VERSION "HNNBNNNYNNNNNNNNNNNNNNNNNNNNNNNNNNNNNNNNNN/4/%%%/4/'%**4NNN///"

NS_ :

BS_:

BU_: New_Node_10 BAP_Tester Fahrerdisplay_Kombi HUD ICAS1_X_Gateway ICAS3_Gateway ICC_IO_Node Kombi SmartLight_01 ZR_MIB_TOP_ab_Gen3

BO_ 1153 MainUnit_01: 8 ICAS3_Gateway
 SG_ ZR_LoGeWa_Event_Kombiwarnung : 0|4@1+ (1,0) [0|15] ""  ICAS1_X_Gateway,Kombi
 SG_ Nav_FoD_Status : 4|3@1+ (1,0) [0|7] ""  ICAS1_X_Gateway,Kombi
 SG_ MIB_ASW_Diagnose : 7|1@1+ (1,0) [0|1] ""  ICAS1_X_Gateway
 SG_ ZR_Lichter_Tag : 8|1@1+ (1,0) [0|1] ""  ICAS1_X_Gateway
 SG_ MIB_Tongenerator_PH_verfuegbar : 9|3@1+ (1,0) [0|7] ""  ICAS1_X_Gateway
 SG_ MMI_Counter_Bedienevent : 12|4@1+ (1,0) [0|15] ""  ICAS1_X_Gateway
 SG_ DSSS_Warning : 16|5@1+ (1,0) [0|31] ""  ICAS1_X_Gateway
 SG_ ZR_Kindersicherung_RSE : 21|1@1+ (1,0) [0|1] ""  ICAS1_X_Gateway
 SG_ ZR_RSE_aktivieren : 22|1@1+ (1,0) [0|1] ""  ICAS1_X_Gateway
 SG_ MMI_SDS_aktiv : 23|1@1+ (1,0) [0|1] ""  ICAS1_X_Gateway
 SG_ MU_SecondDisplay : 24|3@1+ (1,0) [0|7] ""  ICAS1_X_Gateway
 SG_ MMI_Telefon_aktiv : 27|1@1+ (1,0) [0|1] ""  ICAS1_X_Gateway
 SG_ MMI_Gurt_Mic_ref : 28|1@1+ (1,0) [0|1] ""  ICAS1_X_Gateway
 SG_ ZR_AppConnect_Zustand : 31|1@1+ (1,0) [0|1] ""  ICAS1_X_Gateway
 SG_ MU_Update_Time : 32|8@1+ (0.1,0) [0|25.5] "Unit_Hours"  ICAS1_X_Gateway
 SG_ HMI_WLC1_Systemzustand_intern : 40|3@1+ (1,0) [0|7] ""  ICAS1_X_Gateway
 SG_ HMI_WLC2_Systemzustand_intern : 43|3@1+ (1,0) [0|7] ""  ICAS1_X_Gateway
 SG_ ZR_Parken_Sondermodus : 48|4@1+ (1,0) [0|15] ""  ICAS1_X_Gateway
 SG_ INF_Nachlaufzeit : 52|10@1+ (1,0) [0|509] "Unit_Minut"  ICAS1_X_Gateway

BO_ 1639 Mem_BFS_01: 8 ICAS1_X_Gateway
 SG_ BFS_Fond_Bed_Ack : 12|1@1+ (1,0) [0|1] "" Vector__XXX
 SG_ BFS_Lehne_nicht_verriegelt : 13|1@1+ (1,0) [0|1] "" Vector__XXX
 SG_ BFS_Klapptisch_offen : 14|1@1+ (1,0) [0|1] "" Vector__XXX
 SG_ BFS_Gurtbringer_Sperre : 15|1@1+ (1,0) [0|1] "" Vector__XXX
 SG_ BFS_Sitzsym_Fahrt_aktiv : 16|1@1+ (1,0) [0|1] "" Vector__XXX
 SG_ BFS_Sitzfahrt_aktiv : 17|1@1+ (1,0) [0|1] "" Vector__XXX
 SG_ BFS_SLV_aktiv : 18|1@1+ (1,0) [0|1] "" Vector__XXX
 SG_ BFS_SHV_aktiv : 19|1@1+ (1,0) [0|1] "" Vector__XXX
 SG_ BFS_LNV_aktiv : 20|1@1+ (1,0) [0|1] "" Vector__XXX
 SG_ BFS_SNV_aktiv : 21|1@1+ (1,0) [0|1] "" Vector__XXX
 SG_ BFS_KSV_aktiv : 22|1@1+ (1,0) [0|1] "" Vector__XXX
 SG_ BFS_LKV_aktiv : 23|1@1+ (1,0) [0|1] "" Vector__XXX
 SG_ BFS_STV_aktiv : 24|1@1+ (1,0) [0|1] "" Vector__XXX
 SG_ BFS_LHV_aktiv : 25|1@1+ (1,0) [0|1] "" Vector__XXX
 SG_ BFS_LWV_aktiv : 26|1@1+ (1,0) [0|1] "" Vector__XXX
 SG_ BFS_GHV_aktiv : 27|1@1+ (1,0) [0|1] "" Vector__XXX
 SG_ BFS_KSS_Fahrt_aktiv : 28|1@1+ (1,0) [0|1] "" Vector__XXX
 SG_ BFS_MMB_lokal_Stop : 29|1@1+ (1,0) [0|1] "" Vector__XXX
 SG_ BFS_Ruhestellung_Status : 30|1@1+ (1,0) [0|1] "" Vector__XXX
 SG_ BFS_Seat_Locked : 31|1@1+ (1,0) [0|1] "" Vector__XXX
 SG_ BFS_MMB_storage : 32|4@1+ (1,0) [0|15] "" Vector__XXX
 SG_ BFS_MMB_tipp : 36|1@1+ (1,0) [0|1] "" Vector__XXX
 SG_ BFS_MMB_tast : 37|1@1+ (1,0) [0|1] "" Vector__XXX
 SG_ BFS_MMB_store_LED_on : 38|1@1+ (1,0) [0|1] "" Vector__XXX
 SG_ BFS_MMB_storage_beep : 39|1@1+ (1,0) [0|1] ""  Kombi
 SG_ BFS_MMB_store : 40|1@1+ (1,0) [0|1] "" Vector__XXX
 SG_ BFS_MMB_glob_stop : 41|1@1+ (1,0) [0|1] "" Vector__XXX
 SG_ BFS_FSV_ausgeklappt : 42|1@1+ (1,0) [0|1] "" Vector__XXX

BO_ 1178 Mem_FS_01: 8 ICAS1_X_Gateway
 SG_ FS_Fond_Bed_enable : 12|1@1+ (1,0) [0|1] "" Vector__XXX
 SG_ FS_Lehne_nicht_verriegelt : 13|1@1+ (1,0) [0|1] "" Vector__XXX
 SG_ FS_Spezialposition_anfahren : 14|1@1+ (1,0) [0|1] "" Vector__XXX
 SG_ FS_Gurtbringer_Sperre : 15|1@1+ (1,0) [0|1] "" Vector__XXX
 SG_ FS_BFS_Sitzsym_Anfahrt : 16|1@1+ (1,0) [0|1] "" Vector__XXX
 SG_ FS_Sitzfahrt_aktiv : 17|1@1+ (1,0) [0|1] "" Vector__XXX
 SG_ FS_SLV_aktiv : 18|1@1+ (1,0) [0|1] "" Vector__XXX
 SG_ FS_SHV_aktiv : 19|1@1+ (1,0) [0|1] "" Vector__XXX
 SG_ FS_LNV_aktiv : 20|1@1+ (1,0) [0|1] "" Vector__XXX
 SG_ FS_SNV_aktiv : 21|1@1+ (1,0) [0|1] "" Vector__XXX
 SG_ FS_KSV_aktiv : 22|1@1+ (1,0) [0|1] "" Vector__XXX
 SG_ FS_LKV_aktiv : 23|1@1+ (1,0) [0|1] "" Vector__XXX
 SG_ FS_STV_aktiv : 24|1@1+ (1,0) [0|1] "" Vector__XXX
 SG_ FS_LHV_aktiv : 25|1@1+ (1,0) [0|1] "" Vector__XXX
 SG_ FS_LWV_aktiv : 26|1@1+ (1,0) [0|1] "" Vector__XXX
 SG_ FS_GHV_aktiv : 27|1@1+ (1,0) [0|1] "" Vector__XXX
 SG_ FS_BFS_KSS_Anfahrt : 28|1@1+ (1,0) [0|1] "" Vector__XXX
 SG_ FS_MMB_lokal_Stop : 29|1@1+ (1,0) [0|1] "" Vector__XXX
 SG_ FS_MMB_storage : 32|4@1+ (1,0) [0|15] "" Vector__XXX
 SG_ FS_MMB_tipp : 36|1@1+ (1,0) [0|1] "" Vector__XXX
 SG_ FS_MMB_tast : 37|1@1+ (1,0) [0|1] "" Vector__XXX
 SG_ FS_MMB_store_LED_on : 38|1@1+ (1,0) [0|1] "" Vector__XXX
 SG_ FS_MMB_storage_beep : 39|1@1+ (1,0) [0|1] ""  Kombi
 SG_ FS_MMB_store : 40|1@1+ (1,0) [0|1] "" Vector__XXX
 SG_ FS_MMB_glob_stop : 41|1@1+ (1,0) [0|1] "" Vector__XXX
 SG_ FS_EE_Fond_FS_enable : 42|1@1+ (1,0) [0|1] "" Vector__XXX
 SG_ FS_EE_Fond_BFS_enable : 43|1@1+ (1,0) [0|1] "" Vector__XXX
 SG_ FS_BFS_Fond_Verst_enable : 44|1@1+ (1,0) [0|1] "" Vector__XXX
 SG_ FS_EE_BFS_enable : 45|1@1+ (1,0) [0|1] "" Vector__XXX

BO_ 1171 MFG_01: 8 ICAS1_X_Gateway
 SG_ MFG_01_CRC : 0|8@1+ (1,0) [0|255] "" Vector__XXX
 SG_ MFG_01_BZ : 8|4@1+ (1,0) [0|15] "" Vector__XXX
 SG_ MF_ZV_Lock : 12|1@1+ (1,0) [0|1] "" Vector__XXX
 SG_ MF_Motorweiterlauf : 13|1@1+ (1,0) [0|1] "" Vector__XXX
 SG_ MF_Abzugssperre : 14|1@1+ (1,0) [0|1] "" Vector__XXX
 SG_ MF_Anlassersperre : 15|1@1+ (1,0) [0|1] "" Vector__XXX
 SG_ MF_Variante : 16|3@1+ (1,0) [0|7] "" Vector__XXX
 SG_ MF_Schluessel_scan : 19|1@1+ (1,0) [0|1] "" Vector__XXX
 SG_ MF_Laderelais : 20|1@1+ (1,0) [0|1] "" Vector__XXX
 SG_ MF_StartStopp_Info : 21|2@1+ (1,0) [0|3] "" Vector__XXX
 SG_ MF_Fernbed_ein : 23|1@1+ (1,0) [0|1] "" Vector__XXX
 SG_ MF_Standlicht : 24|1@1+ (1,0) [0|1] "" Vector__XXX
 SG_ MF_Fahrlicht : 25|1@1+ (1,0) [0|1] "" Vector__XXX
 SG_ MF_interm_Fernlicht : 26|1@1+ (1,0) [0|1] "" Vector__XXX
 SG_ MF_Warnblinker : 27|1@1+ (1,0) [0|1] "" Vector__XXX
 SG_ MF_Fussraumbel : 28|1@1+ (1,0) [0|1] "" Vector__XXX
 SG_ MF_Innenraumbel : 29|1@1+ (1,0) [0|1] "" Vector__XXX
 SG_ MF_Innenraumbel_Unterdrueck : 30|1@1+ (1,0) [0|1] ""  SmartLight_01
 SG_ MF_Notstart : 31|1@1+ (1,0) [0|1] "" Vector__XXX
 SG_ MF_Blk_li : 32|1@1+ (1,0) [0|1] "" Vector__XXX
 SG_ MF_Blk_re : 33|1@1+ (1,0) [0|1] "" Vector__XXX
 SG_ MF_Lichthupe : 34|1@1+ (1,0) [0|1] "" Vector__XXX
 SG_ MF_Fernlicht : 35|1@1+ (1,0) [0|1] "" Vector__XXX
 SG_ MF_HFS_verriegeln : 36|1@1+ (1,0) [0|1] "" Vector__XXX
 SG_ MF_HFS_entriegeln : 37|1@1+ (1,0) [0|1] "" Vector__XXX
 SG_ MF_HBFS_verriegeln : 38|1@1+ (1,0) [0|1] "" Vector__XXX
 SG_ MF_HBFS_entriegeln : 39|1@1+ (1,0) [0|1] "" Vector__XXX
 SG_ MF_Tippwischen : 40|1@1+ (1,0) [0|1] "" Vector__XXX
 SG_ MF_Frontintervall : 41|1@1+ (1,0) [0|1] "" Vector__XXX
 SG_ MF_Wischerstufe_1 : 42|1@1+ (1,0) [0|1] "" Vector__XXX
 SG_ MF_Wischerstufe_2 : 43|1@1+ (1,0) [0|1] "" Vector__XXX
 SG_ MF_Frontwaschen : 44|1@1+ (1,0) [0|1] "" Vector__XXX
 SG_ MF_nachtr_Stopp_Anf : 45|1@1+ (1,0) [0|1] "" Vector__XXX
 SG_ MF_Heckintervall : 46|1@1+ (1,0) [0|1] "" Vector__XXX
 SG_ MF_Heckwaschen : 47|1@1+ (1,0) [0|1] "" Vector__XXX
 SG_ MF_Summer : 48|1@1+ (1,0) [0|1] ""  Kombi
 SG_ MF_Alarm_Blinkertakt : 49|1@1+ (1,0) [0|1] "" Vector__XXX
 SG_ MF_Alarm_Blinker : 50|1@1+ (1,0) [0|1] "" Vector__XXX
 SG_ MF_TFL_Abschaltung : 51|1@1+ (1,0) [0|1] "" Vector__XXX
 SG_ MF_interm_Takt : 52|1@1+ (1,0) [0|1] "" Vector__XXX
 SG_ MF_Tuerentriegelung_hinten : 53|1@1+ (1,0) [0|1] "" Vector__XXX
 SG_ MF_interm_Fahrlicht : 54|1@1+ (1,0) [0|1] "" Vector__XXX
 SG_ MF_Signalhorn : 55|1@1+ (1,0) [0|1] "" Vector__XXX
 SG_ MF_FH_FT_hoch : 56|1@1+ (1,0) [0|1] "" Vector__XXX
 SG_ MF_FH_FT_tief : 57|1@1+ (1,0) [0|1] "" Vector__XXX
 SG_ MF_FH_BT_hoch : 58|1@1+ (1,0) [0|1] "" Vector__XXX
 SG_ MF_FH_BT_tief : 59|1@1+ (1,0) [0|1] "" Vector__XXX
 SG_ MF_FT_verriegeln : 60|1@1+ (1,0) [0|1] "" Vector__XXX
 SG_ MF_FT_entriegeln : 61|1@1+ (1,0) [0|1] "" Vector__XXX
 SG_ MF_BT_verriegeln : 62|1@1+ (1,0) [0|1] "" Vector__XXX
 SG_ MF_BT_entriegeln : 63|1@1+ (1,0) [0|1] "" Vector__XXX

BO_ 1164 MFG_03: 8 ICAS1_X_Gateway
 SG_ MFG_Klappe_Status : 13|3@1+ (1,0) [0|7] "" Vector__XXX
 SG_ MF_Radiomute : 27|1@1+ (1,0) [0|1] ""  ICAS3_Gateway
 SG_ MF_Relais_2_Batterie : 28|1@1+ (1,0) [0|1] "" Vector__XXX
 SG_ MF_Batteriediagnose : 29|3@1+ (1,0) [0|7] "" Vector__XXX
 SG_ MFG_AppConnect_Anf : 32|2@1+ (1,0) [0|3] "" Vector__XXX
 SG_ MF_Lampenausfall : 34|1@1+ (1,0) [0|1] "" Vector__XXX
 SG_ MF_Blinker_L_Sta : 35|1@1+ (1,0) [0|1] "" Vector__XXX
 SG_ MF_Blinker_R_Sta : 36|1@1+ (1,0) [0|1] "" Vector__XXX
 SG_ MF_interm_Nebelscheinwerfer : 37|1@1+ (1,0) [0|1] "" Vector__XXX
 SG_ MF_Generatordiagnose : 38|2@1+ (1,0) [0|3] "" Vector__XXX
 SG_ MF_Heck_entriegeln : 40|1@1+ (1,0) [0|1] "" Vector__XXX
 SG_ MF_Heck_verriegeln : 41|1@1+ (1,0) [0|1] "" Vector__XXX
 SG_ MF_2BatSOCzugering : 42|1@1+ (1,0) [0|1] "" Vector__XXX
 SG_ MF_Fahrerhinweis : 43|3@1+ (1,0) [0|7] "" Vector__XXX
 SG_ MF_ZV_Unlock : 46|1@1+ (1,0) [0|1] "" Vector__XXX
 SG_ MF_Tuerverriegelung_hinten : 47|1@1+ (1,0) [0|1] "" Vector__XXX
 SG_ MF_2BattAb : 48|1@1+ (1,0) [0|1] "" Vector__XXX
 SG_ MF_2BattHlkAnf : 49|1@1+ (1,0) [0|1] "" Vector__XXX
 SG_ MF_2BattLadWarn : 50|1@1+ (1,0) [0|1] "" Vector__XXX
 SG_ MF_2BattLlaAnf : 51|1@1+ (1,0) [0|1] "" Vector__XXX
 SG_ MF_2BattSpannungsAnf : 52|2@1+ (1,0) [0|3] "" Vector__XXX
 SG_ MF_NotStartAktiv : 54|1@1+ (1,0) [0|1] "" Vector__XXX
 SG_ MF_ExterneLadungWarn : 55|1@1+ (1,0) [0|1] "" Vector__XXX
 SG_ MF_LSH_Zielzeit : 56|4@1+ (10,0) [0|130] "Unit_Minut" Vector__XXX
 SG_ MF_LSH_Abschaltstufe : 60|3@1+ (1,0) [0|7] "" Vector__XXX
 SG_ MF_LSH_Einschaltverbot : 63|1@1+ (1,0) [0|1] "" Vector__XXX

BO_ 817 MFL_01: 8 ICAS1_X_Gateway
 SG_ MFL_Zaehler : 0|4@1+ (1,0) [0|15] "" Vector__XXX
 SG_ MFL_Toggle : 4|1@1+ (1,0) [0|1] "" Vector__XXX
 SG_ MFL_Lokalaktiv : 5|1@1+ (1,0) [0|1] "" Vector__XXX
 SG_ MFL_M_Taste : 6|1@1+ (1,0) [0|1] "" Vector__XXX
 SG_ MFL_Paddle_Verbau : 7|1@1+ (1,0) [0|1] ""  Kombi
 SG_ MFL_Tastencode_1 : 8|8@1+ (1,0) [0|255] "" Vector__XXX
 SG_ MFL_Tastencode_2 : 16|8@1+ (1,0) [0|255] "" Vector__XXX
 SG_ MFL_Eventcode_1 : 24|4@1+ (1,0) [0|15] "" Vector__XXX
 SG_ MFL_Eventcode_2 : 28|4@1+ (1,0) [0|15] "" Vector__XXX
 SG_ MFL_Marke : 32|4@1+ (1,0) [0|15] "" Vector__XXX
 SG_ MFL_Variante : 36|4@1+ (1,0) [0|15] "" Vector__XXX
 SG_ MFL_Dummy_0_Signal_1 : 40|8@1+ (1,0) [0|255] "" Vector__XXX
 SG_ MFL_Tip_Down : 48|1@1+ (1,0) [0|1] "" Vector__XXX
 SG_ MFL_Tip_Up : 49|1@1+ (1,0) [0|1] "" Vector__XXX
 SG_ MFL_SatModul_links_Err : 50|1@1+ (1,0) [0|1] "" Vector__XXX
 SG_ MFL_SatModul_rechts_Err : 51|1@1+ (1,0) [0|1] "" Vector__XXX
 SG_ MFL_Fehler_Codierung : 52|1@1+ (1,0) [0|1] "" Vector__XXX
 SG_ MFL_Dummy_0_Signal_3 : 53|1@1+ (1,0) [0|1] "" Vector__XXX
 SG_ MFL_LR_HZG_Status : 54|1@1+ (1,0) [0|1] "" Vector__XXX
 SG_ MFL_LR_HZG_Err : 55|1@1+ (1,0) [0|1] "" Vector__XXX
 SG_ MFL_Signalhorn : 56|1@1+ (1,0) [0|1] "" Vector__XXX
 SG_ MFL_Signalhorn_Err : 57|1@1+ (1,0) [0|1] "" Vector__XXX
 SG_ MFL_Tip_links_Err : 58|1@1+ (1,0) [0|1] "" Vector__XXX
 SG_ MFL_Tip_rechts_Err : 59|1@1+ (1,0) [0|1] "" Vector__XXX
 SG_ MFL_Taste_links_Err : 60|1@1+ (1,0) [0|1] "" Vector__XXX
 SG_ MFL_Taste_rechts_Err : 61|1@1+ (1,0) [0|1] "" Vector__XXX
 SG_ MFL_ECU_Err : 62|1@1+ (1,0) [0|1] "" Vector__XXX
 SG_ MFL_Response_Err : 63|1@1+ (1,0) [0|1] "" Vector__XXX

BO_ 560 MFL_02: 8 ICAS1_X_Gateway
 SG_ MFL_Beruehrungserkennung : 12|2@1+ (1,0) [0|3] ""  ICAS3_Gateway
 SG_ MFL_Touch_Event : 14|4@1+ (1,0) [0|15] ""  ICAS3_Gateway

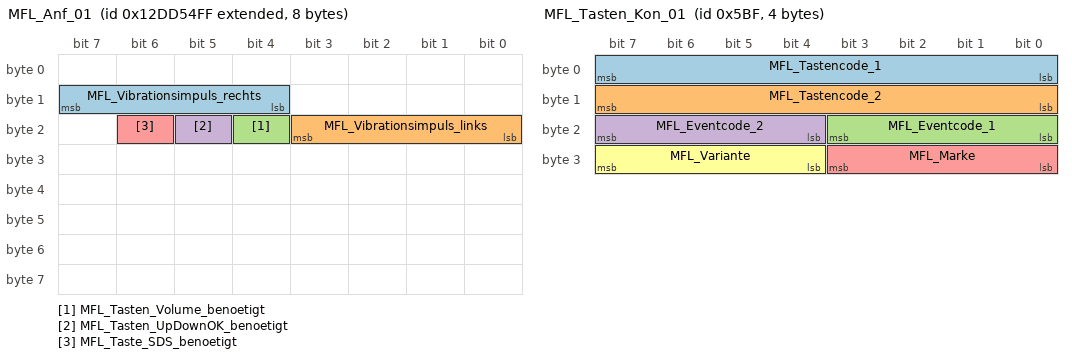
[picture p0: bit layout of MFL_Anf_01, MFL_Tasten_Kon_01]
BO_ 2463978751 MFL_Anf_01: 8 ICAS3_Gateway
 SG_ MFL_Vibrationsimpuls_rechts : 12|4@1+ (1,0) [0|15] ""  ICAS1_X_Gateway
 SG_ MFL_Vibrationsimpuls_links : 16|4@1+ (1,0) [0|15] ""  ICAS1_X_Gateway
 SG_ MFL_Tasten_Volume_benoetigt : 20|1@1+ (1,0) [0|1] ""  ICAS1_X_Gateway
 SG_ MFL_Tasten_UpDownOK_benoetigt : 21|1@1+ (1,0) [0|1] ""  ICAS1_X_Gateway
 SG_ MFL_Taste_SDS_benoetigt : 22|1@1+ (1,0) [0|1] ""  ICAS1_X_Gateway

BO_ 1471 MFL_Tasten_Kon_01: 4 ICAS1_X_Gateway
 SG_ MFL_Tastencode_1 : 0|8@1+ (1,0) [0|255] ""  ICAS3_Gateway,ICC_IO_Node,Kombi,ZR_MIB_TOP_ab_Gen3
 SG_ MFL_Tastencode_2 : 8|8@1+ (1,0) [0|255] ""  ICAS3_Gateway,ICC_IO_Node,Kombi,ZR_MIB_TOP_ab_Gen3
 SG_ MFL_Eventcode_1 : 16|4@1+ (1,0) [0|15] ""  ICAS3_Gateway,ICC_IO_Node,Kombi,ZR_MIB_TOP_ab_Gen3
 SG_ MFL_Eventcode_2 : 20|4@1+ (1,0) [0|15] ""  ICAS3_Gateway,ICC_IO_Node,Kombi,ZR_MIB_TOP_ab_Gen3
 SG_ MFL_Marke : 24|4@1+ (1,0) [0|15] ""  ICAS3_Gateway,ICC_IO_Node,Kombi,ZR_MIB_TOP_ab_Gen3
 SG_ MFL_Variante : 28|4@1+ (1,0) [0|15] ""  ICAS3_Gateway,ICC_IO_Node,Kombi,ZR_MIB_TOP_ab_Gen3

BO_ 958 Motor_14: 8 ICAS1_X_Gateway
 SG_ Motor_14_CRC : 0|8@1+ (1,0) [0|255] "" Vector__XXX
 SG_ Motor_14_BZ : 8|4@1+ (1,0) [0|15] "" Vector__XXX
 SG_ MO_StartStopp_Status : 12|2@1+ (1,0) [0|3] "" Vector__XXX
 SG_ MO_StartStopp_Wiederstart : 14|1@1+ (1,0) [0|1] ""  ZR_MIB_TOP_ab_Gen3
 SG_ MO_StartStopp_Motorstopp : 15|1@1+ (1,0) [0|1] "" Vector__XXX
 SG_ MO_Freig_Reku : 16|2@1+ (1,0) [0|3] "" Vector__XXX
 SG_ MO_Kl_75 : 18|1@1+ (1,0) [0|1] ""  ZR_MIB_TOP_ab_Gen3
 SG_ MO_Kl_50 : 19|1@1+ (1,0) [0|1] ""  ZR_MIB_TOP_ab_Gen3
 SG_ MO_Gangposition : 20|4@1+ (1,0) [0|15] "" Vector__XXX
 SG_ MO_StartStopp_Fahrerwunsch : 24|2@1+ (1,0) [0|3] "" Vector__XXX
 SG_ MO_HYB_Fahrbereitschaft : 26|1@1+ (1,0) [0|1] ""  ICAS3_Gateway,Kombi
 SG_ MO_Ext_E_Fahrt_aktiv : 27|1@1+ (1,0) [0|1] "" Vector__XXX
 SG_ MO_Fahrer_bremst : 28|1@1+ (1,0) [0|1] ""  ZR_MIB_TOP_ab_Gen3
 SG_ MO_QBit_Fahrer_bremst : 29|1@1+ (1,0) [0|1] ""  ZR_MIB_TOP_ab_Gen3
 SG_ MO_BLS : 30|1@1+ (1,0) [0|1] "" Vector__XXX
 SG_ MO_Konsistenz_Bremsped : 31|1@1+ (1,0) [0|1] "" Vector__XXX
 SG_ MO_Timeout_ESP : 32|1@1+ (1,0) [0|1] "" Vector__XXX
 SG_ MO_Klima_Eingr : 33|2@1+ (1,0) [0|3] "" Vector__XXX
 SG_ MO_Aussp_Anlass : 35|1@1+ (1,0) [0|1] "" Vector__XXX
 SG_ MO_Freig_Anlass : 36|1@1+ (1,0) [0|1] "" Vector__XXX
 SG_ MO_Kuppl_schalter : 37|1@1+ (1,0) [0|1] "" Vector__XXX
 SG_ MO_Interlock : 38|1@1+ (1,0) [0|1] "" Vector__XXX
 SG_ MO_Motor_laeuft : 39|1@1+ (1,0) [0|1] "" Vector__XXX
 SG_ MO_Kickdown : 40|1@1+ (1,0) [0|1] ""  ZR_MIB_TOP_ab_Gen3
 SG_ MO_QBit_KL_75 : 41|1@1+ (1,0) [0|1] "" Vector__XXX
 SG_ MO_EKlKomLeiRed : 42|2@1+ (1,0) [0|3] "" Vector__XXX
 SG_ MO_Handshake_STH : 44|1@1+ (1,0) [0|1] "" Vector__XXX
 SG_ MO_BKV_Unterdruckwarnung : 45|1@1+ (1,0) [0|1] "" Vector__XXX
 SG_ MO_Freigabe_Segeln : 46|1@1+ (1,0) [0|1] "" Vector__XXX
 SG_ MO_PTC_Status : 47|3@1+ (1,0) [0|7] "" Vector__XXX
 SG_ MO_QBit_Gangposition : 50|1@1+ (1,0) [0|1] "" Vector__XXX
 SG_ MO_Signalquelle_Gangposition : 51|1@1+ (1,0) [0|1] "" Vector__XXX
 SG_ MO_Remotestart_Betrieb : 52|1@1+ (1,0) [0|1] "" Vector__XXX
 SG_ MO_Remotestart_moeglich : 53|1@1+ (1,0) [0|1] "" Vector__XXX
 SG_ MO_FMAus_aktiv : 55|1@1+ (1,0) [0|1] "" Vector__XXX
 SG_ MO_FMAus_Startvariante : 56|2@1+ (1,0) [0|3] "" Vector__XXX
 SG_ MO_BMS_NV_Anf_stuetzen : 58|1@1+ (1,0) [0|1] "" Vector__XXX
 SG_ MO_Zylinderabschaltung : 59|2@1+ (1,0) [0|3] "" Vector__XXX
 SG_ MO_HYB_VM_aktiv : 61|1@1+ (1,0) [0|1] "" Vector__XXX
 SG_ MO_StartVorauss_erfuellt : 62|2@1+ (1,0) [0|3] "" Vector__XXX

BO_ 1648 Motor_18: 8 ICAS1_X_Gateway
 SG_ MO_max_Ladedruck : 0|6@1+ (0.1,0) [0|6.3] "Unit_Bar" Vector__XXX
 SG_ MO_ANC_Kennfeld_Anf : 6|2@1+ (1,0) [0|3] "" Vector__XXX
 SG_ MO_Bremslicht_Reku : 8|1@1+ (1,0) [0|1] "" Vector__XXX
 SG_ MO_StartStopp_PopUp : 9|2@1+ (1,0) [0|3] "" Vector__XXX
 SG_ MO1_Sperr_Info_WFS : 11|1@1+ (1,0) [0|1] "" Vector__XXX
 SG_ MO1_Freigabe_Info_WFS : 12|1@1+ (1,0) [0|1] "" Vector__XXX
 SG_ MO_EPCL : 13|3@1+ (1,0) [0|7] ""  Fahrerdisplay_Kombi,Kombi
 SG_ MO_Zylabsch_Texte_02 : 16|4@1+ (1,0) [0|15] "" Vector__XXX
 SG_ MO_Fahrzeugtyp : 20|3@1+ (1,0) [0|7] ""  Fahrerdisplay_Kombi,Kombi
 SG_ MO_NMAX_Schaltanzeige : 23|9@1+ (25,0) [0|12775] "Unit_MinutInver" Vector__XXX
 SG_ MO_Abstellzeit : 32|8@1+ (8,0) [0|2024] "Unit_Minut" Vector__XXX
 SG_ MO_Abstellzeit_Status : 40|2@1+ (1,0) [0|3] "" Vector__XXX
 SG_ MO1_Freigabe_Verfallsinfo_WFS : 42|1@1+ (1,0) [0|1] "" Vector__XXX
 SG_ MO_Hybrid_StartStopp_LED : 43|2@1+ (1,0) [0|3] "" Vector__XXX
 SG_ MO_Fehler_Zylabsch : 45|2@1+ (1,0) [0|3] "" Vector__XXX
 SG_ MO_Anzahl_Abgesch_Zyl : 47|3@1+ (1,0) [0|7] "" Vector__XXX
 SG_ MO_Zylabsch_Texte : 50|2@1+ (1,0) [0|3] "" Vector__XXX
 SG_ MO_Ethanol_BS_Texte : 52|3@1+ (1,0) [0|7] "" Vector__XXX
 SG_ MO_Drehzahl_Warnung : 55|1@1+ (1,0) [0|1] "" Vector__XXX
 SG_ MO_obere_Drehzahlgrenze : 56|8@1+ (50,0) [50|12750] "Unit_MinutInver" Vector__XXX

BO_ 967 Motor_26: 8 ICAS1_X_Gateway
 SG_ MO_Kuehlerluefter_MUX M : 0|1@1+ (1,0) [0|1] "" Vector__XXX
 SG_ MO_Kuehlerluefter_1 m0 : 1|7@1+ (1,0) [0|100] "Unit_PerCent" Vector__XXX
 SG_ MO_Kuehlerluefter_2 m1 : 1|7@1+ (1,0) [0|100] "Unit_PerCent" Vector__XXX
 SG_ MO_EFLEX_Lampe : 8|2@1+ (1,0) [0|3] "" Vector__XXX
 SG_ MO_KJS_nicht_bereit : 10|1@1+ (1,0) [0|1] "" Vector__XXX
 SG_ MO_ITM_Warnung_Pumpe : 11|1@1+ (1,0) [0|1] "" Vector__XXX
 SG_ WIV_Anzeige_aktiv : 12|1@1+ (1,0) [0|1] "" Vector__XXX
 SG_ WIV_Oelmin_Warn : 13|1@1+ (1,0) [0|1] "" Vector__XXX
 SG_ WIV_Sensorfehler : 14|1@1+ (1,0) [0|1] "" Vector__XXX
 SG_ WIV_Schieflage : 15|1@1+ (1,0) [0|1] "" Vector__XXX
 SG_ WIV_Oelstand : 16|4@1+ (12.5,0) [0|100] "Unit_PerCent" Vector__XXX
 SG_ MO_Zustand_HWP : 20|2@1+ (1,0) [0|3] "" Vector__XXX
 SG_ OLEV_Systemstoerung : 22|1@1+ (1,0) [0|1] "" Vector__XXX
 SG_ MO_Oelwarnung_max : 23|1@1+ (1,0) [0|1] "" Vector__XXX
 SG_ WIV_Oelsystem_aktiv : 24|1@1+ (1,0) [0|1] "" Vector__XXX
 SG_ WIV_nicht_betriebswarm : 25|1@1+ (1,0) [0|1] "" Vector__XXX
 SG_ WIV_Ueberfuell_Warn : 26|1@1+ (1,0) [0|1] "" Vector__XXX
 SG_ WIV_laufender_Motor : 27|1@1+ (1,0) [0|1] "" Vector__XXX
 SG_ MO_E_Warnungen : 28|4@1+ (1,0) [0|15] "" Vector__XXX
 SG_ MO_Text_Motorstart : 32|4@1+ (1,0) [0|15] "" Vector__XXX
 SG_ MO_E_Texte : 36|4@1+ (1,0) [0|15] "" Vector__XXX
 SG_ WIV_Oeldyn_avl : 40|1@1+ (1,0) [0|1] "" Vector__XXX
 SG_ MO_Text_Partikelfil_Reg : 41|1@1+ (1,0) [0|1] "" Vector__XXX
 SG_ OLEV_Oelstand_nicht_vorhanden : 42|1@1+ (1,0) [0|1] "" Vector__XXX
 SG_ WIV_Oelmenge : 43|5@1+ (125,0) [0|3875] "Unit_MilliLiter" Vector__XXX
 SG_ MO_Systemlampe : 48|1@1+ (1,0) [0|1] "" Vector__XXX
 SG_ MO_OBD2_Lampe : 49|1@1+ (1,0) [0|1] ""  Fahrerdisplay_Kombi,Kombi
 SG_ MO_Heissleuchte : 50|1@1+ (1,0) [0|1] "" Vector__XXX
 SG_ MO_Partikel_Lampe : 51|1@1+ (1,0) [0|1] "" Vector__XXX
 SG_ MO_RedFahrleistung_Lampe : 52|1@1+ (1,0) [0|1] ""  Kombi
 SG_ WIV_Oelstand_nicht_vorhanden : 53|1@1+ (1,0) [0|1] "" Vector__XXX
 SG_ WIV_nachfuellanzeige_ein : 54|1@1+ (1,0) [0|1] "" Vector__XXX
 SG_ WIV_Ueberfuell_deaktiv : 55|1@1+ (1,0) [0|1] "" Vector__XXX
 SG_ WIV_Unterfuell_Warn : 56|1@1+ (1,0) [0|1] "" Vector__XXX
 SG_ MO_Tankdeckel_Lampe : 57|1@1+ (1,0) [0|1] "" Vector__XXX
 SG_ MO_Text_Tankdeckelwarn : 58|1@1+ (1,0) [0|1] "" Vector__XXX
 SG_ MO_Vorglueh_Lampe : 59|1@1+ (1,0) [0|1] "" Vector__XXX
 SG_ WIV_Oeldr_Warn_Motor : 60|1@1+ (1,0) [0|1] "" Vector__XXX
 SG_ MO_E_Mode : 61|3@1+ (1,0) [0|7] "" Vector__XXX

BO_ 966 Motor_26_SOK_Signatur: 8 ICAS1_X_Gateway
 SG_ SOK_Motor_26_Signatur : 0|64@1+ (1,0) [0|1.84467440737096E+19] "" Vector__XXX

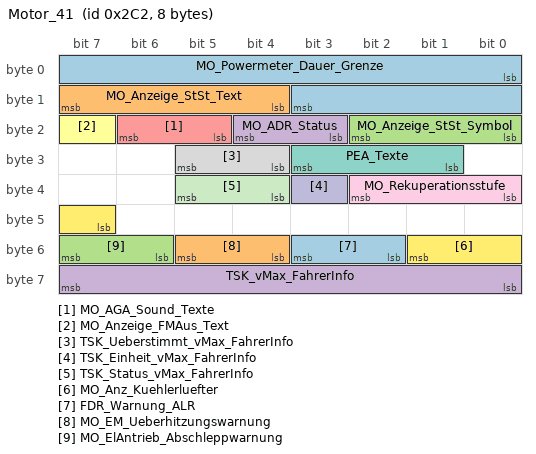
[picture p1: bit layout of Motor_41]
BO_ 706 Motor_41: 8 ICAS1_X_Gateway
 SG_ MO_Powermeter_Dauer_Grenze : 0|12@1+ (1,0) [0|4093] "Unit_None" Vector__XXX
 SG_ MO_Anzeige_StSt_Text : 12|4@1+ (1,0) [0|15] "" Vector__XXX
 SG_ MO_Anzeige_StSt_Symbol : 16|3@1+ (1,0) [0|7] "" Vector__XXX
 SG_ MO_ADR_Status : 19|2@1+ (1,0) [0|3] "" Vector__XXX
 SG_ MO_AGA_Sound_Texte : 21|2@1+ (1,0) [0|3] "" Vector__XXX
 SG_ MO_Anzeige_FMAus_Text : 23|1@1+ (1,0) [0|1] "" Vector__XXX
 SG_ PEA_Texte : 25|3@1+ (1,0) [0|7] "" Vector__XXX
 SG_ TSK_Ueberstimmt_vMax_FahrerInfo : 28|2@1+ (1,0) [0|3] "" Vector__XXX
 SG_ MO_Rekuperationsstufe : 32|3@1+ (1,0) [0|7] ""  Kombi
 SG_ TSK_Einheit_vMax_FahrerInfo : 35|1@1+ (1,0) [0|1] "" Vector__XXX
 SG_ TSK_Status_vMax_FahrerInfo : 36|2@1+ (1,0) [0|3] "" Vector__XXX
 SG_ MO_Anz_Kuehlerluefter : 47|3@1+ (1,0) [0|7] "" Vector__XXX
 SG_ FDR_Warnung_ALR : 50|2@1+ (1,0) [0|3] ""  Kombi
 SG_ MO_EM_Ueberhitzungswarnung : 52|2@1+ (1,0) [0|3] ""  Kombi
 SG_ MO_ElAntrieb_Abschleppwarnung : 54|2@1+ (1,0) [0|3] ""  Kombi
 SG_ TSK_vMax_FahrerInfo : 56|8@1+ (1,15) [16|270] "" Vector__XXX

BO_ 267 Motor_51_Auth: 48 ICAS1_X_Gateway
 SG_ Motor_51_CRC : 0|8@1+ (1,0) [0|255] "" Vector__XXX
 SG_ Motor_51_BZ : 8|4@1+ (1,0) [0|15] "" Vector__XXX
 SG_ MO_Fahrpedalrohwert_01 : 12|8@1+ (0.4,0) [0|101.6] "Unit_PerCent"  ZR_MIB_TOP_ab_Gen3
 SG_ MO_QBit_Fahrpedalwerte_01 : 20|1@1+ (1,0) [0|1] "" Vector__XXX
 SG_ MO_Fahrpedalgradient : 21|8@1+ (25,0) [0|6350] "Unit_PerCentPerSecon" Vector__XXX
 SG_ MO_Sig_Fahrpedalgradient : 29|1@1+ (1,0) [0|1] "" Vector__XXX
 SG_ MO_rel_Saugrohrdruck : 30|6@1+ (18,0) [0|1116] "Unit_MilliBar" Vector__XXX
 SG_ MO_rel_Saugrohrdruck_gem_err : 36|1@1+ (1,0) [0|1] "" Vector__XXX
 SG_ MO_Moment_im_Leerlauf : 37|1@1+ (1,0) [0|1] "" Vector__XXX
 SG_ MO_Schubabschaltung : 38|1@1+ (1,0) [0|1] "" Vector__XXX
 SG_ MO_StartStopp_StoppVorbereitung : 39|1@1+ (1,0) [0|1] "" Vector__XXX
 SG_ MO_Solldrehz_Leerlauf : 40|8@1+ (10,0) [0|2540] "Unit_MinutInver" Vector__XXX
 SG_ MO_Entkopplung_Sollschlupf : 48|7@1+ (20,0) [0|2480] "Unit_MinutInver" Vector__XXX
 SG_ MO_temporaere_Fahrerabwesenheit : 55|1@1+ (1,0) [0|1] "" Vector__XXX
 SG_ TSK_a_Soll_gradientenbegrenzt : 57|7@1+ (0.1,-7.2) [-7.2|5.4] "Unit_MeterPerSeconSquar" Vector__XXX
 SG_ TSK_Radbremsmom : 76|12@1+ (8,0) [0|32760] "Unit_NewtoMeter" Vector__XXX
 SG_ TSK_Status : 88|3@1+ (1,0) [0|7] "" Vector__XXX
 SG_ TSK_v_Begrenzung_aktiv : 91|1@1+ (1,0) [0|1] "" Vector__XXX
 SG_ TSK_Standby_Anf_ESP : 92|1@1+ (1,0) [0|1] "" Vector__XXX
 SG_ TSK_Freig_Verzoeg_Anf : 94|1@1+ (1,0) [0|1] "" Vector__XXX
 SG_ TSK_Limiter_ausgewaehlt : 95|1@1+ (1,0) [0|1] "" Vector__XXX
 SG_ TSK_Hauptschalter_GRA_ACC : 106|2@1+ (1,0) [0|3] ""  Kombi
 SG_ TSK_SRBM_Anf_ASIL : 108|3@1+ (1,0) [0|7] "" Vector__XXX
 SG_ TSK_ax_Getriebe_02 : 112|9@1+ (0.024,-2.016) [-2.016|10.224] "Unit_MeterPerSeconSquar" Vector__XXX
 SG_ TSK_Zwangszusch_ESP : 121|1@1+ (1,0) [0|1] "" Vector__XXX
 SG_ TSK_zul_Regelabw : 122|6@1+ (0.024,0) [0|1.512] "Unit_MeterPerSeconSquar" Vector__XXX
 SG_ TSK_Radsollmoment : 128|16@1+ (0.5,-16383) [-16383|16383.5] "Unit_NewtoMeter" Vector__XXX
 SG_ TSK_Kategorie_Verzoegerungsfkt : 144|2@1+ (1,0) [0|3] "" Vector__XXX
 SG_ TSK_Notstopp_Anf : 233|2@1+ (1,0) [0|3] "" Vector__XXX
 SG_ MO_Status_MinDrzEingriff : 235|3@1+ (1,0) [0|7] "" Vector__XXX
 SG_ MO_Status_MaxDrzEingriff : 238|3@1+ (1,0) [0|7] "" Vector__XXX
 SG_ MO_Status_MinDrzEingriff_sek : 241|3@1+ (1,0) [0|7] "" Vector__XXX
 SG_ MO_Status_MaxDrzEingriff_sek : 244|3@1+ (1,0) [0|7] "" Vector__XXX
 SG_ TSK_SRBM_max_Gradient : 248|7@1+ (50,0) [0|6250] "Unit_NewtoMeterPerSecon" Vector__XXX
 SG_ SOK_Motor_51_Signatur : 352|32@1+ (1,0) [0|4294967295] "" Vector__XXX

BO_ 330 Motor_52: 32 ICAS1_X_Gateway
 SG_ Motor_52_CRC : 0|8@1+ (1,0) [0|255] ""  Kombi
 SG_ Motor_52_BZ : 8|4@1+ (1,0) [0|15] ""  Kombi
 SG_ MO_Hochschaltdrehz : 21|12@1+ (3,0) [3|12282] "Unit_MinutInver" Vector__XXX
 SG_ MO_Anzeige_Verbr_Einheit : 33|2@1+ (1,0) [0|3] "" Vector__XXX
 SG_ MO_Schaltblitz_Anz : 35|7@1+ (1,0) [0|100] "Unit_PerCent" Vector__XXX
 SG_ MO_Anzeige_Drehmoment : 42|11@1+ (1,0) [0|2045] "Unit_NewtoMeter" Vector__XXX
 SG_ MO_Anzeige_Leistung : 53|11@1+ (0.6,0) [0|1227] "Unit_KiloWatt" Vector__XXX
 SG_ MO_rel_Ladedruck : 64|8@1+ (0.4,0) [0|100] "Unit_PerCent" Vector__XXX
 SG_ MO_Istgang : 72|4@1+ (1,0) [0|15] "" Vector__XXX
 SG_ MO_Sollgang : 76|4@1+ (1,0) [0|15] "" Vector__XXX
 SG_ MO_Oeldruck : 80|8@1+ (0.04,0) [0|10] "Unit_Bar" Vector__XXX
 SG_ MO_Anzeigedrehz : 88|12@1+ (3,0) [0|12282] "Unit_MinutInver" Vector__XXX
 SG_ MO_Effizienzmodus : 100|1@1+ (1,0) [0|1] "" Vector__XXX
 SG_ MO_Fehler_Oeldrucksensor : 101|1@1+ (1,0) [0|1] "" Vector__XXX
 SG_ MO_Schaltempf_verfbar : 102|1@1+ (1,0) [0|1] "" Vector__XXX
 SG_ MO_Ladedruck : 103|9@1+ (0.01,0) [0|5.1] "Unit_Bar" Vector__XXX
 SG_ MO_KVS : 112|15@1+ (1,0) [0|32767] "Unit_MicroLiter" Vector__XXX
 SG_ MO_KVS_Ueberlauf : 127|1@1+ (1,0) [0|1] "" Vector__XXX
 SG_ MO_ePowermeter : 128|8@1+ (0.4,-0.4) [0|100.8] "Unit_PerCent" Vector__XXX
 SG_ MO_ePerformance : 136|8@1+ (0.4,-0.4) [0|100.8] "Unit_PerCent"  Kombi
 SG_ MO_Zust_Antrieb : 144|4@1+ (1,0) [0|15] "" Vector__XXX
 SG_ MO_Zust_Betriebsstrategie : 148|3@1+ (1,0) [0|7] "" Vector__XXX
 SG_ Ladezustand_02 : 152|8@1+ (0.5,0) [0|100] "Unit_PerCent"  Kombi,ZR_MIB_TOP_ab_Gen3
 SG_ Ladezustand_gering : 160|2@1+ (1,0) [0|3] ""  Kombi
 SG_ MO_Powermeter_Elm_02 : 168|12@1+ (0.05,-102.4) [-100|100] "Unit_PerCent" Vector__XXX
 SG_ MO_Powermeter : 180|12@1+ (1,0) [0|4092] ""  Kombi
 SG_ MO_OnePedalDriving_Warnung : 192|2@1+ (1,0) [0|3] ""  Fahrerdisplay_Kombi,Kombi

BO_TX_BU_ 1153 : ICAS3_Gateway,ZR_MIB_TOP_ab_Gen3;
CM_ SG_ 1153 ZR_LoGeWa_Event_Kombiwarnung "Event für Kombiwarnung";
CM_ SG_ 1153 Nav_FoD_Status "FoD Status der Navigation";
CM_ SG_ 1153 MIB_ASW_Diagnose "Diagnose Rückmeldung vom MIB zu Heckradar Entry. ASW Warnton Verfügbarkeit.";
CM_ SG_ 1153 ZR_Lichter_Tag "Berechnete Kennzeichnung des Sonnenstandes über bzw. oder unter Horizont.";
CM_ SG_ 1153 MIB_Tongenerator_PH_verfuegbar "Verfügbarkeit des Tongenerators im MIB für die Nutzung durch die Parkhilfe";
CM_ SG_ 1153 MMI_Counter_Bedienevent "Signal wird inkrementiert, wenn Bedienevent stattgefunden hat.";
CM_ SG_ 1153 DSSS_Warning "DSSS - Driving Safety Support System Meldungen";
CM_ SG_ 1153 ZR_Kindersicherung_RSE "Sperren der Rearseat Unit (Komplette Weckfähigkeit)";
CM_ SG_ 1153 ZR_RSE_aktivieren "Weckfähigkeit der RSE";
CM_ SG_ 1153 MMI_SDS_aktiv "Signal wird gesetzt, solange die Sprachbedienung aktiv ist.";
CM_ SG_ 1153 MU_SecondDisplay "Dient zur Überwachung der zweiten LVDS Leitung.";
CM_ SG_ 1153 MMI_Gurt_Mic_ref "Referenzsignal für das Gurtmikrofon Steuergerät zur Signalisierung ob der Downlink aktiv oder inaktiv ist";
CM_ SG_ 1153 ZR_AppConnect_Zustand "Ist Zustand des AppConnect Kontextes im MIB";
CM_ SG_ 1153 MU_Update_Time "Ermöglicht auslesen der Historiendaten, wann ein Update lief";
CM_ SG_ 1153 HMI_WLC1_Systemzustand_intern "Übertragung der HMI Einstellung für den WLC1 Systemzustand";
CM_ SG_ 1153 HMI_WLC2_Systemzustand_intern "Übertragung der HMI Einstellung für den WLC2 Systemzustand";
CM_ SG_ 1153 ZR_Parken_Sondermodus "Rückkanal zum pilotierten Parken zur Signalisierung Status Sondermodus";
CM_ SG_ 1153 INF_Nachlaufzeit "signal from ICAS3 to ICAS1 to request a prolonged shutdown of HV";
CM_ BO_ 1639 "MLBevo";
CM_ SG_ 1639 BFS_Fond_Bed_Ack "Bestätigung Beifahrersitzverstellung vom Fond";
CM_ SG_ 1639 BFS_Lehne_nicht_verriegelt "Fahrer Sitz Lehne Verstellung Verriegelt Status

Verwendung nur im  Bentley";
CM_ SG_ 1639 BFS_Klapptisch_offen "Signalisiert eine Verstelleinschränkung des Beifahrersitz  (für BAP Visualisierung)";
CM_ SG_ 1639 BFS_Gurtbringer_Sperre "Freigabesignal für den Gurtzubringer";
CM_ SG_ 1639 BFS_Sitzsym_Fahrt_aktiv "Sitzsymetriefahrt
";
CM_ SG_ 1639 BFS_Sitzfahrt_aktiv "Aktive Sitzfahrt";
CM_ SG_ 1639 BFS_SLV_aktiv "Sitzlängsverstellung
";
CM_ SG_ 1639 BFS_SHV_aktiv "Sitzhöhenverstellung
";
CM_ SG_ 1639 BFS_LNV_aktiv "Verstellung Lehnenneigung
";
CM_ SG_ 1639 BFS_SNV_aktiv "Verstellung Sitzneigung
";
CM_ SG_ 1639 BFS_KSV_aktiv "Kopfstuetzenverstellung BFS
";
CM_ SG_ 1639 BFS_LKV_aktiv "Verstellung Lehnenkopf
";
CM_ SG_ 1639 BFS_STV_aktiv "Sitztiefeverstellung
";
CM_ SG_ 1639 BFS_LHV_aktiv "Verstellung Lordose Höhe
";
CM_ SG_ 1639 BFS_LWV_aktiv "Lordose W Verstellung
";
CM_ SG_ 1639 BFS_GHV_aktiv "Verstellung Gurthoehe
";
CM_ SG_ 1639 BFS_KSS_Fahrt_aktiv "Komfortseitensichtfahrt (BFS)";
CM_ SG_ 1639 BFS_MMB_lokal_Stop "mit dem lokal Stop moechte man, dass ein Sitz mit Pneumatik - Lordose sich im Memoryfall wie ein Sitz mit elektromechanischer Lordose verhaelt. Nur lokler Abbruch im TIP-Betrieb.";
CM_ SG_ 1639 BFS_Ruhestellung_Status "dient der Signalisierung für eine Verstelleinschränkung, da der Sitz sich in Ruhestellung befindet.";
CM_ SG_ 1639 BFS_Seat_Locked "Anzeige des gesperrten Beifahrersitzes aufgrund ungültiger Sitzposition.";
CM_ SG_ 1639 BFS_MMB_storage "Speichern auf Memoryposition";
CM_ SG_ 1639 BFS_MMB_tipp "Memoryverstellung im Tippbetrieb";
CM_ SG_ 1639 BFS_MMB_tast "Memoryverstellung im Tastbetrieb";
CM_ SG_ 1639 BFS_MMB_store_LED_on "LED für Speichern
";
CM_ SG_ 1639 BFS_MMB_storage_beep "Quittierungston Sitzmemory BFS (Anforderung Kombi)

";
CM_ SG_ 1639 BFS_MMB_store "Speichern der Sitzposition
";
CM_ SG_ 1639 BFS_MMB_glob_stop "Abbruch Memoryverstellung";
CM_ SG_ 1639 BFS_FSV_ausgeklappt "Zustandssignalisierung der el. mech. Fußstütze (eingeklappt oder ausgeklappt)";
CM_ BO_ 1178 "ab MQB 7.2";
CM_ SG_ 1178 FS_Fond_Bed_enable "Freigabe für Fondsitzverstellungen";
CM_ SG_ 1178 FS_Lehne_nicht_verriegelt "Fahrer Sitz Lehne Verstellung Verriegelt Status

Verwendung nur im Bentley";
CM_ SG_ 1178 FS_Spezialposition_anfahren "paralell zu diesem Signal wird eine Botschaft auf den KCAN gesendet in der spezielle Anforderungen für den Empfänger stehen. 
Dieses Signal dient zusätzlich der Checksummenabsicherung bei einer Remotverstellung ";
CM_ SG_ 1178 FS_Gurtbringer_Sperre "Freigabesignal für den Gurtzubringer";
CM_ SG_ 1178 FS_BFS_Sitzsym_Anfahrt "Sitzsymetrie Anfahrt BFS";
CM_ SG_ 1178 FS_Sitzfahrt_aktiv "Aktive Sitzfahrt Fahrersitz
";
CM_ SG_ 1178 FS_SLV_aktiv "Sitzlängsverstellung
";
CM_ SG_ 1178 FS_SHV_aktiv "Verstellung Sitzhöhe

";
CM_ SG_ 1178 FS_LNV_aktiv "Verstellung Lehnenneigung
";
CM_ SG_ 1178 FS_SNV_aktiv "Verstellung Sitzneigung
";
CM_ SG_ 1178 FS_KSV_aktiv "Verstellung Kopfstütze
";
CM_ SG_ 1178 FS_LKV_aktiv "Verstellung Lehnenkopf
";
CM_ SG_ 1178 FS_STV_aktiv "Verstellung Sitztiefe
";
CM_ SG_ 1178 FS_LHV_aktiv "Verstellung Lordose Höhe
";
CM_ SG_ 1178 FS_LWV_aktiv "Verstellung Lordose W
";
CM_ SG_ 1178 FS_GHV_aktiv "Verstellung Gurthöhe
";
CM_ SG_ 1178 FS_BFS_KSS_Anfahrt "Komfortseitensicht Anfahrt BFS";
CM_ SG_ 1178 FS_MMB_lokal_Stop "mit dem lokal Stop moechte man, dass ein Sitz mit Pneumatik - Lordose sich im Memoryfall wie ein Sitz mit elektromechanischer Lordose verhaelt. Nur lokler Abbruch im TIP-Betrieb.";
CM_ SG_ 1178 FS_MMB_storage "Memory-Positionstaste, Funkschlüssel-Memory-ID, Benutzerkonto-Nummer";
CM_ SG_ 1178 FS_MMB_tipp "Memoryverstellung im Tippbetrieb";
CM_ SG_ 1178 FS_MMB_tast "Memoryverstellung im Tastbetrieb";
CM_ SG_ 1178 FS_MMB_store_LED_on "LED für Speichern
";
CM_ SG_ 1178 FS_MMB_storage_beep "Quittierungston Sitzmemory FS (Anforderung Kombi)";
CM_ SG_ 1178 FS_MMB_store "Memoryposition Speichern";
CM_ SG_ 1178 FS_MMB_glob_stop "Abbruch Memoryverstellung";
CM_ SG_ 1178 FS_EE_Fond_FS_enable "EE Fond links
";
CM_ SG_ 1178 FS_EE_Fond_BFS_enable "EE Fond rechts

";
CM_ SG_ 1178 FS_BFS_Fond_Verst_enable "Verstellung Fond (vom MMI)
";
CM_ SG_ 1178 FS_EE_BFS_enable "EasyEntry Freigabe für Befahrersitz.";
CM_ BO_ 1171 "ab MQB 7.2 gültig";
CM_ SG_ 1171 MFG_01_CRC "Für MLB:
'Berechnung siehe Lastenheft 'Kommunikationsabsicherung für FlexRay und CAN''

Ab MQB und MLBevo:
'Berechnung siehe Lastenheft 'End-to-End Kommunikationsabsicherung''

Endwerte siehe Begleitdokument 'S-PDU Kennungsfolgen'";
CM_ SG_ 1171 MFG_01_BZ "4bit Botschaftszähler, wird in jeder Sendebotschaft inkrementiert
";
CM_ SG_ 1171 MF_ZV_Lock "Verriegelungsanforderung durch MFG analog Meldung einer Locktasterbetätigung durch TSG.";
CM_ SG_ 1171 MF_Motorweiterlauf "Motorstop Behoerdenfahrzeug";
CM_ SG_ 1171 MF_Abzugssperre "Schlüsselabzugssperre";
CM_ SG_ 1171 MF_Anlassersperre "Notarzt 230V-Steckdose";
CM_ SG_ 1171 MF_Variante "Sonderfahrzeugvariante
0 = keine Sonderfunktion 
1 = Sondersignalfahrzeug
2 = Taxi 
3 = Fahrhilfe 
4 = Fahrschule+Extra 
5 = SSF
6 =  DBMC
7 = Arbeitsmaschine";
CM_ SG_ 1171 MF_Schluessel_scan "Anforderung eines Innenraumscans - Schlüsselsuche";
CM_ SG_ 1171 MF_Laderelais "Signal für die Auswertung zur Anzeige der Batterie-Schwach-Anzeige im Kombi";
CM_ SG_ 1171 MF_StartStopp_Info "Stopp-Freigabe und Start-Anforderung an den Start-Stopp-Koordinator";
CM_ SG_ 1171 MF_Fernbed_ein "Fernbedienung für Petri+Lehr; Versehrte und Fahrschule";
CM_ SG_ 1171 MF_Standlicht "statisch oder auch mit Blink_modi für Taxialarm";
CM_ SG_ 1171 MF_Fahrlicht "statisch oder auch mit Blink_modi für interm.  Fahrlicht";
CM_ SG_ 1171 MF_interm_Fernlicht "mit Blink_modi für SoSi oder Taxialarm";
CM_ SG_ 1171 MF_Warnblinker "Versehrte";
CM_ SG_ 1171 MF_Fussraumbel "Fussraumbeleuchtung, Fahrschule";
CM_ SG_ 1171 MF_Innenraumbel "sämtliche Beleuchtungen akitivieren (Fussraum, Tür u.a.)";
CM_ SG_ 1171 MF_Innenraumbel_Unterdrueck "Unterdrückung des Innenlichts/Fussraumbeleuchtung, sowie Schließblinken";
CM_ SG_ 1171 MF_Notstart "Signal zeigt an, dass ein Notstart über DBMC erfolgte.

Verwendung in Verbindung mit Signal MF_Variante = DBMC.";
CM_ SG_ 1171 MF_Blk_li "Versehrte oder Fahrschule; Prio über Fernbedienung ein";
CM_ SG_ 1171 MF_Blk_re "Versehrte oder Fahrschule; Prio über Fernbedienung ein";
CM_ SG_ 1171 MF_Lichthupe "Versehrte oder Fahrschule; Oder-Verknuepfung
";
CM_ SG_ 1171 MF_Fernlicht "Versehrte oder Fahrschule; Oder-Verknüpfung";
CM_ SG_ 1171 MF_HFS_verriegeln "Hinten Fahrertür verriegeln";
CM_ SG_ 1171 MF_HFS_entriegeln "Hinten Fahrertür entriegeln";
CM_ SG_ 1171 MF_HBFS_verriegeln "Hinten Beifahrertür verriegeln";
CM_ SG_ 1171 MF_HBFS_entriegeln "Hinten Beifahrertür entriegeln";
CM_ SG_ 1171 MF_Tippwischen "Versehrte oder Fahrschule; Oder-Verknüpfung";
CM_ SG_ 1171 MF_Frontintervall "Versehrte oder Fahrschule; Oder-Verknüpfung";
CM_ SG_ 1171 MF_Wischerstufe_1 "Versehrte oder Fahrschule; Oder-Verknüpfung";
CM_ SG_ 1171 MF_Wischerstufe_2 "Versehrte oder Fahrschule; Oder-Verknüpfung";
CM_ SG_ 1171 MF_Frontwaschen "Versehrte oder Fahrschule; Oder-Verknüpfung";
CM_ SG_ 1171 MF_nachtr_Stopp_Anf "Dieses Signal dient dem Motor als Trigger, dass ein nachträglicher Motorstopp eingeleitet werden kann, wenn es die Bedingungen des StSt Koordinators dies zulassen.";
CM_ SG_ 1171 MF_Heckintervall "Versehrte oder Fahrschule; Oder-Verknüpfung";
CM_ SG_ 1171 MF_Heckwaschen "Versehrte oder Fahrschule; Oder-Verknüpfung";
CM_ SG_ 1171 MF_Summer "Warnsummer für Funkhauptschalter und Fahrschulpedal";
CM_ SG_ 1171 MF_Alarm_Blinkertakt "Ansteuerung Blinker bei Alarm. Signal wird getaktet.
0 = Blinker für Alarm aus
1 = Blinker für Alarm ein";
CM_ SG_ 1171 MF_Alarm_Blinker "Taxialarmblinken, wie DWA ohne Fanfare";
CM_ SG_ 1171 MF_TFL_Abschaltung "Abschaltung des Tagfahrlicht
0 = keine Auswirkung
1 = Tagfahrlicht deaktiviert";
CM_ SG_ 1171 MF_interm_Takt "Taktung von intermittierenden Fernlicht/Fahrlicht bei einer Einsatzfahrt
0 = Licht aus
1 = Licht ein";
CM_ SG_ 1171 MF_Tuerentriegelung_hinten "Bei von innen verriegelten Fahrzeug Türen hinten entriegeln
0 = keine Auswirkung
1 = Türen hinten entriegeln
";
CM_ SG_ 1171 MF_interm_Fahrlicht "Ansteuerung intermittierendes Abblendlicht";
CM_ SG_ 1171 MF_Signalhorn "Versehrte, Fahrschule oder Taxi (bei Alarm)";
CM_ SG_ 1171 MF_FH_FT_hoch "Versehrte";
CM_ SG_ 1171 MF_FH_FT_tief "Versehrte";
CM_ SG_ 1171 MF_FH_BT_hoch "Versehrte";
CM_ SG_ 1171 MF_FH_BT_tief "Versehrte";
CM_ SG_ 1171 MF_FT_verriegeln "Fahrertür verriegeln";
CM_ SG_ 1171 MF_FT_entriegeln "Fahrertür entriegeln";
CM_ SG_ 1171 MF_BT_verriegeln "Beifahrertür verriegeln";
CM_ SG_ 1171 MF_BT_entriegeln "Beifahrertür entriegeln";
CM_ SG_ 1164 MFG_Klappe_Status "Einstellung der Luftklappenposition an der Luftstandheizung";
CM_ SG_ 1164 MF_Radiomute "Wird bei Sonderfahrzeugen wie Polizei dafür verwendet, um das Radio bei einem eingehenden Funkspruch zu muten.";
CM_ SG_ 1164 MF_Relais_2_Batterie "Zeigt den Zustand des vom KFG angesteuerten Laderelais einer verbauten 2. Batterie an";
CM_ SG_ 1164 MF_Batteriediagnose "Erstellt für Zusatzbatterie Crafter";
CM_ SG_ 1164 MFG_AppConnect_Anf "AppConnect Anforderung durch das KFG";
CM_ SG_ 1164 MF_Lampenausfall "Meldung Lampenausfall Aufbauhersteller";
CM_ SG_ 1164 MF_Blinker_L_Sta "Status Blinker links Sonderaufbauten";
CM_ SG_ 1164 MF_Blinker_R_Sta "Status Blinker rechts Sonderaufbauten";
CM_ SG_ 1164 MF_interm_Nebelscheinwerfer "Intermittierender Nebelscheinwerfer bei einer Einsatzfahrt";
CM_ SG_ 1164 MF_Generatordiagnose "Neu erstellt für Crafter";
CM_ SG_ 1164 MF_Heck_entriegeln "Entriegelung Heck über KFG";
CM_ SG_ 1164 MF_Heck_verriegeln "Verriegelung Heck über KFG";
CM_ SG_ 1164 MF_2BatSOCzugering "Anzeige bei geringer Ladung der Zweitbatterie";
CM_ SG_ 1164 MF_Fahrerhinweis "Fahrerhinweis Kombiinstrument";
CM_ SG_ 1164 MF_ZV_Unlock "Globales entriegeln über KFG";
CM_ SG_ 1164 MF_Tuerverriegelung_hinten "Internes Verriegeln der hinteren Türen";
CM_ SG_ 1164 MF_2BattAb "Batterie Ab Warnung der Zweitbatterie";
CM_ SG_ 1164 MF_2BattHlkAnf "Anforderung einer HLK - Stufe an das BEM";
CM_ SG_ 1164 MF_2BattLadWarn "Anzeige das bei Motorlauf die Zweitbatterie entladen wird im KI";
CM_ SG_ 1164 MF_2BattLlaAnf "Anforderung einer Drehzahlanhebung an das BEM";
CM_ SG_ 1164 MF_2BattSpannungsAnf "Mindestspannugnsanforderung der Zusatbatterie an den BEM";
CM_ SG_ 1164 MF_NotStartAktiv "Anzeige Notstart Aktiv für den Zeitraum der Schließung des Notstartrelais";
CM_ SG_ 1164 MF_ExterneLadungWarn "Warnung bei Motorlauf das externer Ladestecker gesteckt ist im KI";
CM_ SG_ 1164 MF_LSH_Zielzeit "Definition der Zielzeit für die Luftstandheizung an der zweiten Batterie, Steuerung durch das Zweitbatterie EM im KFG.";
CM_ SG_ 1164 MF_LSH_Abschaltstufe "Abschaltstufen der Luftstandheizung an der Zweitbatterie. Das Signal dient der Steuerung des Klima SG an der ersten Batterie und der LSH an der zweiten Batterie durch das Zweitbatterie Em im KFG";
CM_ SG_ 1164 MF_LSH_Einschaltverbot "Statussignal für das Einschaltverbot der Luftstandheizung an der Zweitbatterie, Steuerung durch das Zweitbatterie EM im KFG.
0 volle Verfuegbarkeit Standheizung/-lueftung
1 Standheizung/-lueftung nicht aktivierbar";
CM_ SG_ 817 MFL_Toggle "Watchdog Toggle-Bit";
CM_ SG_ 817 MFL_Lokalaktiv "Zeigt an ob das SG nach Klemme15 AUS und nach entsprechender MAX Aktivzeit noch aktiv war";
CM_ SG_ 817 MFL_M_Taste "Taster für Umschaltung Automatik/manuelles Schalten (Tiptronic)";
CM_ SG_ 817 MFL_Paddle_Verbau "Signalisiert den Zustand des Tipp-Paddle-Verbaus";
CM_ SG_ 817 MFL_Tastencode_1 "Beschreibt die Funktion einer fest zugeordneten Taste/Walze auf dem MFL. Bei Betätigung ändert sich der Wert von 0x0 auf den jeweiligen Tastencode.";
CM_ SG_ 817 MFL_Tastencode_2 "Beschreibt die Funktion einer fest zugeordneten Taste/Walze auf dem MFL. Ist MFL_Tastencode_1 wegen Betätigung einer Taste/Walze bereits mit einem Wert ungleich 0x0 belegt, so ändert sich bei Betätigung einer weiteren Taste/Walze der Wert dieses Signals v";
CM_ SG_ 817 MFL_Eventcode_1 "Siehe Q-LAH MFL-Protokoll";
CM_ SG_ 817 MFL_Eventcode_2 "Siehe Q-LAH MFL-Protokoll";
CM_ SG_ 817 MFL_Marke "Marke für markenspezifische Variantennummer des MFL";
CM_ SG_ 817 MFL_Variante "Markenspezifische Variantennummer des MFL";
CM_ SG_ 817 MFL_Tip_Down "MFL-Tiptronic Tasten vom MFL für Getriebe
    0x0 = kein Tip_Down
    0x1 = Tip_Down";
CM_ SG_ 817 MFL_Tip_Up "MFL-Tiptronic Tasten vom MFL für Getriebe
    0x0 = kein Tip_Up
    0x1 = Tip_Up";
CM_ SG_ 817 MFL_SatModul_links_Err "Schalter Tastermodul links Fehler";
CM_ SG_ 817 MFL_SatModul_rechts_Err "Schalter Tastermodul rechts Fehler";
CM_ SG_ 817 MFL_Fehler_Codierung "Erkennung dass MFL nicht codiert ist.";
CM_ SG_ 817 MFL_LR_HZG_Status "Status Lenkradheizung";
CM_ SG_ 817 MFL_LR_HZG_Err "Lenkradheizung Fehler";
CM_ SG_ 817 MFL_Signalhorn "Signalhorn nicht betaetigt/betaetigt";
CM_ SG_ 817 MFL_Signalhorn_Err "Signalhorn Fehler";
CM_ SG_ 817 MFL_Tip_links_Err "Tiptronic links Fehler";
CM_ SG_ 817 MFL_Tip_rechts_Err "Tiptronic rechts Fehler";
CM_ SG_ 817 MFL_Taste_links_Err "MFL_Tastenblock links Fehler";
CM_ SG_ 817 MFL_Taste_rechts_Err "MFL_Tastenblock rechts Fehler";
CM_ SG_ 817 MFL_ECU_Err "MFL-µC Fehler";
CM_ SG_ 817 MFL_Response_Err "siehe LIN2.0-Specification
(Darf nicht über ein Fehlergueltigkeitsbit abgesichtert werden!)";
CM_ SG_ 560 MFL_Beruehrungserkennung "Das Signal beschreibt die Berührung der Bedieninseln des Touch-MFL (nicht berührt = Init, links, rechts oder beidseitig).";
CM_ SG_ 560 MFL_Touch_Event "Touch_Events für Informationen einer Funktionsauslösung auf dem MFL, welches dann für bspw. ein akustisches Signal zentral umgesetzt werden können.";
CM_ SG_ 2463978751 MFL_Vibrationsimpuls_rechts "Als haptisches Feedback zur Bedienung der MFL-Tasteninsel.
Wird zyklisch abgespielt, solange Signal anliegt. Die Zeit bis zu den nächsten vollen 100ms ist im MFL mit Pause gespeichert. Ist die Impulsanforderung kürzer als die Länge des Impulses, wird der";
CM_ SG_ 2463978751 MFL_Vibrationsimpuls_links "Für haptisches Feedback zur Bedienung der MFL-Tasteninsel.
Wird zyklisch abgespielt, solange Signal anliegt. Die Zeit bis zu den nächsten vollen 100ms ist im MFL mit Pause gespeichert. Ist die Impulsanforderung kürzer als die Länge des Impulses, wird der";
CM_ SG_ 2463978751 MFL_Tasten_Volume_benoetigt "Taste beleuchtet, Tastencodes werden gesendet";
CM_ SG_ 2463978751 MFL_Tasten_UpDownOK_benoetigt "Taste beleuchtet, Tastencodes werden gesendet";
CM_ SG_ 2463978751 MFL_Taste_SDS_benoetigt "Taste beleuchtet, Tastencode wird gesendet";
CM_ SG_ 1471 MFL_Tastencode_1 "Beschreibt die Funktion einer fest zugeordneten Taste/Walze auf dem MFL. Bei Betätigung ändert sich der Wert von 0x0 auf den jeweiligen Tastencode.";
CM_ SG_ 1471 MFL_Tastencode_2 "Beschreibt die Funktion einer fest zugeordneten Taste/Walze auf dem MFL. Ist MFL_Tastencode_1 wegen Betätigung einer Taste/Walze bereits mit einem Wert ungleich 0x0 belegt, so ändert sich bei Betätigung einer weiteren Taste/Walze der Wert dieses Signals v";
CM_ SG_ 1471 MFL_Eventcode_1 "Siehe Q-LAH MFL-Protokoll";
CM_ SG_ 1471 MFL_Eventcode_2 "Siehe Q-LAH MFL-Protokoll";
CM_ SG_ 1471 MFL_Marke "Marke für markenspezifische Variantennummer des MFL";
CM_ SG_ 1471 MFL_Variante "Markenspezifische Variantennummer des MFL";
CM_ SG_ 958 Motor_14_CRC "Ab MQB und MLBevo:
'Berechnung siehe Lastenheft 'End-to-End Kommunikationsabsicherung'

Endwerte siehe Begleitdokument 'S-PDU Kennungsfolgen'";
CM_ SG_ 958 MO_StartStopp_Status "Aktivitätsstatus Start/Stopp-Koordinator
HYBRID:
Wenn MO_Hybridfahrzeug = 1 gilt:
Signal bezieht sich nur auf den Verbrennungsmotor, nicht auf den Hybridantrieb
";
CM_ SG_ 958 MO_StartStopp_Wiederstart "Motorwiederstart durch Start/Stopp-Koordinator
HYBRID:
Wenn MO_Hybridfahrzeug =1 gilt:
Warnung vor Spannungseinbruch beim Zustart des Verbrennungsmotors. 
-nicht relevant, da derzeit kein Start über 12V-Starter geplant-
Dieses Signal wird nur vom Hyb";
CM_ SG_ 958 MO_StartStopp_Motorstopp "Motor-Stopp durch Start/Stopp-Koordinator
HYBRID:
Wenn MO_Hybridfahrzeug = 1 gilt:
Verbrennungsmotor durch Hybrid-Koordinator im MSG ausgeschaltet. 
Die definierten Start/Stopp-Signale beziehen sich nur auf den Verbrennungsmotor!";
CM_ SG_ 958 MO_Freig_Reku "Empfehlung des Motor-SG's zur Spannungsabsenkung/-anhebung für den Rekuperationsbetrieb";
CM_ SG_ 958 MO_Kl_75 "Klemme X
";
CM_ SG_ 958 MO_Kl_50 "Klemme 50: Startausführung durch Ritzelstarter

MLB: nicht von allen Motoren gesendet
MQB/MLBevo: gesendet von allen Motoren";
CM_ SG_ 958 MO_Gangposition "MLB:
Stellung des Wählhebels in der Schaltgasse des Handschaltgetriebes.
MLBevo: 
Ausweitung der Bedienung auch auf Automatikgetriebe;
Routing des Signals GE_Fahrstufe: 
1. Position_R (dez. 6) auf MO_Gangposition: Gang_R (dez. 13) wegen Entfall Signa";
CM_ SG_ 958 MO_StartStopp_Fahrerwunsch "Fahreraktivität Start/Stop";
CM_ SG_ 958 MO_HYB_Fahrbereitschaft "Signal steuert u.a. in der Lenkhilfe zusammen mit weiteren Informationen den Modewechsel in den 'Drivemode'
Grüne Anzeige im Kombiinstrument zur Signalisierung der Bereitschaft des Hybridsystems.";
CM_ SG_ 958 MO_Ext_E_Fahrt_aktiv "Funktionsrückmeldung zum erw. E-Fahr-Betrieb über Lampe/LED im E-Mode-Taster";
CM_ SG_ 958 MO_Fahrer_bremst "Redundante Bremsinformation vom Motor.

MLB:
AUDI D4: Zykluszeit: 10ms (siehe Zykluszeit schnell/Cycletime Fast)
Im AUDI B8 wird in diesem Bit der Wert der ESP-CAN-Information 'ESP_Fahrer_bremst' ausgegeben.

Achtung:
Reduktion der Zykluszeit Motor";
CM_ SG_ 958 MO_QBit_Fahrer_bremst "MLB:
AUDI D4: Zykluszeit: 10ms (siehe Zykluszeit schnell/Cycletime Fast)

Achtung:
Reduktion der Zykluszeit Motor_03 auf 10ms geplant.
Projektabhängig soll künftig mit 10ms gesendet werden.
Empfänger die in weiteren Konzern-Projekten eingesetzt werd";
CM_ SG_ 958 MO_BLS "Ungefiltertes Rohsignal des Bremslichtschalters, nur wenn HW-Eingang bestückt und ausgewertet wird. Bei Motoren ohne genutzten HW-Eingang wird kein Ersatzwert (bspw. SW-Signal über CAN) ausgegeben!
Bei AUDI muss das Signal wg. Bremslichtfunktion immer be";
CM_ SG_ 958 MO_Konsistenz_Bremsped "MLB:

AUDI D4: Zykluszeit: 10ms (siehe Zykluszeit schnell/Cycletime Fast)
Siehe 'Funktionsspezifikation Bremslichtinfo B8'

Achtung:
Reduktion der Zykluszeit Motor_03 auf 10ms geplant.
Projektabhängig soll künftig mit 10ms gesendet werden.
Empfäng";
CM_ SG_ 958 MO_Timeout_ESP "500 ms Timeout auf Bremsen-Botschaft ist >= 1 mal aufgelaufen, Löschen des Bits nach Neustart (KL15).

MLB:
AUDI D4: Zykluszeit: 10ms (siehe Zykluszeit schnell/Cycletime Fast)

Achtung:
Reduktion der Zykluszeit Motor_03 auf 10ms geplant.
Projektabh";
CM_ SG_ 958 MO_Klima_Eingr "Eingriffe des Motor bei der Klima";
CM_ SG_ 958 MO_Aussp_Anlass "Das Signal zeigt an, ob die Wiederholstartsperre aktiv ist. D. h. eine Ansteuerung des Anlassers wird auch bei erfüllten Startvoraussetzungen (HS: Interlock betätigt bzw. AT: P/N eingelegt und Bremse betätigt) nicht erfolgen.";
CM_ SG_ 958 MO_Freig_Anlass "Bit wird gesetzt, wenn der Motor beim Automatikstart gestartet werden darf (Motorstillstand, Emissionsmaßnahmen sind erfüllt).";
CM_ SG_ 958 MO_Kuppl_schalter "MLB:
Das Motorsteuergerät gibt die Information aus, ab wann der Kupplungsschalter durch das Motorsteuergerät als getreten gesehen wird
0x0: Schalter sagt betätigt (Ausgekuppelt)
0x1: Schalter sagt nicht betätigt (Eingekuppelt)

MQB:
Nur Handschalter";
CM_ SG_ 958 MO_Interlock "Das Motorsteuergerät gibt die Information aus, ab wann der Kupplungsschalter durch das Motorsteuergerät als getreten gesehen wird.
Bei Systemen für Start Stopp muss das Interlocksignal für einen Start durch das MSG generiert werden, sobald der Schalthebe";
CM_ SG_ 958 MO_Motor_laeuft "Das Motorsteuergerät gibt die Information aus, ab wann der Motor verbrennungsbedingt autark läuft und durch zuschaltbare Nebenaggregate mechanisch belastbar ist (z.B. durch Generator, Klimakompressor, etc.).

Die 'Motor läuft' Information wird ausgegebe";
CM_ SG_ 958 MO_Kickdown "Es gilt: Signalspec MO_Kickdown v1.0";
CM_ SG_ 958 MO_QBit_KL_75 "Q - Bit für das KL 75 Signal zur Vermeidung der fehlerhaften Erkennung von Motorstarts. 
Wird auf 1 gesetzt, solange das Motorsteuergerät KL15 = AUS erkannt hat.";
CM_ SG_ 958 MO_EKlKomLeiRed "Anforderung an die Klimasteuerung, die Leistungsaufnahme des E-Kompressors bei schlechtem SOC und in bestimmten Fahrsituationen zu begrenzen. (Das bereits bestehende Signal 'Klimakompressor aus' als stets umzusetzende Anforderung bleibt unverändert besteh";
CM_ SG_ 958 MO_Handshake_STH "Es gilt: Signalspec MO_Handshake v1.0

Handshake zwischen MSG und STH. Wenn das MSG die EKP aufgrund einer STH-Anforderung ansteuert und kein Fehlereintrag bzgl. EKP/KPE/NDR vorliegt, wird das Bit gesetzt.";
CM_ SG_ 958 MO_BKV_Unterdruckwarnung "Über die Unterdruckwarnung signalisiert das MSG dem ESP, dass kein ausreichender Unterdruck für den BKV zur Verfügung gestellt werden kann.";
CM_ SG_ 958 MO_Freigabe_Segeln "Freigabebit des Segelbetriebs im Getriebe. Bedingt durch bestimmte Diagnosen und Adaptionen des MSGs, die nur im Schub möglich sind, darf nicht jede Schubphase für einen Segelbetrieb genutzt werden. Eine Freigabe bleibt auch außerhalb einer Schubphase bes";
CM_ SG_ 958 MO_PTC_Status "Status-Rückmeldung vom MSG zum aktuellen PTC-Status (stufiges PTC, Relais am MSG). Bei Ansteuerung eines stufigen PTC durch ein anderes SG beschreibt das Signal die vom MSG freigegebene PTC-Stufe.";
CM_ SG_ 958 MO_QBit_Gangposition "Qualitätsbit zum Signal MO_Gangposition";
CM_ SG_ 958 MO_Signalquelle_Gangposition "Signalquelle des Signals MO_Gangposition
0: Signalquelle Gangpositionssensor
1: Signalquelle Modellwert (v/n)";
CM_ SG_ 958 MO_Remotestart_Betrieb "Das MSG ist für den Remotestart-Betrieb bereit. Nach Empfang der Motorstartanforderung für RSt-Betrieb durch BCM wird der Fahrzeugmotor gestartet und solange der Motor läuft, bleibt dieses Bit aktiv. Dieses Signal ist nur zur Verwendung durch das BCM zur ";
CM_ SG_ 958 MO_Remotestart_moeglich "Wenn Bit gesetzt, würde das MSG bei entsprechender Anforderung durch das BCM den Remotestartbetrieb einleiten, d.h. das MSG ist remotestartfähig und es liegen aktuell keine relevanten Fehler oder andere Abbruchgründe vor.";
CM_ SG_ 958 MO_FMAus_aktiv "Das Signal gibt Rückmeldung ob Freilauf Motor aus aktiv ist. Beleibt auch 0km/h (unterhalb der StartStopp Schwelle) weiterhin aktiv.";
CM_ SG_ 958 MO_FMAus_Startvariante "Startvariante beim Motorstart aus der Freilauf-Motor-AUS Phase";
CM_ SG_ 958 MO_BMS_NV_Anf_stuetzen "Garantierte Unterstützung des Zusatzspeichers ist erforderlich. Zusatzspeicher muss an das Versorgungsnezt angebunden werden. ";
CM_ SG_ 958 MO_Zylinderabschaltung "Status Zylinderabschaltung Motor";
CM_ SG_ 958 MO_HYB_VM_aktiv "0 = VMotor wird nicht aktiv gehalten (nVM < n_min und keine LL-Regelung aktiv)
1 = VMotor aktiv (ab der ersten Einspritzung; gilt auch für Schubbetrieb, wenn VMotor spätestens durch LLRegelung befeuert würde)
Verwendet zur Bestimmung des Ist-Zustandes";
CM_ SG_ 958 MO_StartVorauss_erfuellt "Dient der Fallunterscheidung bei ZAT-Betätigung im Zustand 'KL15 ein' (bei nicht gesetztem Signal folgt KL15 aus, bei gesetztem Signal folgt setzen KL50-Anf.)

0: Signal nicht bedient 
1: Voraussetzungen zur Antriebsstrangaktivierung / Startvoraussetzu";
CM_ BO_ 1648 "Kombischnittstelle";
CM_ SG_ 1648 MO_max_Ladedruck "maximal möglicher Ladedruck (zur Anpassung des Anzeigebereichs bei absoluter Ladedruckanzeige)";
CM_ SG_ 1648 MO_ANC_Kennfeld_Anf "Anforderung ANC Kennfeldumschaltung";
CM_ SG_ 1648 MO_Bremslicht_Reku "Bremslicht (ggf. bei Rekuperation durch E-Motor) wird angesteuert";
CM_ SG_ 1648 MO_StartStopp_PopUp "Das Signal zeigt an, ob der StSt-Status mittels Deaktivierungstaster geändert wurde. Ein Wechsel auf die Werte 01 oder 10 löst im Kombi ein entsprechendes PopUp aus. Bei einem Statuswechsel durch andere Signalquellen (z.B. Charisma, fehlerbedingte Abschal";
CM_ SG_ 1648 MO1_Sperr_Info_WFS "WFS-Sperrinformation";
CM_ SG_ 1648 MO1_Freigabe_Info_WFS "WFS-Freigabeinformation";
CM_ SG_ 1648 MO_EPCL "Die Anforderung der EPC-Lampe vom MSG ans Kombi soll durch das Bus-Signal MO_EPCL gemäß folgender Logik erfolgen:
MO_EPCL = 0 dez -> EPC Lampe aus, kein Text
MO_EPCL = 1 dez -> gelbe EPC-Symbolik, Text „Antrieb: Störung! Bitte Service aufsuchen“
MO_EPC";
CM_ SG_ 1648 MO_Zylabsch_Texte_02 "ZAS-Anzeige für den Fahrer im Kombi
0: kein ZAS (generell keinerlei ZAS-Anzeigen)  (Init für nicht ZAS-Motor)
1: ZAS im Vollmotorbetrieb  (Init für ZAS-Motor)
2: ZAS im Abschaltbetrieb: 1 Zyl aktiv
3: ZAS im Abschaltbetrieb: 2 Zyl aktiv
4: ZAS im Abs";
CM_ SG_ 1648 MO_Fahrzeugtyp "Unterscheidet die Fahrzeugtypen bzgl. der Antriebsart";
CM_ SG_ 1648 MO_NMAX_Schaltanzeige "Maximaldrehzahl für Schaltanzeige";
CM_ SG_ 1648 MO_Abstellzeit "Abstelldauer nach letztem KL15 aus

Hinweis: 
Ehemaliger Fehlerwert 0xFF wird senderseitig nicht unterstützt. 
Diesen Wert aus Kompatibilitätsgründen nicht neu belegen!";
CM_ SG_ 1648 MO_Abstellzeit_Status "Statusinformation zur Abstellzeit
0: Die dem Status zugeordnete Variable konnte noch nicht berechnet werden. 
1: Die dem Status zugehörige Variable wurde korrekt berechnet. 
2: Der Wert der zugehörigen Variablen ist nur ein Minimalwert. 
3: Der Wert d";
CM_ SG_ 1648 MO1_Freigabe_Verfallsinfo_WFS "WFS-Freigabeverfallsinformation";
CM_ SG_ 1648 MO_Hybrid_StartStopp_LED "Ansteuerung der Funktions-LED der Hybrid Taste bzw. Start/Stop Deaktivierungstaste.
Der Start/Stopp-Master (derzeit im MSG) (oder ein künftiger Hybrid-Master) soll die Ansteuerung senden.";
CM_ SG_ 1648 MO_Fehler_Zylabsch "Fehlerstatus der Funktion Zylinderabschaltung ";
CM_ SG_ 1648 MO_Anzahl_Abgesch_Zyl "Gibt die Anzahl der abgeschalteten Zylinder an. In Übergangszuständen wird der Zielbetriebszustand angezeigt.";
CM_ SG_ 1648 MO_Zylabsch_Texte "Zylinderabschaltung mode in Kombi, fuer Zylinderabschaltung";
CM_ SG_ 1648 MO_Ethanol_BS_Texte "Ethanol Brennstoff-Texte im Kombi

0 = kein Text
1 = E85 Warm_Up
2 = FlexFuel Warnung 3.Stufe (Too cold for ethanol)
3 = Warmfahrempfehlung MQB / FlexFuel Warnung 1.Stufe (Refuel with gasoline)
4 = FlexFuel Warnung 2. Stufe (Refuel with gasoline)
5";
CM_ SG_ 1648 MO_Drehzahl_Warnung "Warnhinweis zum Kombi im Fall einer fehlerbehafteten Drehzahlbegrenzung";
CM_ SG_ 1648 MO_obere_Drehzahlgrenze "obere Drehzahlgrenze des Motors";
CM_ BO_ 967 "MQB - vorher Motor_06 / Umbenennung wg. ID-Wechsel";
CM_ SG_ 967 MO_Kuehlerluefter_MUX "Multiplexer für das Signal 'MO_Kuehlerlüfter'";
CM_ SG_ 967 MO_Kuehlerluefter_1 "Ansteuertastverhaeltnis (PWM) der Kuehlerluefterendstufe 1";
CM_ SG_ 967 MO_Kuehlerluefter_2 "Ansteuertastverhaeltnis (PWM) der Kuehlerluefterendstufe 2";
CM_ SG_ 967 MO_EFLEX_Lampe "Um ein Starten mit E100 zu ermöglichen, wird Kraftstoff ggf. vorgeheizt. Das Signal dient der Anzeige des Heizungsstatus.

Heizung aus -> Lampe aus
Heizung ein -> Lampe ein
Heizung ein und Startversuch -> Lampe blinkend
Heizung nicht möglich -> Lampe";
CM_ SG_ 967 MO_KJS_nicht_bereit "Dieses Signal zeigen einen Fehler der Kühlerjalousie mit unbekannter Stellung der Lamellen. ";
CM_ SG_ 967 MO_ITM_Warnung_Pumpe "Textanzeige: 'Motor sofort abstellen, geschaltete Wasserpumpe defekt / klemmt'";
CM_ SG_ 967 WIV_Anzeige_aktiv "Peilstabsanzeigefunktion aktiv";
CM_ SG_ 967 WIV_Oelmin_Warn "Signal gibt an wenn der Ölstand die Min-Schwelle unterschritten hat";
CM_ SG_ 967 WIV_Sensorfehler "Ölstand/Öltemperatursensor (TOG) defekt";
CM_ SG_ 967 WIV_Schieflage "Fahrzeug steht nicht waagerecht, Messung ungenau";
CM_ SG_ 967 WIV_Oelstand "8 Segmente zur Balkenanzeige des Ölstands";
CM_ SG_ 967 MO_Zustand_HWP "Rückmeldung des  Ansteuerzustand der Hauptwasserpumpe an das Klima-SG .
Der Zustand 'HWP fördert' wird übermittelt, wenn die Schaufeln der Hauptwasserpumpe frei drehen können und die Motordrehzahl und damit die Wasserpumpendrehzahl größer als Null ist. B";
CM_ SG_ 967 OLEV_Systemstoerung "Systemstörung im Ölsystem";
CM_ SG_ 967 MO_Oelwarnung_max "Ölstandswarnung mit der Aufforderung zum Ölwechsel.
Hintergrund: Bei Kraftstoffeintrag (B20) ins Öl verbleibt der RME-Anteil irreversibel im Öl.";
CM_ SG_ 967 WIV_Oelsystem_aktiv "Gesamtölsystem aktiv (entspricht Ölsensor verbaut) und das Ölstand-Untermenu im MMI aktiv";
CM_ SG_ 967 WIV_nicht_betriebswarm "Motor nicht betriebswarm, Messung ungenau";
CM_ SG_ 967 WIV_Ueberfuell_Warn "Ölstand hat die Überfüllschwelle überschritten";
CM_ SG_ 967 WIV_laufender_Motor "Messung bei laufendem Motor nicht möglich";
CM_ SG_ 967 MO_E_Warnungen "Anforderung von Warnanzeigen des E-Systems separat für HEV/BEV bzw. erweiterbar für PHEV";
CM_ SG_ 967 MO_Text_Motorstart "Anzeigetexte für Start/Stopp und Motor-Start
0xB Fehler_Kupplungsschalter nur für PAG-MLB";
CM_ SG_ 967 MO_E_Texte "Anforderung von Hinweistexten des E-Systems separat für HEV/BEV bzw. erweiterbar für PHEV";
CM_ SG_ 967 WIV_Oeldyn_avl "Ölstand aus dynamischer Messung vorhanden";
CM_ SG_ 967 MO_Text_Partikelfil_Reg "Über dieses Bit im Kombi wird ein Klartextanzeige erzeugt werden: 'Partikelfilter benötigt Regeneration'.
";
CM_ SG_ 967 OLEV_Oelstand_nicht_vorhanden "Kein aktueller Ölstand vorhanden";
CM_ SG_ 967 WIV_Oelmenge "Ölmenge zwischen Min und Max";
CM_ SG_ 967 MO_Systemlampe "EGas Systemlampe (EPC) oder Vorglühlampe im Kombi, Kombi steuert immer gleiche
LED an, nur über Ziffernblatt wird die EPC von der Vorglühlampe differenziert";
CM_ SG_ 967 MO_OBD2_Lampe "OBD bzw. MIL-Lampe wird vom Motorsteuergerät angesteuert, die Information im Signal GE_OBD_Status wird vom Motorsteuergerät an das Kombi weitergereicht";
CM_ SG_ 967 MO_Heissleuchte "Ansteuerung der Kühlwassertemperatur-Heißleuchte (Sensor nur noch am Motorsteuergerät): Temperaturschaltschwellen mit Hysterese (bei VW D1/Colorado Kombi derzeit noch nicht genutzt).";
CM_ SG_ 967 MO_Partikel_Lampe "Partikelfilter-Lampe wird eingeschaltet";
CM_ SG_ 967 MO_RedFahrleistung_Lampe "Ansteuerung der Turtle-Mode Lampe für E-Traktion Fahrzeuge";
CM_ SG_ 967 WIV_Oelstand_nicht_vorhanden "Kein aktueller Ölstand vorhanden";
CM_ SG_ 967 WIV_nachfuellanzeige_ein "Steuert das Aufblenden der Nachfüllanzeige im Kombi, nach Klemme 15 ein und geöffneter Motorhaube";
CM_ SG_ 967 WIV_Ueberfuell_deaktiv "Unterdrückung der Warnung im Kombi die durch Signal WIV_Ueberfuel_Warn ausgelöst wird";
CM_ SG_ 967 WIV_Unterfuell_Warn "Ölstand hat die Unterfüllschwelle unterschritten";
CM_ SG_ 967 MO_Tankdeckel_Lampe "Ansteuerung Tankdeckel-Warnlampe Kombiinstrument (nur Ottomotoren) z.Zt. Vorhalt VW";
CM_ SG_ 967 MO_Text_Tankdeckelwarn "Textbit der Tankdeckelwarnung, z.Zt. Vorhalt VW";
CM_ SG_ 967 MO_Vorglueh_Lampe "Vorglühlampe im Kombi, Kombi steuert immer gleiche LED an. 
Mit Einführung des Einheits-Kombis sind getrennte Signalwege für Vorglühlampe und EPCL notwendig.";
CM_ SG_ 967 WIV_Oeldr_Warn_Motor "Löst im Kombiinstrument die rote Prio1-Öldruckwarnung (inkl. 3xBeep) aus.
nur MLB: die Warnauslösung erfolgt nur bei gleichzeitig gesetztem 'WIV_Enable_Oeldr_Motor'";
CM_ SG_ 967 MO_E_Mode "Anforderung der E-Mode Statusanzeige";
CM_ SG_ 966 SOK_Motor_26_Signatur "Signatur im Rahmen der durch SOK geschützten Broadcast-Kommunikation

Geschützte Funktion: ORU
Geschützte Botschaft: Motor_26";
CM_ SG_ 706 MO_Powermeter_Dauer_Grenze "Vortrieb Dauer?Leistung
? dauerhaft verfügbare Vortriebsleistung
? abhängig von SOC und Temperatur";
CM_ SG_ 706 MO_Anzeige_StSt_Text "Steuert die Anzeige der StSt-Texte im Kombi";
CM_ SG_ 706 MO_Anzeige_StSt_Symbol "Steuert die Anzeige der StSt-Symbolik im Kombi";
CM_ SG_ 706 MO_ADR_Status "Status der Arbeitsdrehzahlregelung";
CM_ SG_ 706 MO_AGA_Sound_Texte "Textausgabe des aktuellen Sound-Zustandes der Abgasklappensteuerung";
CM_ SG_ 706 MO_Anzeige_FMAus_Text "Fehlerstatus des FMAus-Systems (z.B. Fehler im Zusatzspeicher)";
CM_ SG_ 706 PEA_Texte "Status der Funktion PEA";
CM_ SG_ 706 TSK_Ueberstimmt_vMax_FahrerInfo "Information ueber den Zustand wann die vMax-Limitierung vom Fahrer ueberstimmt wird.";
CM_ SG_ 706 MO_Rekuperationsstufe "In Projekten mit variablen oder anwählbaren Rekuperationsstufen soll dem Fahrer die aktuell ausgewählte Stufe über ein Icon in den Anzeigeinstrumenten visualisiert werden können. Dies dient der Nachvollziehbarkeit für den Kunden in Bezug auf eine zukünfti";
CM_ SG_ 706 TSK_Einheit_vMax_FahrerInfo "Einheit zu TSK_vMax_FahrerInfo. Das MSG spiegelt hier KBI_MFA_v_Einheit und stellt den Anzeigewert in dieser Einheit zur Verfügung (kein zyklisches Mux)";
CM_ SG_ 706 TSK_Status_vMax_FahrerInfo "Status der TSK_vMax_FahrerInfo zur Steuerung von PopUps, Fahrzeugstatus und ggf. einer LED. Bei Wert 0 in TSK_vMax_Fahrerinfo soll auf eine unspezifische Begrenzung hingewiesen werden (z.B. wegen Momentenbegrenzung), bei allen anderen Werten soll dieser a";
CM_ SG_ 706 MO_Anz_Kuehlerluefter "Signal bei aktivem Kühlerlüfternachlauf (Motor aus) im Allgemeinen für die Anzeige im Kombi-Instument zur Information des Kunden über diesen Lüfterlauf";
CM_ SG_ 706 FDR_Warnung_ALR "Warnmeldungen der Allradverteilung";
CM_ SG_ 706 MO_EM_Ueberhitzungswarnung "Der elektrische Antrieb ist aufgrund eines Fehlers oder dauerhaft sehr hoher Drehzahl überhitzt.";
CM_ SG_ 706 MO_ElAntrieb_Abschleppwarnung "Warnung, wenn ein Mitschleppen der jeweils bezeichneten Achse zu einer Beschädigung des elektrischen Antriebs führen kann.";
CM_ SG_ 706 TSK_vMax_FahrerInfo "anzuzeigende Begrenzungsgeschwindigkeit bei aktiver HGB";
CM_ SG_ 267 Motor_51_CRC "Für MLB:
Berechnung siehe Lastenheft 'Kommunikationsabsicherung für FlexRay und CAN'
Ab MQB und MLBevo:
Berechnung siehe Lastenheft 'End-to-End Kommunikationsabsicherung'

Endwerte siehe Begleitdokument 'S-PDU Kennungsfolgen'";
CM_ SG_ 267 Motor_51_BZ "4bit Botschaftszähler, wird mit jeder Sendebotschaft inkrementiert";
CM_ SG_ 267 MO_Fahrpedalrohwert_01 "AUDI D4: Zykluszeit: 10ms (siehe Zykluszeit schnell/Cycletime Fast)

Stellung des Fahrpedales (Rohwert, ohne Überlagerung durch GRA-Eingriffe etc.)

Die Funktionen zur Berechung des Fahrpedalrohwerts laufen im 10ms Raster. Der Fahrpedalwert berechnet ";
CM_ SG_ 267 MO_QBit_Fahrpedalwerte_01 "AUDI D4: Zykluszeit: 10ms (siehe Zykluszeit schnell/Cycletime Fast)

QBit für beide Fahrpedalwerte des Motors (Fahrpedalrohsignal für ESP, EPB, ACC; Fahrpedalwert für Getriebe)

Achtung:
Reduktion der Zykluszeit Motor_03 auf 10ms geplant.
Projektabh";
CM_ SG_ 267 MO_Fahrpedalgradient "Das Motorsteuergerät besitzt 2 analoge Fahrpedalsignale. Das Signal des ersten Kanals wird alle 4ms abgetastet. Um Bitschwankungen des A/D-Wandler herauszufiltern wird das Signal entjittert. Anschließend wird der Gradient berechnet. Entsprechend der Zyklu";
CM_ SG_ 267 MO_Sig_Fahrpedalgradient "Kennzeichnet das Vorzeichen des Signal 'Fahrpedalgradient'. Die Ausgabe erfolgt nur parallel statisch mit gesendetem Signal: 'Steuerungsbit Fahrpedalgradient' ";
CM_ SG_ 267 MO_rel_Saugrohrdruck "Der Wert gibt an, um wieviel mbar der Saugrohrdruck unterhalb des Umgebungsdrucks liegt. Überdruck im Saugrohr wird nicht ausgegeben.
0: Saugrohrdruck=Umgebungsdruck";
CM_ SG_ 267 MO_rel_Saugrohrdruck_gem_err "0: mind. eine Modellrechnung wird zur Berechnung des relativen Saugdrucks herangezogen
1: Relativer Saugrohrdruck wird ausschließlich über Messgrößen bestimmt";
CM_ SG_ 267 MO_Moment_im_Leerlauf "Fahrerwunschmoment ist minimal: keine Momentenanforderung durch Fahrpedal, ACC oder GRA+; (Das Signal ist unabhängig von Momentenerhöhungen durch Leerlaufregler oder MSR).

AUDI D4: Zykluszeit: 10ms (siehe Zykluszeit schnell/Cycletime Fast)

Achtung:";
CM_ SG_ 267 MO_Schubabschaltung "ESP plausibilisiert Unterdrucksensor nur bei aktiver Schubabschaltung

MLBevo:
Signal wird nur in MLBevo Projekten mit PDKII Getriebe bedient. In allen anderen MLBevo Projekten wird das Signal mit '0' bedient
PDKII berücksichtigt Verzugszeiten, die in";
CM_ SG_ 267 MO_StartStopp_StoppVorbereitung "Zeigt allen aktiven Start-/Stoppteilnehmern einen möglichen Motorstopp im Anhaltevorgang an (Empfänger notwendige Vorbereitungen treffen)
Es liegen keine Vetos vor.";
CM_ SG_ 267 MO_Solldrehz_Leerlauf "Leerlaufsolldrehzahl, die im Motor eingestellt ist (Bei Parallelhybrid im E-Fahr-Betrieb Leerlaufsolldrehzahl der E-Maschine). Der Motor paßt aufgrund der Anforderung von anderen Steuergeräten seine Leerlaufsolldrehzahl an, bspw. Kat-Heizen, Anforderung v";
CM_ SG_ 267 MO_Entkopplung_Sollschlupf "MSG fordert von GSG an, das Anfahrelement (Fahr-/Wandlerkupplung) zu entkoppeln; das GSG soll die gesendete Drehzahl als Schlupf einstellen und ggf. die Regler-Parameter umschalten, damit Rucke aus dem Antrieb nicht im Fahrzeug spürbar werden; nutzbar z.B";
CM_ SG_ 267 MO_temporaere_Fahrerabwesenheit "Das Signal dient zur Signalisierung einer temporären Abwesenheit des Fahrers. In dieser Zeit ist es ihm möglich, sich durch gewisse ¿ im Verlassenskonzept definierte ¿ Fahreraktionen im aktuellen Fahrzyklus zurückzumelden.
Das Signal wird gesetzt, sobald";
CM_ SG_ 267 TSK_a_Soll_gradientenbegrenzt "TSK Sollbeschleunigung für Fahrerassistenzsysteme mit aktiver Längsführung (GRA, ACC, IPA...). Der Wert stellt den ruckbegrenzten Sollwert der TSK-Regelung dar und ist Basis der TSK-Antriebs- und Bremsmomentenvorsteuerung.";
CM_ SG_ 267 TSK_Radbremsmom "Bei der Schnittstelle vom TSK zum ESP soll in Folgeprojekten des B8 und insbesondere bei VW-Projekten die Ansteuerung der Bremse nicht über Sollbeschleunigung sondern Bremsmoment erfolgen.  Es handelt sich genauer um das Summenradbremsmoment, welches die ";
CM_ SG_ 267 TSK_Status "Betriebszustand des TSK-Reglers";
CM_ SG_ 267 TSK_v_Begrenzung_aktiv "Limiter oder HGB begrenzen die Beschleunigung/das Moment";
CM_ SG_ 267 TSK_Standby_Anf_ESP "Mit diesem Bit wird das aktive Bremssystem auf eine anstehende TSK-Verzögerungsanforderung vorbereitet (Überfahren Leerweg, Anlegen Bremsbeläge)";
CM_ SG_ 267 TSK_Freig_Verzoeg_Anf "Freigabe der Verzögerungsanforderung der ACC oder ggf. GRA+ Funktion für ECD Regelung im ESP";
CM_ SG_ 267 TSK_Limiter_ausgewaehlt "ACC/GRA-Betrieb nur bei nicht ausgewähltem Limiter möglich";
CM_ SG_ 267 TSK_Hauptschalter_GRA_ACC "Stellung des GRA/ACC Hauptschalters. Das Signal wird auch bei Fehlerabschaltungen von GRA/ACC weiterhin bedient und ermöglicht für ACC die Steuerung der ACC-Anzeige auch in Fehlerfällen.";
CM_ SG_ 267 TSK_SRBM_Anf_ASIL "ASIL-Level des TSK-Anforderers, der aktuell eine Bremsmomentenanforderung auslöst";
CM_ SG_ 267 TSK_ax_Getriebe_02 "Beschleunigungsanforderung des Beschleunigungsreglers (u. a. für ACC, GRA, Speed Limiter). Das Signal wird vom Getriebe benutzt, um die von GRA/ACC geforderte Sollbeschleunigung in dem verbrauchsgünstigsten Gang einzustellen.
MQB: Im MQB wird die Sollbes";
CM_ SG_ 267 TSK_Zwangszusch_ESP "Mit diesem Bit wird das ESP/ASR zwangsweise aktiviert. Bei gesetztem Bit ist ein ausgetastetes ESP (oder ASR) wieder aktiviert bzw. wird die Austastung verhindert.";
CM_ SG_ 267 TSK_zul_Regelabw "Anforderung der zulässigen Regelabweichung vom Triebstrangkoordinator. Zulässiger Betrag der Abweichung zwischen angeforderter 'TSK_Sollbeschleunigung_Getriebe' und umzusetzender Sollbeschleunigung  im Getriebe. Im TSK wird, abhängig vom Arbeitspunkt die ";
CM_ SG_ 267 TSK_Radsollmoment "Sollradmoment vom TSK";
CM_ SG_ 267 TSK_Kategorie_Verzoegerungsfkt "Zeigt der Bremslichtfunktion an, ob die aktuell verzögerungswirksame Teilnehmerfunktion am TSK als Fahrerassistenzsystem oder als Schubrekuperation zu interpretieren ist.";
CM_ SG_ 267 TSK_Notstopp_Anf "Anforderung Notstopp des TSK";
CM_ SG_ 267 MO_Status_MinDrzEingriff "Aktuell drehzahlführender Anforderer der Minimaldrehzahl (Begrenzungsregelung) des Pulswechselrichters der Primärachse.";
CM_ SG_ 267 MO_Status_MaxDrzEingriff "Aktuell drehzahlführender Anforderer der Maximaldrehzahl (Begrenzungsregelung) des Pulswechselrichters der Primärachse.";
CM_ SG_ 267 MO_Status_MinDrzEingriff_sek "Aktuell drehzahlführender Anforderer der Minimaldrehzahl (Begrenzungsregelung) des Pulswechselrichters der Sekundärachse.";
CM_ SG_ 267 MO_Status_MaxDrzEingriff_sek "Aktuell drehzahlführender Anforderer der Maximaldrehzahl (Begrenzungsregelung) des Pulswechselrichters der Sekundärachse.";
CM_ SG_ 267 TSK_SRBM_max_Gradient "In diesem Signal wird der vom TSK maximal geforderte SummenRadBremsMomentengradient gesendet, der von der Bremse bei der Umsetzung der TSK-Verzögerung nicht überschritten werden darf.";
CM_ SG_ 267 SOK_Motor_51_Signatur "Signatur im Rahmen der durch SOK geschützten Broadcast-Kommunikation

Geschützte Funktion: Bremsfunktion HDC und Airbag-Funktionen 
Geschützte Botschaft: Motor_51";
CM_ SG_ 330 Motor_52_CRC "Für MLB:
Berechnung siehe Lastenheft 'Kommunikationsabsicherung für FlexRay und CAN'
Ab MQB und MLBevo:
Berechnung siehe Lastenheft 'End-to-End Kommunikationsabsicherung'

Endwerte siehe Begleitdokument 'S-PDU Kennungsfolgen'";
CM_ SG_ 330 Motor_52_BZ "4bit Botschaftszähler, wird mit jeder Sendebotschaft inkrementiert";
CM_ SG_ 330 MO_Hochschaltdrehz "Hochschaltdrehzahl bei manuellem Gangwechsel über Lenkrad Tip-Up oder Gangwahlhebel falls dieser in Tippgasse.
Nur AUDI RS-Modelle!";
CM_ SG_ 330 MO_Anzeige_Verbr_Einheit "Signal steht im Kontext MO_Anzeige_Verbrauch und überträgt die Verbrauchseinheit der aktuellen Antriebsart. Signal muss in der gleichen Botschaft wie MO_Anzeige_Verbrauch übertragen werden";
CM_ SG_ 330 MO_Schaltblitz_Anz "Signalisierung der drehzahlabhängigen Schaltblitzanzeige im Kombiinstrument (0-100%)";
CM_ SG_ 330 MO_Anzeige_Drehmoment "Drehmomentssignal für Sport-HMI im Kombi.";
CM_ SG_ 330 MO_Anzeige_Leistung "Leistungssignal für Sport-HMI im Kombi.";
CM_ SG_ 330 MO_rel_Ladedruck "relativer Ladedruck (für Boostanzeige)";
CM_ SG_ 330 MO_Istgang "Aktueller Gang für Anzeige Hochschaltempfehlung (gültig, wenn MO_Schaltempf_verfbar = 1).

Anzeige im Kombi:
Sollgang == Istgang         ==> Anzeige Istgang
Sollgang !=   Istgang         ==> Schaltempfehlung
Sollgang == Istgang == 0 ==> keine Anzeige";
CM_ SG_ 330 MO_Sollgang "Motor sendet den Sollgang in den der Fahrer schalten soll. Wird im Kombi als Hochschaltempfehlung hervorgehoben (gültig, wenn MO_Schaltempf_verfbar = 1).

Anzeige im Kombi:
Sollgang == Istgang          ==> Anzeige Istgang
Sollgang !=  Istgang         ";
CM_ SG_ 330 MO_Oeldruck "Öldruck analog zur Anzeige";
CM_ SG_ 330 MO_Anzeigedrehz "Optimierte Anzeigedrehzahl wegen sportlicherem Drehzahlmesser im Kombi. 
Bei Parallelhybrid: Anzeige VKM- Drehzahl nach Anzeigekonzept

Hinweis: Ehemaliger Fehlerwert 0xFFF wird senderseitig nicht unterstützt. Diesen Wert aus Kompatibilitätsgründen nic";
CM_ SG_ 330 MO_Effizienzmodus "Bei Handschaltern wird  das Fahrprogramm Effizienz signalisiert. 
Bei Automatikgetrieben wird das Fahrprogramm 'D' durch 'E' ersetzt.";
CM_ SG_ 330 MO_Fehler_Oeldrucksensor "Steuert  im Kombiinstrument die gelbe zentrale Warnlampe und das Symbol 'gelbe Ölkanne'  mit der Textmeldung 'Sensorfehler: Werkstatt aufsuchen' an
";
CM_ SG_ 330 MO_Schaltempf_verfbar "Info, ob Schaltempfehlung im Fzg. verfügbar. Statischer Wert, ändert sich für ein Fzg. nicht!";
CM_ SG_ 330 MO_Ladedruck "absoluter Ladedruck";
CM_ SG_ 330 MO_KVS "Motorsteuergerätinterner Verbrauchszähler, der vom Kombi zyklisch ausgelesen wird, um die Einspritzmenge zur Verbrauchsmessung aufzusummieren; aus diesem Zählerstand werden Momentan- und Durchschnittsverbrauch berechnet; das Überlauf-Bit ist zu berücksich";
CM_ SG_ 330 MO_KVS_Ueberlauf "Der motorsteuergeräteinterne Verbrauchszähler ist mindestens einmal übergelaufen. Dieses Bit wird genutzt, um erkennen zu können, daß das Motorsteuergerät aus dem Reset-Zustand hochläuft.";
CM_ SG_ 330 MO_ePowermeter "Anzeige ePowermeter (Fahrreserve elektrisch bis Start Verbrennungsmotor (Verbrenner startet bei 100%))";
CM_ SG_ 330 MO_ePerformance "Zeigt die elektrische Leistungreserve bei BEV und PHEV Projekten an.
Bei Init und Fehler soll keine Anzeige erfolgen. ";
CM_ SG_ 330 MO_Zust_Antrieb "Signalisiert die Zuordnung der Antriebsverbräuche zu den Antriebsmaschinen für die Restreichweitenberechnung, nicht gleichbedeutend mit Motorlauf EM oder VM bzw. Brennstoffzelle";
CM_ SG_ 330 MO_Zust_Betriebsstrategie "Signalisiert den aktuellen Zustand der Betriebsstrategie";
CM_ SG_ 330 Ladezustand_02 "Aktueller relativer Ladezustand der HV-Batterie
";
CM_ SG_ 330 Ladezustand_gering "Fahrerwarnung bezüglich geringem Ladezustand der HV-Batterie";
CM_ SG_ 330 MO_Powermeter_Elm_02 "relatives Moment / relative Leistung der elektrischen Maschine";
CM_ SG_ 330 MO_Powermeter "Anzeigewerte im Kombi
0       = Unteres Ende Bremsen/grau;
340   = Unteres Ende CHARGE;
1020 = READY;
1870 = Oberes Ende EFFICIENCY;
3400 = 100%;
4080 = MAX;";
BA_DEF_ BO_  "DiagRequest" ENUM  "No","Yes";
BA_DEF_ BO_  "DiagResponse" ENUM  "No","Yes";
BA_DEF_ BO_  "DiagState" ENUM  "No","Yes";
BA_DEF_ BO_  "GenMsgChkConstant" HEX 0 4095;
BA_DEF_ BO_  "GenMsgCycleTime" INT 0 65535;
BA_DEF_ BO_  "GenMsgCycleTimeFast" INT 0 65535;
BA_DEF_ BO_  "GenMsgDelayTime" INT 0 100000;
BA_DEF_ BO_  "GenMsgILSupport" ENUM  "No","Yes";
BA_DEF_ BO_  "GenMsgNrOfRepetition" INT 0 100;
BA_DEF_ BO_  "GenMsgPDUConstants" STRING ;
BA_DEF_ BO_  "GenMsgSendType" ENUM  "Cyclic","not_used","not_used","not_used","not_used","not_used","not_used","IfActive","NoMsgSendType";
BA_DEF_ BO_  "GenMsgStartDelayTime" INT 0 100000;
BA_DEF_ BO_  "NmMessage" ENUM  "No","Yes";
BA_DEF_ BO_  "NmhMessage" ENUM  "No","Yes";
BA_DEF_ BO_  "MsgType" ENUM  "Application","NM ","NMH","TP2.0","ISO-TP ","BAP","EID","KS","XCP_PRE_CONFIGURED","XCP_RUNTIME_CONFIGURED";
BA_DEF_ BO_  "VAGTP20_API" HEX 0 255;
BA_DEF_ BO_  "VAGTP20_DynConnection" ENUM  "No","Yes";
BA_DEF_ BO_  "VAGTP20_DynSetup" ENUM  "No","Yes";
BA_DEF_ BO_  "VAGTP20_StatConnection" ENUM  "No","Yes";
BA_DEF_ BO_  "CANFD_BRS" ENUM  "0","1";
BA_DEF_ BO_  "VFrameFormat" ENUM  "StandardCAN","ExtendedCAN","reserved","reserved","reserved","reserved","reserved","reserved","reserved","reserved","reserved","reserved","reserved","reserved","StandardCAN_FD","ExtendedCAN_FD";
BA_DEF_ SG_  "GenSigActiveRepetitions" INT -2147483648 2147483647;
BA_DEF_ SG_  "GenSigInactiveValue" INT -2147483648 2147483647;
BA_DEF_ SG_  "GenSigSendType" ENUM  "Cyclic","OnWrite","OnWriteWithRepetition","OnChange","OnChangeWithRepetition","IfActive","IfActiveWithRepetition","NoSigSendType","OnChangeAndIfActive","OnChangeAndIfActiveWithRepetition";
BA_DEF_ SG_  "GenSigStartValue" INT -2147483648 2147483647;
BA_DEF_ SG_  "NWM-WakeupAllowed" ENUM  "No","Yes";
BA_DEF_ SG_  "GenSigFuncType" ENUM  "NoFunction","MsgCounter","CRC-8","XOR","XOR-2","DatedBit","SW-Kl15","CHK","Constant","Protocol","CRC-8-SAE_J1850","CRC-32","DataLength","DataID","MsgCounter16","SOK-Signatur","Cluster";
BA_DEF_ SG_  "GenSigSwitchedByIgnition" ENUM  "No","Yes";
BA_DEF_ SG_  "Fehlerwert" HEX 0 2147483647;
BA_DEF_ SG_  "GenSigMissingSourceValue" HEX 0 2147483647;
BA_DEF_REL_ BU_SG_REL_  "GenSigTimeoutTime" INT 0 65535;
BA_DEF_DEF_  "DiagRequest" "No";
BA_DEF_DEF_  "DiagResponse" "No";
BA_DEF_DEF_  "DiagState" "No";
BA_DEF_DEF_  "GenMsgChkConstant" 0;
BA_DEF_DEF_  "GenMsgCycleTime" 0;
BA_DEF_DEF_  "GenMsgCycleTimeFast" 0;
BA_DEF_DEF_  "GenMsgDelayTime" 0;
BA_DEF_DEF_  "GenMsgILSupport" "No";
BA_DEF_DEF_  "GenMsgNrOfRepetition" 0;
BA_DEF_DEF_  "GenMsgPDUConstants" "";
BA_DEF_DEF_  "GenMsgSendType" "NoMsgSendType";
BA_DEF_DEF_  "GenMsgStartDelayTime" 0;
BA_DEF_DEF_  "NmMessage" "No";
BA_DEF_DEF_  "NmhMessage" "No";
BA_DEF_DEF_  "MsgType" "Application";
BA_DEF_DEF_  "VAGTP20_API" 0;
BA_DEF_DEF_  "VAGTP20_DynConnection" "No";
BA_DEF_DEF_  "VAGTP20_DynSetup" "No";
BA_DEF_DEF_  "VAGTP20_StatConnection" "No";
BA_DEF_DEF_  "CANFD_BRS" "1";
BA_DEF_DEF_  "VFrameFormat" "StandardCAN";
BA_DEF_DEF_  "GenSigActiveRepetitions" 0;
BA_DEF_DEF_  "GenSigInactiveValue" 0;
BA_DEF_DEF_  "GenSigSendType" "NoSigSendType";
BA_DEF_DEF_  "GenSigStartValue" 0;
BA_DEF_DEF_  "NWM-WakeupAllowed" "No";
BA_DEF_DEF_  "GenSigFuncType" "NoFunction";
BA_DEF_DEF_  "GenSigSwitchedByIgnition" "Yes";
BA_DEF_DEF_  "Fehlerwert" 0;
BA_DEF_DEF_  "GenSigMissingSourceValue" 0;
BA_DEF_DEF_REL_ "GenSigTimeoutTime" 0;
BA_ "GenMsgSendType" BO_ 1153 0;
BA_ "GenMsgNrOfRepetition" BO_ 1153 5;
BA_ "GenMsgILSupport" BO_ 1153 1;
BA_ "GenMsgDelayTime" BO_ 1153 50;
BA_ "GenMsgCycleTimeFast" BO_ 1153 50;
BA_ "GenMsgCycleTime" BO_ 1153 500;
BA_ "VFrameFormat" BO_ 1153 14;
BA_ "GenMsgSendType" BO_ 1639 0;
BA_ "GenMsgILSupport" BO_ 1639 1;
BA_ "GenMsgDelayTime" BO_ 1639 50;
BA_ "GenMsgCycleTime" BO_ 1639 100;
BA_ "VFrameFormat" BO_ 1639 14;
BA_ "GenMsgSendType" BO_ 1178 0;
BA_ "GenMsgILSupport" BO_ 1178 1;
BA_ "GenMsgDelayTime" BO_ 1178 50;
BA_ "GenMsgCycleTime" BO_ 1178 100;
BA_ "VFrameFormat" BO_ 1178 14;
BA_ "GenMsgSendType" BO_ 1171 0;
BA_ "GenMsgPDUConstants" BO_ 1171 "0x97,0x97,0x97,0x97,0x97,0x97,0x97,0x97,0x97,0x97,0x97,0x97,0x97,0x97,0x97,0x97";
BA_ "GenMsgILSupport" BO_ 1171 1;
BA_ "GenMsgDelayTime" BO_ 1171 20;
BA_ "GenMsgCycleTime" BO_ 1171 200;
BA_ "GenMsgChkConstant" BO_ 1171 151;
BA_ "VFrameFormat" BO_ 1171 14;
BA_ "GenMsgSendType" BO_ 1164 0;
BA_ "GenMsgNrOfRepetition" BO_ 1164 5;
BA_ "GenMsgILSupport" BO_ 1164 1;
BA_ "GenMsgDelayTime" BO_ 1164 20;
BA_ "GenMsgCycleTimeFast" BO_ 1164 50;
BA_ "GenMsgCycleTime" BO_ 1164 200;
BA_ "VFrameFormat" BO_ 1164 14;
BA_ "GenMsgSendType" BO_ 817 0;
BA_ "GenMsgILSupport" BO_ 817 1;
BA_ "GenMsgCycleTimeFast" BO_ 817 30;
BA_ "GenMsgCycleTime" BO_ 817 500;
BA_ "VFrameFormat" BO_ 817 14;
BA_ "GenMsgSendType" BO_ 560 0;
BA_ "GenMsgILSupport" BO_ 560 1;
BA_ "GenMsgDelayTime" BO_ 560 10;
BA_ "GenMsgCycleTime" BO_ 560 100;
BA_ "VFrameFormat" BO_ 560 14;
BA_ "GenMsgSendType" BO_ 2463978751 0;
BA_ "GenMsgNrOfRepetition" BO_ 2463978751 5;
BA_ "GenMsgILSupport" BO_ 2463978751 1;
BA_ "GenMsgDelayTime" BO_ 2463978751 50;
BA_ "GenMsgCycleTimeFast" BO_ 2463978751 100;
BA_ "GenMsgCycleTime" BO_ 2463978751 1000;
BA_ "VFrameFormat" BO_ 2463978751 15;
BA_ "GenMsgILSupport" BO_ 1471 1;
BA_ "GenMsgDelayTime" BO_ 1471 10;
BA_ "VFrameFormat" BO_ 1471 14;
BA_ "GenMsgSendType" BO_ 958 0;
BA_ "GenMsgPDUConstants" BO_ 958 "0x1f,0x28,0xc6,0x85,0xe6,0xf8,0xb0,0x19,0x5b,0x64,0x35,0x21,0xe4,0xf7,0x9c,0x24";
BA_ "GenMsgILSupport" BO_ 958 1;
BA_ "GenMsgDelayTime" BO_ 958 10;
BA_ "GenMsgCycleTime" BO_ 958 100;
BA_ "VFrameFormat" BO_ 958 14;
BA_ "GenMsgSendType" BO_ 1648 0;
BA_ "GenMsgILSupport" BO_ 1648 1;
BA_ "GenMsgDelayTime" BO_ 1648 20;
BA_ "GenMsgCycleTime" BO_ 1648 500;
BA_ "VFrameFormat" BO_ 1648 14;
BA_ "GenMsgSendType" BO_ 967 0;
BA_ "GenMsgILSupport" BO_ 967 1;
BA_ "GenMsgCycleTime" BO_ 967 100;
BA_ "VFrameFormat" BO_ 967 14;
BA_ "GenMsgSendType" BO_ 966 0;
BA_ "GenMsgILSupport" BO_ 966 1;
BA_ "GenMsgCycleTime" BO_ 966 100;
BA_ "VFrameFormat" BO_ 966 14;
BA_ "GenMsgSendType" BO_ 706 0;
BA_ "GenMsgILSupport" BO_ 706 1;
BA_ "GenMsgDelayTime" BO_ 706 100;
BA_ "GenMsgCycleTime" BO_ 706 500;
BA_ "VFrameFormat" BO_ 706 14;
BA_ "GenMsgSendType" BO_ 267 0;
BA_ "GenMsgPDUConstants" BO_ 267 "0x2c,0xb1,0x1a,0x75,0xbb,0x65,0x79,0x47,0x81,0x2b,0xcc,0x96,0x17,0xdb,0xc0,0x94";
BA_ "GenMsgILSupport" BO_ 267 1;
BA_ "GenMsgCycleTime" BO_ 267 20;
BA_ "VFrameFormat" BO_ 267 14;
BA_ "GenMsgSendType" BO_ 330 0;
BA_ "GenMsgILSupport" BO_ 330 1;
BA_ "GenMsgCycleTime" BO_ 330 20;
BA_ "VFrameFormat" BO_ 330 14;
BA_ "GenSigSwitchedByIgnition" SG_ 1153 ZR_LoGeWa_Event_Kombiwarnung 0;
BA_ "GenSigSendType" SG_ 1153 ZR_LoGeWa_Event_Kombiwarnung 3;
BA_ "GenSigSwitchedByIgnition" SG_ 1153 Nav_FoD_Status 0;
BA_ "GenSigSendType" SG_ 1153 Nav_FoD_Status 0;
BA_ "GenSigSwitchedByIgnition" SG_ 1153 MIB_ASW_Diagnose 0;
BA_ "GenSigStartValue" SG_ 1153 MIB_ASW_Diagnose 1;
BA_ "GenSigSendType" SG_ 1153 MIB_ASW_Diagnose 0;
BA_ "GenSigSwitchedByIgnition" SG_ 1153 ZR_Lichter_Tag 0;
BA_ "GenSigStartValue" SG_ 1153 ZR_Lichter_Tag 1;
BA_ "GenSigSendType" SG_ 1153 ZR_Lichter_Tag 3;
BA_ "GenSigSwitchedByIgnition" SG_ 1153 MIB_Tongenerator_PH_verfuegbar 0;
BA_ "GenSigSendType" SG_ 1153 MIB_Tongenerator_PH_verfuegbar 3;
BA_ "GenSigSwitchedByIgnition" SG_ 1153 MMI_Counter_Bedienevent 0;
BA_ "GenSigSendType" SG_ 1153 MMI_Counter_Bedienevent 0;
BA_ "GenSigSwitchedByIgnition" SG_ 1153 DSSS_Warning 0;
BA_ "GenSigSendType" SG_ 1153 DSSS_Warning 3;
BA_ "GenSigSwitchedByIgnition" SG_ 1153 ZR_Kindersicherung_RSE 0;
BA_ "GenSigSendType" SG_ 1153 ZR_Kindersicherung_RSE 3;
BA_ "GenSigSwitchedByIgnition" SG_ 1153 ZR_RSE_aktivieren 0;
BA_ "GenSigSendType" SG_ 1153 ZR_RSE_aktivieren 3;
BA_ "GenSigSwitchedByIgnition" SG_ 1153 MMI_SDS_aktiv 0;
BA_ "GenSigSendType" SG_ 1153 MMI_SDS_aktiv 3;
BA_ "GenSigSwitchedByIgnition" SG_ 1153 MU_SecondDisplay 0;
BA_ "GenSigSendType" SG_ 1153 MU_SecondDisplay 3;
BA_ "GenSigSwitchedByIgnition" SG_ 1153 MMI_Telefon_aktiv 0;
BA_ "GenSigSendType" SG_ 1153 MMI_Telefon_aktiv 3;
BA_ "GenSigSwitchedByIgnition" SG_ 1153 MMI_Gurt_Mic_ref 0;
BA_ "GenSigSendType" SG_ 1153 MMI_Gurt_Mic_ref 3;
BA_ "GenSigSwitchedByIgnition" SG_ 1153 ZR_AppConnect_Zustand 0;
BA_ "GenSigSendType" SG_ 1153 ZR_AppConnect_Zustand 4;
BA_ "GenSigSwitchedByIgnition" SG_ 1153 MU_Update_Time 0;
BA_ "GenSigSendType" SG_ 1153 MU_Update_Time 0;
BA_ "GenSigSwitchedByIgnition" SG_ 1153 HMI_WLC1_Systemzustand_intern 0;
BA_ "GenSigStartValue" SG_ 1153 HMI_WLC1_Systemzustand_intern 2;
BA_ "GenSigSendType" SG_ 1153 HMI_WLC1_Systemzustand_intern 3;
BA_ "GenSigSwitchedByIgnition" SG_ 1153 HMI_WLC2_Systemzustand_intern 0;
BA_ "GenSigStartValue" SG_ 1153 HMI_WLC2_Systemzustand_intern 2;
BA_ "GenSigSendType" SG_ 1153 HMI_WLC2_Systemzustand_intern 3;
BA_ "GenSigSwitchedByIgnition" SG_ 1153 ZR_Parken_Sondermodus 0;
BA_ "GenSigSendType" SG_ 1153 ZR_Parken_Sondermodus 3;
BA_ "Fehlerwert" SG_ 1153 INF_Nachlaufzeit 511;
BA_ "GenSigSwitchedByIgnition" SG_ 1153 INF_Nachlaufzeit 0;
BA_ "GenSigStartValue" SG_ 1153 INF_Nachlaufzeit 510;
BA_ "GenSigSendType" SG_ 1153 INF_Nachlaufzeit 0;
BA_ "GenSigSwitchedByIgnition" SG_ 1639 BFS_Fond_Bed_Ack 0;
BA_ "GenSigSendType" SG_ 1639 BFS_Fond_Bed_Ack 3;
BA_ "GenSigSwitchedByIgnition" SG_ 1639 BFS_Lehne_nicht_verriegelt 0;
BA_ "GenSigSendType" SG_ 1639 BFS_Lehne_nicht_verriegelt 3;
BA_ "GenSigSwitchedByIgnition" SG_ 1639 BFS_Klapptisch_offen 0;
BA_ "GenSigSendType" SG_ 1639 BFS_Klapptisch_offen 3;
BA_ "GenSigSwitchedByIgnition" SG_ 1639 BFS_Gurtbringer_Sperre 0;
BA_ "GenSigSendType" SG_ 1639 BFS_Gurtbringer_Sperre 0;
BA_ "GenSigSwitchedByIgnition" SG_ 1639 BFS_Sitzsym_Fahrt_aktiv 0;
BA_ "GenSigSendType" SG_ 1639 BFS_Sitzsym_Fahrt_aktiv 3;
BA_ "GenSigSwitchedByIgnition" SG_ 1639 BFS_Sitzfahrt_aktiv 0;
BA_ "GenSigSendType" SG_ 1639 BFS_Sitzfahrt_aktiv 3;
BA_ "GenSigSwitchedByIgnition" SG_ 1639 BFS_SLV_aktiv 0;
BA_ "GenSigSendType" SG_ 1639 BFS_SLV_aktiv 3;
BA_ "GenSigSwitchedByIgnition" SG_ 1639 BFS_SHV_aktiv 0;
BA_ "GenSigSendType" SG_ 1639 BFS_SHV_aktiv 3;
BA_ "GenSigSwitchedByIgnition" SG_ 1639 BFS_LNV_aktiv 0;
BA_ "GenSigSendType" SG_ 1639 BFS_LNV_aktiv 3;
BA_ "GenSigSwitchedByIgnition" SG_ 1639 BFS_SNV_aktiv 0;
BA_ "GenSigSendType" SG_ 1639 BFS_SNV_aktiv 3;
BA_ "GenSigSwitchedByIgnition" SG_ 1639 BFS_KSV_aktiv 0;
BA_ "GenSigSendType" SG_ 1639 BFS_KSV_aktiv 3;
BA_ "GenSigSwitchedByIgnition" SG_ 1639 BFS_LKV_aktiv 0;
BA_ "GenSigSendType" SG_ 1639 BFS_LKV_aktiv 3;
BA_ "GenSigSwitchedByIgnition" SG_ 1639 BFS_STV_aktiv 0;
BA_ "GenSigSendType" SG_ 1639 BFS_STV_aktiv 3;
BA_ "GenSigSwitchedByIgnition" SG_ 1639 BFS_LHV_aktiv 0;
BA_ "GenSigSendType" SG_ 1639 BFS_LHV_aktiv 3;
BA_ "GenSigSwitchedByIgnition" SG_ 1639 BFS_LWV_aktiv 0;
BA_ "GenSigSendType" SG_ 1639 BFS_LWV_aktiv 3;
BA_ "GenSigSwitchedByIgnition" SG_ 1639 BFS_GHV_aktiv 0;
BA_ "GenSigSendType" SG_ 1639 BFS_GHV_aktiv 3;
BA_ "GenSigSwitchedByIgnition" SG_ 1639 BFS_KSS_Fahrt_aktiv 0;
BA_ "GenSigSendType" SG_ 1639 BFS_KSS_Fahrt_aktiv 3;
BA_ "GenSigSwitchedByIgnition" SG_ 1639 BFS_MMB_lokal_Stop 0;
BA_ "GenSigSendType" SG_ 1639 BFS_MMB_lokal_Stop 3;
BA_ "GenSigSwitchedByIgnition" SG_ 1639 BFS_Ruhestellung_Status 0;
BA_ "GenSigSendType" SG_ 1639 BFS_Ruhestellung_Status 3;
BA_ "GenSigSwitchedByIgnition" SG_ 1639 BFS_Seat_Locked 0;
BA_ "GenSigSendType" SG_ 1639 BFS_Seat_Locked 0;
BA_ "GenSigSwitchedByIgnition" SG_ 1639 BFS_MMB_storage 0;
BA_ "GenSigSendType" SG_ 1639 BFS_MMB_storage 3;
BA_ "GenSigSwitchedByIgnition" SG_ 1639 BFS_MMB_tipp 0;
BA_ "GenSigSendType" SG_ 1639 BFS_MMB_tipp 3;
BA_ "GenSigSwitchedByIgnition" SG_ 1639 BFS_MMB_tast 0;
BA_ "GenSigSendType" SG_ 1639 BFS_MMB_tast 3;
BA_ "GenSigSwitchedByIgnition" SG_ 1639 BFS_MMB_store_LED_on 0;
BA_ "GenSigSendType" SG_ 1639 BFS_MMB_store_LED_on 3;
BA_ "GenSigSwitchedByIgnition" SG_ 1639 BFS_MMB_storage_beep 0;
BA_ "GenSigSendType" SG_ 1639 BFS_MMB_storage_beep 3;
BA_ "GenSigSwitchedByIgnition" SG_ 1639 BFS_MMB_store 0;
BA_ "GenSigSendType" SG_ 1639 BFS_MMB_store 3;
BA_ "GenSigSwitchedByIgnition" SG_ 1639 BFS_MMB_glob_stop 0;
BA_ "GenSigSendType" SG_ 1639 BFS_MMB_glob_stop 3;
BA_ "GenSigSwitchedByIgnition" SG_ 1639 BFS_FSV_ausgeklappt 0;
BA_ "GenSigSendType" SG_ 1639 BFS_FSV_ausgeklappt 0;
BA_ "GenSigSwitchedByIgnition" SG_ 1178 FS_Fond_Bed_enable 0;
BA_ "GenSigSendType" SG_ 1178 FS_Fond_Bed_enable 3;
BA_ "GenSigSwitchedByIgnition" SG_ 1178 FS_Lehne_nicht_verriegelt 0;
BA_ "GenSigSendType" SG_ 1178 FS_Lehne_nicht_verriegelt 3;
BA_ "GenSigSwitchedByIgnition" SG_ 1178 FS_Spezialposition_anfahren 0;
BA_ "GenSigSendType" SG_ 1178 FS_Spezialposition_anfahren 3;
BA_ "GenSigSwitchedByIgnition" SG_ 1178 FS_Gurtbringer_Sperre 0;
BA_ "GenSigSendType" SG_ 1178 FS_Gurtbringer_Sperre 0;
BA_ "GenSigSwitchedByIgnition" SG_ 1178 FS_BFS_Sitzsym_Anfahrt 0;
BA_ "GenSigSendType" SG_ 1178 FS_BFS_Sitzsym_Anfahrt 3;
BA_ "GenSigSwitchedByIgnition" SG_ 1178 FS_Sitzfahrt_aktiv 0;
BA_ "GenSigSendType" SG_ 1178 FS_Sitzfahrt_aktiv 3;
BA_ "GenSigSwitchedByIgnition" SG_ 1178 FS_SLV_aktiv 0;
BA_ "GenSigSendType" SG_ 1178 FS_SLV_aktiv 3;
BA_ "GenSigSwitchedByIgnition" SG_ 1178 FS_SHV_aktiv 0;
BA_ "GenSigSendType" SG_ 1178 FS_SHV_aktiv 3;
BA_ "GenSigSwitchedByIgnition" SG_ 1178 FS_LNV_aktiv 0;
BA_ "GenSigSendType" SG_ 1178 FS_LNV_aktiv 3;
BA_ "GenSigSwitchedByIgnition" SG_ 1178 FS_SNV_aktiv 0;
BA_ "GenSigSendType" SG_ 1178 FS_SNV_aktiv 3;
BA_ "GenSigSwitchedByIgnition" SG_ 1178 FS_KSV_aktiv 0;
BA_ "GenSigSendType" SG_ 1178 FS_KSV_aktiv 3;
BA_ "GenSigSwitchedByIgnition" SG_ 1178 FS_LKV_aktiv 0;
BA_ "GenSigSendType" SG_ 1178 FS_LKV_aktiv 3;
BA_ "GenSigSwitchedByIgnition" SG_ 1178 FS_STV_aktiv 0;
BA_ "GenSigSendType" SG_ 1178 FS_STV_aktiv 3;
BA_ "GenSigSwitchedByIgnition" SG_ 1178 FS_LHV_aktiv 0;
BA_ "GenSigSendType" SG_ 1178 FS_LHV_aktiv 3;
BA_ "GenSigSwitchedByIgnition" SG_ 1178 FS_LWV_aktiv 0;
BA_ "GenSigSendType" SG_ 1178 FS_LWV_aktiv 3;
BA_ "GenSigSwitchedByIgnition" SG_ 1178 FS_GHV_aktiv 0;
BA_ "GenSigSendType" SG_ 1178 FS_GHV_aktiv 3;
BA_ "GenSigSwitchedByIgnition" SG_ 1178 FS_BFS_KSS_Anfahrt 0;
BA_ "GenSigSendType" SG_ 1178 FS_BFS_KSS_Anfahrt 3;
BA_ "GenSigSwitchedByIgnition" SG_ 1178 FS_MMB_lokal_Stop 0;
BA_ "GenSigSendType" SG_ 1178 FS_MMB_lokal_Stop 3;
BA_ "GenSigSwitchedByIgnition" SG_ 1178 FS_MMB_storage 0;
BA_ "GenSigSendType" SG_ 1178 FS_MMB_storage 3;
BA_ "GenSigSwitchedByIgnition" SG_ 1178 FS_MMB_tipp 0;
BA_ "GenSigSendType" SG_ 1178 FS_MMB_tipp 3;
BA_ "GenSigSwitchedByIgnition" SG_ 1178 FS_MMB_tast 0;
BA_ "GenSigSendType" SG_ 1178 FS_MMB_tast 3;
BA_ "GenSigSwitchedByIgnition" SG_ 1178 FS_MMB_store_LED_on 0;
BA_ "GenSigSendType" SG_ 1178 FS_MMB_store_LED_on 3;
BA_ "GenSigSwitchedByIgnition" SG_ 1178 FS_MMB_storage_beep 0;
BA_ "GenSigSendType" SG_ 1178 FS_MMB_storage_beep 3;
BA_ "GenSigSwitchedByIgnition" SG_ 1178 FS_MMB_store 0;
BA_ "GenSigSendType" SG_ 1178 FS_MMB_store 3;
BA_ "GenSigSwitchedByIgnition" SG_ 1178 FS_MMB_glob_stop 0;
BA_ "GenSigSendType" SG_ 1178 FS_MMB_glob_stop 3;
BA_ "GenSigSwitchedByIgnition" SG_ 1178 FS_EE_Fond_FS_enable 0;
BA_ "GenSigSendType" SG_ 1178 FS_EE_Fond_FS_enable 3;
BA_ "GenSigSwitchedByIgnition" SG_ 1178 FS_EE_Fond_BFS_enable 0;
BA_ "GenSigSendType" SG_ 1178 FS_EE_Fond_BFS_enable 3;
BA_ "GenSigSwitchedByIgnition" SG_ 1178 FS_BFS_Fond_Verst_enable 0;
BA_ "GenSigSendType" SG_ 1178 FS_BFS_Fond_Verst_enable 3;
BA_ "GenSigSwitchedByIgnition" SG_ 1178 FS_EE_BFS_enable 0;
BA_ "GenSigSendType" SG_ 1178 FS_EE_BFS_enable 3;
BA_ "GenSigSwitchedByIgnition" SG_ 1171 MFG_01_CRC 0;
BA_ "GenSigFuncType" SG_ 1171 MFG_01_CRC 2;
BA_ "GenSigSendType" SG_ 1171 MFG_01_CRC 0;
BA_ "GenSigSwitchedByIgnition" SG_ 1171 MFG_01_BZ 0;
BA_ "GenSigFuncType" SG_ 1171 MFG_01_BZ 1;
BA_ "GenSigSendType" SG_ 1171 MFG_01_BZ 0;
BA_ "GenSigSwitchedByIgnition" SG_ 1171 MF_ZV_Lock 0;
BA_ "GenSigSendType" SG_ 1171 MF_ZV_Lock 3;
BA_ "GenSigSwitchedByIgnition" SG_ 1171 MF_Motorweiterlauf 0;
BA_ "GenSigSendType" SG_ 1171 MF_Motorweiterlauf 3;
BA_ "GenSigSwitchedByIgnition" SG_ 1171 MF_Abzugssperre 0;
BA_ "GenSigSendType" SG_ 1171 MF_Abzugssperre 3;
BA_ "GenSigSwitchedByIgnition" SG_ 1171 MF_Anlassersperre 0;
BA_ "GenSigSendType" SG_ 1171 MF_Anlassersperre 3;
BA_ "GenSigSwitchedByIgnition" SG_ 1171 MF_Variante 0;
BA_ "GenSigSendType" SG_ 1171 MF_Variante 3;
BA_ "GenSigSwitchedByIgnition" SG_ 1171 MF_Schluessel_scan 0;
BA_ "GenSigSendType" SG_ 1171 MF_Schluessel_scan 3;
BA_ "GenSigSwitchedByIgnition" SG_ 1171 MF_Laderelais 0;
BA_ "GenSigSendType" SG_ 1171 MF_Laderelais 3;
BA_ "GenSigSwitchedByIgnition" SG_ 1171 MF_StartStopp_Info 0;
BA_ "GenSigSendType" SG_ 1171 MF_StartStopp_Info 0;
BA_ "GenSigSwitchedByIgnition" SG_ 1171 MF_Fernbed_ein 0;
BA_ "GenSigSendType" SG_ 1171 MF_Fernbed_ein 3;
BA_ "GenSigSwitchedByIgnition" SG_ 1171 MF_Standlicht 0;
BA_ "GenSigSendType" SG_ 1171 MF_Standlicht 3;
BA_ "GenSigSwitchedByIgnition" SG_ 1171 MF_Fahrlicht 0;
BA_ "GenSigSendType" SG_ 1171 MF_Fahrlicht 3;
BA_ "GenSigSwitchedByIgnition" SG_ 1171 MF_interm_Fernlicht 0;
BA_ "GenSigSendType" SG_ 1171 MF_interm_Fernlicht 3;
BA_ "GenSigSwitchedByIgnition" SG_ 1171 MF_Warnblinker 0;
BA_ "GenSigSendType" SG_ 1171 MF_Warnblinker 3;
BA_ "GenSigSwitchedByIgnition" SG_ 1171 MF_Fussraumbel 0;
BA_ "GenSigSendType" SG_ 1171 MF_Fussraumbel 3;
BA_ "GenSigSwitchedByIgnition" SG_ 1171 MF_Innenraumbel 0;
BA_ "GenSigSendType" SG_ 1171 MF_Innenraumbel 3;
BA_ "GenSigSwitchedByIgnition" SG_ 1171 MF_Innenraumbel_Unterdrueck 0;
BA_ "GenSigSendType" SG_ 1171 MF_Innenraumbel_Unterdrueck 3;
BA_ "GenSigSwitchedByIgnition" SG_ 1171 MF_Notstart 0;
BA_ "GenSigSendType" SG_ 1171 MF_Notstart 3;
BA_ "GenSigSwitchedByIgnition" SG_ 1171 MF_Blk_li 0;
BA_ "GenSigSendType" SG_ 1171 MF_Blk_li 3;
BA_ "GenSigSwitchedByIgnition" SG_ 1171 MF_Blk_re 0;
BA_ "GenSigSendType" SG_ 1171 MF_Blk_re 3;
BA_ "GenSigSwitchedByIgnition" SG_ 1171 MF_Lichthupe 0;
BA_ "GenSigSendType" SG_ 1171 MF_Lichthupe 3;
BA_ "GenSigSwitchedByIgnition" SG_ 1171 MF_Fernlicht 0;
BA_ "GenSigSendType" SG_ 1171 MF_Fernlicht 3;
BA_ "GenSigSwitchedByIgnition" SG_ 1171 MF_HFS_verriegeln 0;
BA_ "GenSigSendType" SG_ 1171 MF_HFS_verriegeln 3;
BA_ "GenSigSwitchedByIgnition" SG_ 1171 MF_HFS_entriegeln 0;
BA_ "GenSigSendType" SG_ 1171 MF_HFS_entriegeln 3;
BA_ "GenSigSwitchedByIgnition" SG_ 1171 MF_HBFS_verriegeln 0;
BA_ "GenSigSendType" SG_ 1171 MF_HBFS_verriegeln 3;
BA_ "GenSigSwitchedByIgnition" SG_ 1171 MF_HBFS_entriegeln 0;
BA_ "GenSigSendType" SG_ 1171 MF_HBFS_entriegeln 3;
BA_ "GenSigSwitchedByIgnition" SG_ 1171 MF_Tippwischen 0;
BA_ "GenSigSendType" SG_ 1171 MF_Tippwischen 3;
BA_ "GenSigSwitchedByIgnition" SG_ 1171 MF_Frontintervall 0;
BA_ "GenSigSendType" SG_ 1171 MF_Frontintervall 3;
BA_ "GenSigSwitchedByIgnition" SG_ 1171 MF_Wischerstufe_1 0;
BA_ "GenSigSendType" SG_ 1171 MF_Wischerstufe_1 3;
BA_ "GenSigSwitchedByIgnition" SG_ 1171 MF_Wischerstufe_2 0;
BA_ "GenSigSendType" SG_ 1171 MF_Wischerstufe_2 3;
BA_ "GenSigSwitchedByIgnition" SG_ 1171 MF_Frontwaschen 0;
BA_ "GenSigSendType" SG_ 1171 MF_Frontwaschen 3;
BA_ "GenSigSwitchedByIgnition" SG_ 1171 MF_nachtr_Stopp_Anf 0;
BA_ "GenSigSendType" SG_ 1171 MF_nachtr_Stopp_Anf 0;
BA_ "GenSigSwitchedByIgnition" SG_ 1171 MF_Heckintervall 0;
BA_ "GenSigSendType" SG_ 1171 MF_Heckintervall 3;
BA_ "GenSigSwitchedByIgnition" SG_ 1171 MF_Heckwaschen 0;
BA_ "GenSigSendType" SG_ 1171 MF_Heckwaschen 3;
BA_ "GenSigSwitchedByIgnition" SG_ 1171 MF_Summer 0;
BA_ "GenSigSendType" SG_ 1171 MF_Summer 3;
BA_ "GenSigSwitchedByIgnition" SG_ 1171 MF_Alarm_Blinkertakt 0;
BA_ "GenSigSendType" SG_ 1171 MF_Alarm_Blinkertakt 3;
BA_ "GenSigSwitchedByIgnition" SG_ 1171 MF_Alarm_Blinker 0;
BA_ "GenSigSendType" SG_ 1171 MF_Alarm_Blinker 3;
BA_ "GenSigSwitchedByIgnition" SG_ 1171 MF_TFL_Abschaltung 0;
BA_ "GenSigSendType" SG_ 1171 MF_TFL_Abschaltung 3;
BA_ "GenSigSwitchedByIgnition" SG_ 1171 MF_interm_Takt 0;
BA_ "GenSigSendType" SG_ 1171 MF_interm_Takt 3;
BA_ "GenSigSwitchedByIgnition" SG_ 1171 MF_Tuerentriegelung_hinten 0;
BA_ "GenSigSendType" SG_ 1171 MF_Tuerentriegelung_hinten 3;
BA_ "GenSigSwitchedByIgnition" SG_ 1171 MF_interm_Fahrlicht 0;
BA_ "GenSigSendType" SG_ 1171 MF_interm_Fahrlicht 3;
BA_ "GenSigSwitchedByIgnition" SG_ 1171 MF_Signalhorn 0;
BA_ "GenSigSendType" SG_ 1171 MF_Signalhorn 3;
BA_ "GenSigSwitchedByIgnition" SG_ 1171 MF_FH_FT_hoch 0;
BA_ "GenSigSendType" SG_ 1171 MF_FH_FT_hoch 3;
BA_ "GenSigSwitchedByIgnition" SG_ 1171 MF_FH_FT_tief 0;
BA_ "GenSigSendType" SG_ 1171 MF_FH_FT_tief 3;
BA_ "GenSigSwitchedByIgnition" SG_ 1171 MF_FH_BT_hoch 0;
BA_ "GenSigSendType" SG_ 1171 MF_FH_BT_hoch 3;
BA_ "GenSigSwitchedByIgnition" SG_ 1171 MF_FH_BT_tief 0;
BA_ "GenSigSendType" SG_ 1171 MF_FH_BT_tief 3;
BA_ "GenSigSwitchedByIgnition" SG_ 1171 MF_FT_verriegeln 0;
BA_ "GenSigSendType" SG_ 1171 MF_FT_verriegeln 3;
BA_ "GenSigSwitchedByIgnition" SG_ 1171 MF_FT_entriegeln 0;
BA_ "GenSigSendType" SG_ 1171 MF_FT_entriegeln 3;
BA_ "GenSigSwitchedByIgnition" SG_ 1171 MF_BT_verriegeln 0;
BA_ "GenSigSendType" SG_ 1171 MF_BT_verriegeln 3;
BA_ "GenSigSwitchedByIgnition" SG_ 1171 MF_BT_entriegeln 0;
BA_ "GenSigSendType" SG_ 1171 MF_BT_entriegeln 3;
BA_ "GenSigSendType" SG_ 1164 MFG_Klappe_Status 0;
BA_ "GenSigSwitchedByIgnition" SG_ 1164 MF_Radiomute 0;
BA_ "GenSigSendType" SG_ 1164 MF_Radiomute 3;
BA_ "GenSigSwitchedByIgnition" SG_ 1164 MF_Relais_2_Batterie 0;
BA_ "GenSigSendType" SG_ 1164 MF_Relais_2_Batterie 3;
BA_ "Fehlerwert" SG_ 1164 MF_Batteriediagnose 7;
BA_ "GenSigSwitchedByIgnition" SG_ 1164 MF_Batteriediagnose 0;
BA_ "GenSigSendType" SG_ 1164 MF_Batteriediagnose 0;
BA_ "GenSigSwitchedByIgnition" SG_ 1164 MFG_AppConnect_Anf 0;
BA_ "GenSigSendType" SG_ 1164 MFG_AppConnect_Anf 4;
BA_ "GenSigSwitchedByIgnition" SG_ 1164 MF_Lampenausfall 0;
BA_ "GenSigSendType" SG_ 1164 MF_Lampenausfall 0;
BA_ "GenSigSwitchedByIgnition" SG_ 1164 MF_Blinker_L_Sta 0;
BA_ "GenSigSendType" SG_ 1164 MF_Blinker_L_Sta 3;
BA_ "GenSigSwitchedByIgnition" SG_ 1164 MF_Blinker_R_Sta 0;
BA_ "GenSigSendType" SG_ 1164 MF_Blinker_R_Sta 3;
BA_ "GenSigSwitchedByIgnition" SG_ 1164 MF_interm_Nebelscheinwerfer 0;
BA_ "GenSigSendType" SG_ 1164 MF_interm_Nebelscheinwerfer 0;
BA_ "GenSigSwitchedByIgnition" SG_ 1164 MF_Generatordiagnose 0;
BA_ "GenSigStartValue" SG_ 1164 MF_Generatordiagnose 3;
BA_ "GenSigSendType" SG_ 1164 MF_Generatordiagnose 0;
BA_ "GenSigSendType" SG_ 1164 MF_Heck_entriegeln 0;
BA_ "GenSigSendType" SG_ 1164 MF_Heck_verriegeln 0;
BA_ "GenSigSendType" SG_ 1164 MF_2BatSOCzugering 0;
BA_ "GenSigSendType" SG_ 1164 MF_Fahrerhinweis 0;
BA_ "GenSigSwitchedByIgnition" SG_ 1164 MF_ZV_Unlock 0;
BA_ "GenSigSendType" SG_ 1164 MF_ZV_Unlock 0;
BA_ "GenSigSwitchedByIgnition" SG_ 1164 MF_Tuerverriegelung_hinten 0;
BA_ "GenSigSendType" SG_ 1164 MF_Tuerverriegelung_hinten 3;
BA_ "GenSigSendType" SG_ 1164 MF_2BattAb 0;
BA_ "GenSigSendType" SG_ 1164 MF_2BattHlkAnf 0;
BA_ "GenSigSendType" SG_ 1164 MF_2BattLadWarn 0;
BA_ "GenSigSendType" SG_ 1164 MF_2BattLlaAnf 0;
BA_ "GenSigSendType" SG_ 1164 MF_2BattSpannungsAnf 0;
BA_ "GenSigSendType" SG_ 1164 MF_NotStartAktiv 0;
BA_ "GenSigSendType" SG_ 1164 MF_ExterneLadungWarn 0;
BA_ "Fehlerwert" SG_ 1164 MF_LSH_Zielzeit 15;
BA_ "GenSigSwitchedByIgnition" SG_ 1164 MF_LSH_Zielzeit 0;
BA_ "GenSigStartValue" SG_ 1164 MF_LSH_Zielzeit 14;
BA_ "GenSigSendType" SG_ 1164 MF_LSH_Zielzeit 0;
BA_ "GenSigSwitchedByIgnition" SG_ 1164 MF_LSH_Abschaltstufe 0;
BA_ "GenSigSendType" SG_ 1164 MF_LSH_Abschaltstufe 0;
BA_ "GenSigSwitchedByIgnition" SG_ 1164 MF_LSH_Einschaltverbot 0;
BA_ "GenSigSendType" SG_ 1164 MF_LSH_Einschaltverbot 0;
BA_ "GenSigSwitchedByIgnition" SG_ 817 MFL_Zaehler 0;
BA_ "GenSigSendType" SG_ 817 MFL_Zaehler 0;
BA_ "GenSigSwitchedByIgnition" SG_ 817 MFL_Toggle 0;
BA_ "GenSigSendType" SG_ 817 MFL_Toggle 0;
BA_ "GenSigSwitchedByIgnition" SG_ 817 MFL_Lokalaktiv 0;
BA_ "GenSigSendType" SG_ 817 MFL_Lokalaktiv 0;
BA_ "GenSigSendType" SG_ 817 MFL_M_Taste 0;
BA_ "GenSigSwitchedByIgnition" SG_ 817 MFL_Paddle_Verbau 0;
BA_ "GenSigSendType" SG_ 817 MFL_Paddle_Verbau 0;
BA_ "GenSigSwitchedByIgnition" SG_ 817 MFL_Tastencode_1 0;
BA_ "GenSigSendType" SG_ 817 MFL_Tastencode_1 0;
BA_ "GenSigSwitchedByIgnition" SG_ 817 MFL_Tastencode_2 0;
BA_ "GenSigSendType" SG_ 817 MFL_Tastencode_2 0;
BA_ "GenSigSwitchedByIgnition" SG_ 817 MFL_Eventcode_1 0;
BA_ "GenSigSendType" SG_ 817 MFL_Eventcode_1 0;
BA_ "GenSigSwitchedByIgnition" SG_ 817 MFL_Eventcode_2 0;
BA_ "GenSigSendType" SG_ 817 MFL_Eventcode_2 0;
BA_ "GenSigSwitchedByIgnition" SG_ 817 MFL_Marke 0;
BA_ "GenSigFuncType" SG_ 817 MFL_Marke 8;
BA_ "GenSigSendType" SG_ 817 MFL_Marke 0;
BA_ "GenSigSwitchedByIgnition" SG_ 817 MFL_Variante 0;
BA_ "GenSigFuncType" SG_ 817 MFL_Variante 8;
BA_ "GenSigSendType" SG_ 817 MFL_Variante 0;
BA_ "GenSigSwitchedByIgnition" SG_ 817 MFL_Dummy_0_Signal_1 0;
BA_ "GenSigSendType" SG_ 817 MFL_Dummy_0_Signal_1 0;
BA_ "GenSigSendType" SG_ 817 MFL_Tip_Down 5;
BA_ "GenSigSendType" SG_ 817 MFL_Tip_Up 5;
BA_ "Fehlerwert" SG_ 817 MFL_SatModul_links_Err 1;
BA_ "GenSigSwitchedByIgnition" SG_ 817 MFL_SatModul_links_Err 0;
BA_ "GenSigFuncType" SG_ 817 MFL_SatModul_links_Err 5;
BA_ "GenSigSendType" SG_ 817 MFL_SatModul_links_Err 0;
BA_ "Fehlerwert" SG_ 817 MFL_SatModul_rechts_Err 1;
BA_ "GenSigSwitchedByIgnition" SG_ 817 MFL_SatModul_rechts_Err 0;
BA_ "GenSigFuncType" SG_ 817 MFL_SatModul_rechts_Err 5;
BA_ "GenSigSendType" SG_ 817 MFL_SatModul_rechts_Err 0;
BA_ "Fehlerwert" SG_ 817 MFL_Fehler_Codierung 1;
BA_ "GenSigSwitchedByIgnition" SG_ 817 MFL_Fehler_Codierung 0;
BA_ "GenSigSendType" SG_ 817 MFL_Fehler_Codierung 0;
BA_ "GenSigSwitchedByIgnition" SG_ 817 MFL_Dummy_0_Signal_3 0;
BA_ "GenSigSendType" SG_ 817 MFL_Dummy_0_Signal_3 0;
BA_ "GenSigSwitchedByIgnition" SG_ 817 MFL_LR_HZG_Status 0;
BA_ "GenSigSendType" SG_ 817 MFL_LR_HZG_Status 0;
BA_ "Fehlerwert" SG_ 817 MFL_LR_HZG_Err 1;
BA_ "GenSigSwitchedByIgnition" SG_ 817 MFL_LR_HZG_Err 0;
BA_ "GenSigSendType" SG_ 817 MFL_LR_HZG_Err 0;
BA_ "GenSigSwitchedByIgnition" SG_ 817 MFL_Signalhorn 0;
BA_ "GenSigSendType" SG_ 817 MFL_Signalhorn 5;
BA_ "Fehlerwert" SG_ 817 MFL_Signalhorn_Err 1;
BA_ "GenSigSwitchedByIgnition" SG_ 817 MFL_Signalhorn_Err 0;
BA_ "GenSigSendType" SG_ 817 MFL_Signalhorn_Err 0;
BA_ "Fehlerwert" SG_ 817 MFL_Tip_links_Err 1;
BA_ "GenSigSwitchedByIgnition" SG_ 817 MFL_Tip_links_Err 0;
BA_ "GenSigSendType" SG_ 817 MFL_Tip_links_Err 0;
BA_ "Fehlerwert" SG_ 817 MFL_Tip_rechts_Err 1;
BA_ "GenSigSwitchedByIgnition" SG_ 817 MFL_Tip_rechts_Err 0;
BA_ "GenSigSendType" SG_ 817 MFL_Tip_rechts_Err 0;
BA_ "Fehlerwert" SG_ 817 MFL_Taste_links_Err 1;
BA_ "GenSigSwitchedByIgnition" SG_ 817 MFL_Taste_links_Err 0;
BA_ "GenSigSendType" SG_ 817 MFL_Taste_links_Err 0;
BA_ "Fehlerwert" SG_ 817 MFL_Taste_rechts_Err 1;
BA_ "GenSigSwitchedByIgnition" SG_ 817 MFL_Taste_rechts_Err 0;
BA_ "GenSigSendType" SG_ 817 MFL_Taste_rechts_Err 0;
BA_ "Fehlerwert" SG_ 817 MFL_ECU_Err 1;
BA_ "GenSigSwitchedByIgnition" SG_ 817 MFL_ECU_Err 0;
BA_ "GenSigSendType" SG_ 817 MFL_ECU_Err 0;
BA_ "Fehlerwert" SG_ 817 MFL_Response_Err 1;
BA_ "GenSigSwitchedByIgnition" SG_ 817 MFL_Response_Err 0;
BA_ "GenSigSendType" SG_ 817 MFL_Response_Err 0;
BA_ "GenSigSwitchedByIgnition" SG_ 560 MFL_Beruehrungserkennung 0;
BA_ "GenSigSendType" SG_ 560 MFL_Beruehrungserkennung 3;
BA_ "Fehlerwert" SG_ 560 MFL_Touch_Event 15;
BA_ "GenSigSwitchedByIgnition" SG_ 560 MFL_Touch_Event 0;
BA_ "GenSigSendType" SG_ 560 MFL_Touch_Event 3;
BA_ "GenSigSwitchedByIgnition" SG_ 2463978751 MFL_Vibrationsimpuls_rechts 0;
BA_ "GenSigSendType" SG_ 2463978751 MFL_Vibrationsimpuls_rechts 4;
BA_ "GenSigSwitchedByIgnition" SG_ 2463978751 MFL_Vibrationsimpuls_links 0;
BA_ "GenSigSendType" SG_ 2463978751 MFL_Vibrationsimpuls_links 4;
BA_ "GenSigSwitchedByIgnition" SG_ 2463978751 MFL_Tasten_Volume_benoetigt 0;
BA_ "GenSigSendType" SG_ 2463978751 MFL_Tasten_Volume_benoetigt 0;
BA_ "GenSigSwitchedByIgnition" SG_ 2463978751 MFL_Tasten_UpDownOK_benoetigt 0;
BA_ "GenSigSendType" SG_ 2463978751 MFL_Tasten_UpDownOK_benoetigt 0;
BA_ "GenSigSwitchedByIgnition" SG_ 2463978751 MFL_Taste_SDS_benoetigt 0;
BA_ "GenSigSendType" SG_ 2463978751 MFL_Taste_SDS_benoetigt 0;
BA_ "GenSigSwitchedByIgnition" SG_ 1471 MFL_Tastencode_1 0;
BA_ "GenSigSendType" SG_ 1471 MFL_Tastencode_1 1;
BA_ "GenSigSwitchedByIgnition" SG_ 1471 MFL_Tastencode_2 0;
BA_ "GenSigSendType" SG_ 1471 MFL_Tastencode_2 1;
BA_ "GenSigSwitchedByIgnition" SG_ 1471 MFL_Eventcode_1 0;
BA_ "GenSigSendType" SG_ 1471 MFL_Eventcode_1 1;
BA_ "GenSigSwitchedByIgnition" SG_ 1471 MFL_Eventcode_2 0;
BA_ "GenSigSendType" SG_ 1471 MFL_Eventcode_2 1;
BA_ "GenSigSwitchedByIgnition" SG_ 1471 MFL_Marke 0;
BA_ "GenSigFuncType" SG_ 1471 MFL_Marke 8;
BA_ "GenSigSendType" SG_ 1471 MFL_Marke 1;
BA_ "GenSigSwitchedByIgnition" SG_ 1471 MFL_Variante 0;
BA_ "GenSigFuncType" SG_ 1471 MFL_Variante 8;
BA_ "GenSigSendType" SG_ 1471 MFL_Variante 1;
BA_ "GenSigSwitchedByIgnition" SG_ 958 Motor_14_CRC 0;
BA_ "GenSigFuncType" SG_ 958 Motor_14_CRC 2;
BA_ "GenSigSendType" SG_ 958 Motor_14_CRC 0;
BA_ "GenSigSwitchedByIgnition" SG_ 958 Motor_14_BZ 0;
BA_ "GenSigFuncType" SG_ 958 Motor_14_BZ 1;
BA_ "GenSigSendType" SG_ 958 Motor_14_BZ 0;
BA_ "GenSigSwitchedByIgnition" SG_ 958 MO_StartStopp_Status 0;
BA_ "GenSigSendType" SG_ 958 MO_StartStopp_Status 0;
BA_ "GenSigSwitchedByIgnition" SG_ 958 MO_StartStopp_Wiederstart 0;
BA_ "GenSigSendType" SG_ 958 MO_StartStopp_Wiederstart 3;
BA_ "GenSigSwitchedByIgnition" SG_ 958 MO_StartStopp_Motorstopp 0;
BA_ "GenSigSendType" SG_ 958 MO_StartStopp_Motorstopp 3;
BA_ "GenSigSwitchedByIgnition" SG_ 958 MO_Freig_Reku 0;
BA_ "GenSigSendType" SG_ 958 MO_Freig_Reku 0;
BA_ "GenSigSwitchedByIgnition" SG_ 958 MO_Kl_75 0;
BA_ "GenSigSendType" SG_ 958 MO_Kl_75 3;
BA_ "GenSigSwitchedByIgnition" SG_ 958 MO_Kl_50 0;
BA_ "GenSigSendType" SG_ 958 MO_Kl_50 3;
BA_ "Fehlerwert" SG_ 958 MO_Gangposition 15;
BA_ "GenSigSwitchedByIgnition" SG_ 958 MO_Gangposition 0;
BA_ "GenSigStartValue" SG_ 958 MO_Gangposition 14;
BA_ "GenSigSendType" SG_ 958 MO_Gangposition 3;
BA_ "GenSigSwitchedByIgnition" SG_ 958 MO_StartStopp_Fahrerwunsch 0;
BA_ "GenSigSendType" SG_ 958 MO_StartStopp_Fahrerwunsch 0;
BA_ "GenSigSwitchedByIgnition" SG_ 958 MO_HYB_Fahrbereitschaft 0;
BA_ "GenSigSendType" SG_ 958 MO_HYB_Fahrbereitschaft 0;
BA_ "GenSigSwitchedByIgnition" SG_ 958 MO_Ext_E_Fahrt_aktiv 0;
BA_ "NWM-WakeupAllowed" SG_ 958 MO_Ext_E_Fahrt_aktiv 1;
BA_ "GenSigSendType" SG_ 958 MO_Ext_E_Fahrt_aktiv 3;
BA_ "GenSigSwitchedByIgnition" SG_ 958 MO_Fahrer_bremst 0;
BA_ "GenSigSendType" SG_ 958 MO_Fahrer_bremst 3;
BA_ "GenSigSwitchedByIgnition" SG_ 958 MO_QBit_Fahrer_bremst 0;
BA_ "GenSigStartValue" SG_ 958 MO_QBit_Fahrer_bremst 1;
BA_ "GenSigSendType" SG_ 958 MO_QBit_Fahrer_bremst 3;
BA_ "GenSigSwitchedByIgnition" SG_ 958 MO_BLS 0;
BA_ "GenSigSendType" SG_ 958 MO_BLS 3;
BA_ "GenSigSwitchedByIgnition" SG_ 958 MO_Konsistenz_Bremsped 0;
BA_ "GenSigSendType" SG_ 958 MO_Konsistenz_Bremsped 3;
BA_ "GenSigSwitchedByIgnition" SG_ 958 MO_Timeout_ESP 0;
BA_ "GenSigSendType" SG_ 958 MO_Timeout_ESP 3;
BA_ "GenSigSwitchedByIgnition" SG_ 958 MO_Klima_Eingr 0;
BA_ "GenSigSendType" SG_ 958 MO_Klima_Eingr 3;
BA_ "GenSigSwitchedByIgnition" SG_ 958 MO_Aussp_Anlass 0;
BA_ "GenSigSendType" SG_ 958 MO_Aussp_Anlass 3;
BA_ "GenSigSwitchedByIgnition" SG_ 958 MO_Freig_Anlass 0;
BA_ "GenSigSendType" SG_ 958 MO_Freig_Anlass 3;
BA_ "GenSigSwitchedByIgnition" SG_ 958 MO_Kuppl_schalter 0;
BA_ "GenSigSendType" SG_ 958 MO_Kuppl_schalter 3;
BA_ "GenSigSwitchedByIgnition" SG_ 958 MO_Interlock 0;
BA_ "GenSigSendType" SG_ 958 MO_Interlock 3;
BA_ "GenSigSwitchedByIgnition" SG_ 958 MO_Motor_laeuft 0;
BA_ "GenSigSendType" SG_ 958 MO_Motor_laeuft 3;
BA_ "GenSigSwitchedByIgnition" SG_ 958 MO_Kickdown 0;
BA_ "GenSigSendType" SG_ 958 MO_Kickdown 3;
BA_ "GenSigSwitchedByIgnition" SG_ 958 MO_QBit_KL_75 0;
BA_ "GenSigStartValue" SG_ 958 MO_QBit_KL_75 1;
BA_ "GenSigSendType" SG_ 958 MO_QBit_KL_75 3;
BA_ "GenSigSwitchedByIgnition" SG_ 958 MO_EKlKomLeiRed 0;
BA_ "GenSigSendType" SG_ 958 MO_EKlKomLeiRed 0;
BA_ "GenSigSwitchedByIgnition" SG_ 958 MO_Handshake_STH 0;
BA_ "GenSigSendType" SG_ 958 MO_Handshake_STH 0;
BA_ "GenSigSwitchedByIgnition" SG_ 958 MO_BKV_Unterdruckwarnung 0;
BA_ "GenSigSendType" SG_ 958 MO_BKV_Unterdruckwarnung 0;
BA_ "GenSigSwitchedByIgnition" SG_ 958 MO_Freigabe_Segeln 0;
BA_ "GenSigSendType" SG_ 958 MO_Freigabe_Segeln 0;
BA_ "GenSigSwitchedByIgnition" SG_ 958 MO_PTC_Status 0;
BA_ "GenSigSendType" SG_ 958 MO_PTC_Status 0;
BA_ "GenSigSwitchedByIgnition" SG_ 958 MO_QBit_Gangposition 0;
BA_ "GenSigStartValue" SG_ 958 MO_QBit_Gangposition 1;
BA_ "GenSigSendType" SG_ 958 MO_QBit_Gangposition 3;
BA_ "GenSigSwitchedByIgnition" SG_ 958 MO_Signalquelle_Gangposition 0;
BA_ "GenSigSendType" SG_ 958 MO_Signalquelle_Gangposition 0;
BA_ "GenSigSwitchedByIgnition" SG_ 958 MO_Remotestart_Betrieb 0;
BA_ "GenSigSendType" SG_ 958 MO_Remotestart_Betrieb 3;
BA_ "GenSigSwitchedByIgnition" SG_ 958 MO_Remotestart_moeglich 0;
BA_ "GenSigSendType" SG_ 958 MO_Remotestart_moeglich 0;
BA_ "GenSigSwitchedByIgnition" SG_ 958 MO_FMAus_aktiv 0;
BA_ "GenSigSendType" SG_ 958 MO_FMAus_aktiv 3;
BA_ "GenSigSwitchedByIgnition" SG_ 958 MO_FMAus_Startvariante 0;
BA_ "GenSigSendType" SG_ 958 MO_FMAus_Startvariante 3;
BA_ "GenSigSwitchedByIgnition" SG_ 958 MO_BMS_NV_Anf_stuetzen 0;
BA_ "GenSigSendType" SG_ 958 MO_BMS_NV_Anf_stuetzen 3;
BA_ "GenSigSwitchedByIgnition" SG_ 958 MO_Zylinderabschaltung 0;
BA_ "GenSigSendType" SG_ 958 MO_Zylinderabschaltung 3;
BA_ "GenSigSwitchedByIgnition" SG_ 958 MO_HYB_VM_aktiv 0;
BA_ "GenSigSendType" SG_ 958 MO_HYB_VM_aktiv 3;
BA_ "GenSigSwitchedByIgnition" SG_ 958 MO_StartVorauss_erfuellt 0;
BA_ "GenSigStartValue" SG_ 958 MO_StartVorauss_erfuellt 1;
BA_ "GenSigSendType" SG_ 958 MO_StartVorauss_erfuellt 3;
BA_ "GenSigSwitchedByIgnition" SG_ 1648 MO_max_Ladedruck 0;
BA_ "GenSigFuncType" SG_ 1648 MO_max_Ladedruck 8;
BA_ "GenSigSendType" SG_ 1648 MO_max_Ladedruck 0;
BA_ "GenSigSwitchedByIgnition" SG_ 1648 MO_ANC_Kennfeld_Anf 0;
BA_ "GenSigSendType" SG_ 1648 MO_ANC_Kennfeld_Anf 3;
BA_ "GenSigSwitchedByIgnition" SG_ 1648 MO_Bremslicht_Reku 0;
BA_ "GenSigSendType" SG_ 1648 MO_Bremslicht_Reku 3;
BA_ "GenSigSwitchedByIgnition" SG_ 1648 MO_StartStopp_PopUp 0;
BA_ "GenSigSendType" SG_ 1648 MO_StartStopp_PopUp 3;
BA_ "GenSigSwitchedByIgnition" SG_ 1648 MO1_Sperr_Info_WFS 0;
BA_ "GenSigSendType" SG_ 1648 MO1_Sperr_Info_WFS 3;
BA_ "GenSigSwitchedByIgnition" SG_ 1648 MO1_Freigabe_Info_WFS 0;
BA_ "GenSigSendType" SG_ 1648 MO1_Freigabe_Info_WFS 3;
BA_ "GenSigSwitchedByIgnition" SG_ 1648 MO_EPCL 0;
BA_ "GenSigSendType" SG_ 1648 MO_EPCL 3;
BA_ "GenSigSwitchedByIgnition" SG_ 1648 MO_Zylabsch_Texte_02 0;
BA_ "GenSigSendType" SG_ 1648 MO_Zylabsch_Texte_02 3;
BA_ "GenSigSwitchedByIgnition" SG_ 1648 MO_Fahrzeugtyp 0;
BA_ "GenSigFuncType" SG_ 1648 MO_Fahrzeugtyp 8;
BA_ "GenSigSendType" SG_ 1648 MO_Fahrzeugtyp 0;
BA_ "GenSigSwitchedByIgnition" SG_ 1648 MO_NMAX_Schaltanzeige 0;
BA_ "GenSigSendType" SG_ 1648 MO_NMAX_Schaltanzeige 3;
BA_ "GenSigSwitchedByIgnition" SG_ 1648 MO_Abstellzeit 0;
BA_ "GenSigStartValue" SG_ 1648 MO_Abstellzeit 254;
BA_ "GenSigSendType" SG_ 1648 MO_Abstellzeit 0;
BA_ "GenSigSwitchedByIgnition" SG_ 1648 MO_Abstellzeit_Status 0;
BA_ "GenSigSendType" SG_ 1648 MO_Abstellzeit_Status 0;
BA_ "GenSigSwitchedByIgnition" SG_ 1648 MO1_Freigabe_Verfallsinfo_WFS 0;
BA_ "GenSigSendType" SG_ 1648 MO1_Freigabe_Verfallsinfo_WFS 3;
BA_ "GenSigSwitchedByIgnition" SG_ 1648 MO_Hybrid_StartStopp_LED 0;
BA_ "GenSigSendType" SG_ 1648 MO_Hybrid_StartStopp_LED 3;
BA_ "GenSigSwitchedByIgnition" SG_ 1648 MO_Fehler_Zylabsch 0;
BA_ "GenSigSendType" SG_ 1648 MO_Fehler_Zylabsch 0;
BA_ "GenSigSwitchedByIgnition" SG_ 1648 MO_Anzahl_Abgesch_Zyl 0;
BA_ "GenSigSendType" SG_ 1648 MO_Anzahl_Abgesch_Zyl 3;
BA_ "GenSigSwitchedByIgnition" SG_ 1648 MO_Zylabsch_Texte 0;
BA_ "GenSigSendType" SG_ 1648 MO_Zylabsch_Texte 0;
BA_ "GenSigSwitchedByIgnition" SG_ 1648 MO_Ethanol_BS_Texte 0;
BA_ "GenSigSendType" SG_ 1648 MO_Ethanol_BS_Texte 0;
BA_ "GenSigSwitchedByIgnition" SG_ 1648 MO_Drehzahl_Warnung 0;
BA_ "GenSigSendType" SG_ 1648 MO_Drehzahl_Warnung 0;
BA_ "GenSigSwitchedByIgnition" SG_ 1648 MO_obere_Drehzahlgrenze 0;
BA_ "GenSigSendType" SG_ 1648 MO_obere_Drehzahlgrenze 0;
BA_ "GenSigSwitchedByIgnition" SG_ 967 MO_Kuehlerluefter_MUX 0;
BA_ "GenSigSendType" SG_ 967 MO_Kuehlerluefter_MUX 0;
BA_ "Fehlerwert" SG_ 967 MO_Kuehlerluefter_1 127;
BA_ "GenSigSwitchedByIgnition" SG_ 967 MO_Kuehlerluefter_1 0;
BA_ "GenSigStartValue" SG_ 967 MO_Kuehlerluefter_1 126;
BA_ "Fehlerwert" SG_ 967 MO_Kuehlerluefter_2 127;
BA_ "GenSigSwitchedByIgnition" SG_ 967 MO_Kuehlerluefter_2 0;
BA_ "GenSigStartValue" SG_ 967 MO_Kuehlerluefter_2 126;
BA_ "GenSigSwitchedByIgnition" SG_ 967 MO_EFLEX_Lampe 0;
BA_ "GenSigSendType" SG_ 967 MO_EFLEX_Lampe 0;
BA_ "Fehlerwert" SG_ 967 MO_KJS_nicht_bereit 1;
BA_ "GenSigSwitchedByIgnition" SG_ 967 MO_KJS_nicht_bereit 0;
BA_ "GenSigSendType" SG_ 967 MO_KJS_nicht_bereit 0;
BA_ "GenSigSwitchedByIgnition" SG_ 967 MO_ITM_Warnung_Pumpe 0;
BA_ "GenSigSendType" SG_ 967 MO_ITM_Warnung_Pumpe 0;
BA_ "GenSigSwitchedByIgnition" SG_ 967 WIV_Anzeige_aktiv 0;
BA_ "GenSigSendType" SG_ 967 WIV_Anzeige_aktiv 0;
BA_ "GenSigSwitchedByIgnition" SG_ 967 WIV_Oelmin_Warn 0;
BA_ "GenSigSendType" SG_ 967 WIV_Oelmin_Warn 0;
BA_ "GenSigSwitchedByIgnition" SG_ 967 WIV_Sensorfehler 0;
BA_ "GenSigSendType" SG_ 967 WIV_Sensorfehler 0;
BA_ "GenSigSwitchedByIgnition" SG_ 967 WIV_Schieflage 0;
BA_ "GenSigSendType" SG_ 967 WIV_Schieflage 0;
BA_ "GenSigSwitchedByIgnition" SG_ 967 WIV_Oelstand 0;
BA_ "GenSigSendType" SG_ 967 WIV_Oelstand 0;
BA_ "GenSigSwitchedByIgnition" SG_ 967 MO_Zustand_HWP 0;
BA_ "GenSigStartValue" SG_ 967 MO_Zustand_HWP 1;
BA_ "GenSigSendType" SG_ 967 MO_Zustand_HWP 0;
BA_ "GenSigSwitchedByIgnition" SG_ 967 OLEV_Systemstoerung 0;
BA_ "GenSigSendType" SG_ 967 OLEV_Systemstoerung 0;
BA_ "GenSigSwitchedByIgnition" SG_ 967 MO_Oelwarnung_max 0;
BA_ "GenSigSendType" SG_ 967 MO_Oelwarnung_max 0;
BA_ "GenSigSwitchedByIgnition" SG_ 967 WIV_Oelsystem_aktiv 0;
BA_ "GenSigSendType" SG_ 967 WIV_Oelsystem_aktiv 0;
BA_ "GenSigSwitchedByIgnition" SG_ 967 WIV_nicht_betriebswarm 0;
BA_ "GenSigSendType" SG_ 967 WIV_nicht_betriebswarm 0;
BA_ "GenSigSwitchedByIgnition" SG_ 967 WIV_Ueberfuell_Warn 0;
BA_ "GenSigSendType" SG_ 967 WIV_Ueberfuell_Warn 0;
BA_ "GenSigSwitchedByIgnition" SG_ 967 WIV_laufender_Motor 0;
BA_ "GenSigSendType" SG_ 967 WIV_laufender_Motor 0;
BA_ "GenSigSwitchedByIgnition" SG_ 967 MO_E_Warnungen 0;
BA_ "GenSigSendType" SG_ 967 MO_E_Warnungen 0;
BA_ "GenSigSwitchedByIgnition" SG_ 967 MO_Text_Motorstart 0;
BA_ "GenSigSendType" SG_ 967 MO_Text_Motorstart 0;
BA_ "GenSigSwitchedByIgnition" SG_ 967 MO_E_Texte 0;
BA_ "GenSigSendType" SG_ 967 MO_E_Texte 0;
BA_ "GenSigSwitchedByIgnition" SG_ 967 WIV_Oeldyn_avl 0;
BA_ "GenSigSendType" SG_ 967 WIV_Oeldyn_avl 0;
BA_ "GenSigSwitchedByIgnition" SG_ 967 MO_Text_Partikelfil_Reg 0;
BA_ "GenSigSendType" SG_ 967 MO_Text_Partikelfil_Reg 0;
BA_ "GenSigSwitchedByIgnition" SG_ 967 OLEV_Oelstand_nicht_vorhanden 0;
BA_ "GenSigSendType" SG_ 967 OLEV_Oelstand_nicht_vorhanden 0;
BA_ "GenSigSwitchedByIgnition" SG_ 967 WIV_Oelmenge 0;
BA_ "GenSigSendType" SG_ 967 WIV_Oelmenge 0;
BA_ "GenSigSwitchedByIgnition" SG_ 967 MO_Systemlampe 0;
BA_ "GenSigSendType" SG_ 967 MO_Systemlampe 0;
BA_ "GenSigSwitchedByIgnition" SG_ 967 MO_OBD2_Lampe 0;
BA_ "GenSigSendType" SG_ 967 MO_OBD2_Lampe 0;
BA_ "GenSigSwitchedByIgnition" SG_ 967 MO_Heissleuchte 0;
BA_ "GenSigSendType" SG_ 967 MO_Heissleuchte 0;
BA_ "GenSigSwitchedByIgnition" SG_ 967 MO_Partikel_Lampe 0;
BA_ "GenSigSendType" SG_ 967 MO_Partikel_Lampe 0;
BA_ "GenSigSwitchedByIgnition" SG_ 967 MO_RedFahrleistung_Lampe 0;
BA_ "GenSigSendType" SG_ 967 MO_RedFahrleistung_Lampe 0;
BA_ "GenSigSwitchedByIgnition" SG_ 967 WIV_Oelstand_nicht_vorhanden 0;
BA_ "GenSigSendType" SG_ 967 WIV_Oelstand_nicht_vorhanden 0;
BA_ "GenSigSwitchedByIgnition" SG_ 967 WIV_nachfuellanzeige_ein 0;
BA_ "GenSigSendType" SG_ 967 WIV_nachfuellanzeige_ein 0;
BA_ "GenSigSwitchedByIgnition" SG_ 967 WIV_Ueberfuell_deaktiv 0;
BA_ "GenSigSendType" SG_ 967 WIV_Ueberfuell_deaktiv 0;
BA_ "GenSigSwitchedByIgnition" SG_ 967 WIV_Unterfuell_Warn 0;
BA_ "GenSigSendType" SG_ 967 WIV_Unterfuell_Warn 0;
BA_ "GenSigSwitchedByIgnition" SG_ 967 MO_Tankdeckel_Lampe 0;
BA_ "GenSigSendType" SG_ 967 MO_Tankdeckel_Lampe 0;
BA_ "GenSigSwitchedByIgnition" SG_ 967 MO_Text_Tankdeckelwarn 0;
BA_ "GenSigSendType" SG_ 967 MO_Text_Tankdeckelwarn 0;
BA_ "GenSigSwitchedByIgnition" SG_ 967 MO_Vorglueh_Lampe 0;
BA_ "GenSigSendType" SG_ 967 MO_Vorglueh_Lampe 0;
BA_ "GenSigSwitchedByIgnition" SG_ 967 WIV_Oeldr_Warn_Motor 0;
BA_ "GenSigSendType" SG_ 967 WIV_Oeldr_Warn_Motor 0;
BA_ "GenSigSwitchedByIgnition" SG_ 967 MO_E_Mode 0;
BA_ "GenSigSendType" SG_ 967 MO_E_Mode 0;
BA_ "GenSigSwitchedByIgnition" SG_ 966 SOK_Motor_26_Signatur 0;
BA_ "GenSigFuncType" SG_ 966 SOK_Motor_26_Signatur 15;
BA_ "GenSigSendType" SG_ 966 SOK_Motor_26_Signatur 0;
BA_ "Fehlerwert" SG_ 706 MO_Powermeter_Dauer_Grenze 4095;
BA_ "GenSigSwitchedByIgnition" SG_ 706 MO_Powermeter_Dauer_Grenze 0;
BA_ "GenSigStartValue" SG_ 706 MO_Powermeter_Dauer_Grenze 4094;
BA_ "GenSigSendType" SG_ 706 MO_Powermeter_Dauer_Grenze 3;
BA_ "GenSigSwitchedByIgnition" SG_ 706 MO_Anzeige_StSt_Text 0;
BA_ "GenSigSendType" SG_ 706 MO_Anzeige_StSt_Text 3;
BA_ "GenSigSwitchedByIgnition" SG_ 706 MO_Anzeige_StSt_Symbol 0;
BA_ "GenSigSendType" SG_ 706 MO_Anzeige_StSt_Symbol 3;
BA_ "GenSigSwitchedByIgnition" SG_ 706 MO_ADR_Status 0;
BA_ "GenSigSendType" SG_ 706 MO_ADR_Status 3;
BA_ "GenSigSwitchedByIgnition" SG_ 706 MO_AGA_Sound_Texte 0;
BA_ "GenSigSendType" SG_ 706 MO_AGA_Sound_Texte 3;
BA_ "GenSigSwitchedByIgnition" SG_ 706 MO_Anzeige_FMAus_Text 0;
BA_ "GenSigSendType" SG_ 706 MO_Anzeige_FMAus_Text 3;
BA_ "GenSigSwitchedByIgnition" SG_ 706 PEA_Texte 0;
BA_ "GenSigSendType" SG_ 706 PEA_Texte 3;
BA_ "GenSigSwitchedByIgnition" SG_ 706 TSK_Ueberstimmt_vMax_FahrerInfo 0;
BA_ "GenSigSendType" SG_ 706 TSK_Ueberstimmt_vMax_FahrerInfo 3;
BA_ "GenSigSwitchedByIgnition" SG_ 706 MO_Rekuperationsstufe 0;
BA_ "GenSigStartValue" SG_ 706 MO_Rekuperationsstufe 7;
BA_ "GenSigSendType" SG_ 706 MO_Rekuperationsstufe 3;
BA_ "GenSigSwitchedByIgnition" SG_ 706 TSK_Einheit_vMax_FahrerInfo 0;
BA_ "GenSigSendType" SG_ 706 TSK_Einheit_vMax_FahrerInfo 0;
BA_ "GenSigSwitchedByIgnition" SG_ 706 TSK_Status_vMax_FahrerInfo 0;
BA_ "GenSigSendType" SG_ 706 TSK_Status_vMax_FahrerInfo 0;
BA_ "GenSigSwitchedByIgnition" SG_ 706 MO_Anz_Kuehlerluefter 0;
BA_ "GenSigSendType" SG_ 706 MO_Anz_Kuehlerluefter 0;
BA_ "GenSigSwitchedByIgnition" SG_ 706 FDR_Warnung_ALR 0;
BA_ "GenSigSendType" SG_ 706 FDR_Warnung_ALR 3;
BA_ "GenSigSwitchedByIgnition" SG_ 706 MO_EM_Ueberhitzungswarnung 0;
BA_ "GenSigSendType" SG_ 706 MO_EM_Ueberhitzungswarnung 3;
BA_ "GenSigSwitchedByIgnition" SG_ 706 MO_ElAntrieb_Abschleppwarnung 0;
BA_ "GenSigSendType" SG_ 706 MO_ElAntrieb_Abschleppwarnung 3;
BA_ "GenSigSwitchedByIgnition" SG_ 706 TSK_vMax_FahrerInfo 0;
BA_ "GenSigSendType" SG_ 706 TSK_vMax_FahrerInfo 0;
BA_ "GenSigSwitchedByIgnition" SG_ 267 Motor_51_CRC 0;
BA_ "GenSigFuncType" SG_ 267 Motor_51_CRC 2;
BA_ "GenSigSendType" SG_ 267 Motor_51_CRC 0;
BA_ "GenSigSwitchedByIgnition" SG_ 267 Motor_51_BZ 0;
BA_ "GenSigFuncType" SG_ 267 Motor_51_BZ 1;
BA_ "GenSigSendType" SG_ 267 Motor_51_BZ 0;
BA_ "Fehlerwert" SG_ 267 MO_Fahrpedalrohwert_01 255;
BA_ "GenSigSwitchedByIgnition" SG_ 267 MO_Fahrpedalrohwert_01 0;
BA_ "GenSigSendType" SG_ 267 MO_Fahrpedalrohwert_01 0;
BA_ "GenSigSwitchedByIgnition" SG_ 267 MO_QBit_Fahrpedalwerte_01 0;
BA_ "GenSigStartValue" SG_ 267 MO_QBit_Fahrpedalwerte_01 1;
BA_ "GenSigSendType" SG_ 267 MO_QBit_Fahrpedalwerte_01 0;
BA_ "Fehlerwert" SG_ 267 MO_Fahrpedalgradient 255;
BA_ "GenSigSwitchedByIgnition" SG_ 267 MO_Fahrpedalgradient 0;
BA_ "GenSigSendType" SG_ 267 MO_Fahrpedalgradient 0;
BA_ "GenSigSwitchedByIgnition" SG_ 267 MO_Sig_Fahrpedalgradient 0;
BA_ "GenSigSendType" SG_ 267 MO_Sig_Fahrpedalgradient 0;
BA_ "Fehlerwert" SG_ 267 MO_rel_Saugrohrdruck 63;
BA_ "GenSigSwitchedByIgnition" SG_ 267 MO_rel_Saugrohrdruck 0;
BA_ "GenSigSendType" SG_ 267 MO_rel_Saugrohrdruck 0;
BA_ "GenSigSwitchedByIgnition" SG_ 267 MO_rel_Saugrohrdruck_gem_err 0;
BA_ "GenSigSendType" SG_ 267 MO_rel_Saugrohrdruck_gem_err 0;
BA_ "GenSigSwitchedByIgnition" SG_ 267 MO_Moment_im_Leerlauf 0;
BA_ "GenSigSendType" SG_ 267 MO_Moment_im_Leerlauf 0;
BA_ "GenSigSwitchedByIgnition" SG_ 267 MO_Schubabschaltung 0;
BA_ "GenSigSendType" SG_ 267 MO_Schubabschaltung 0;
BA_ "GenSigSwitchedByIgnition" SG_ 267 MO_StartStopp_StoppVorbereitung 0;
BA_ "GenSigSendType" SG_ 267 MO_StartStopp_StoppVorbereitung 0;
BA_ "GenSigSwitchedByIgnition" SG_ 267 MO_Solldrehz_Leerlauf 0;
BA_ "GenSigSendType" SG_ 267 MO_Solldrehz_Leerlauf 0;
BA_ "GenSigSwitchedByIgnition" SG_ 267 MO_Entkopplung_Sollschlupf 0;
BA_ "GenSigStartValue" SG_ 267 MO_Entkopplung_Sollschlupf 126;
BA_ "GenSigSendType" SG_ 267 MO_Entkopplung_Sollschlupf 0;
BA_ "GenSigSwitchedByIgnition" SG_ 267 MO_temporaere_Fahrerabwesenheit 0;
BA_ "GenSigSendType" SG_ 267 MO_temporaere_Fahrerabwesenheit 0;
BA_ "GenSigSwitchedByIgnition" SG_ 267 TSK_a_Soll_gradientenbegrenzt 0;
BA_ "GenSigStartValue" SG_ 267 TSK_a_Soll_gradientenbegrenzt 127;
BA_ "GenSigSendType" SG_ 267 TSK_a_Soll_gradientenbegrenzt 0;
BA_ "GenSigSwitchedByIgnition" SG_ 267 TSK_Radbremsmom 0;
BA_ "GenSigSendType" SG_ 267 TSK_Radbremsmom 0;
BA_ "GenSigSwitchedByIgnition" SG_ 267 TSK_Status 0;
BA_ "GenSigStartValue" SG_ 267 TSK_Status 1;
BA_ "GenSigSendType" SG_ 267 TSK_Status 0;
BA_ "GenSigSwitchedByIgnition" SG_ 267 TSK_v_Begrenzung_aktiv 0;
BA_ "GenSigSendType" SG_ 267 TSK_v_Begrenzung_aktiv 0;
BA_ "GenSigSwitchedByIgnition" SG_ 267 TSK_Standby_Anf_ESP 0;
BA_ "GenSigSendType" SG_ 267 TSK_Standby_Anf_ESP 0;
BA_ "GenSigSwitchedByIgnition" SG_ 267 TSK_Freig_Verzoeg_Anf 0;
BA_ "GenSigSendType" SG_ 267 TSK_Freig_Verzoeg_Anf 0;
BA_ "GenSigSwitchedByIgnition" SG_ 267 TSK_Limiter_ausgewaehlt 0;
BA_ "GenSigSendType" SG_ 267 TSK_Limiter_ausgewaehlt 0;
BA_ "Fehlerwert" SG_ 267 TSK_Hauptschalter_GRA_ACC 3;
BA_ "GenSigSwitchedByIgnition" SG_ 267 TSK_Hauptschalter_GRA_ACC 0;
BA_ "GenSigSendType" SG_ 267 TSK_Hauptschalter_GRA_ACC 0;
BA_ "GenSigSwitchedByIgnition" SG_ 267 TSK_SRBM_Anf_ASIL 0;
BA_ "GenSigSendType" SG_ 267 TSK_SRBM_Anf_ASIL 0;
BA_ "GenSigSwitchedByIgnition" SG_ 267 TSK_ax_Getriebe_02 0;
BA_ "GenSigStartValue" SG_ 267 TSK_ax_Getriebe_02 511;
BA_ "GenSigSendType" SG_ 267 TSK_ax_Getriebe_02 0;
BA_ "GenSigSwitchedByIgnition" SG_ 267 TSK_Zwangszusch_ESP 0;
BA_ "GenSigSendType" SG_ 267 TSK_Zwangszusch_ESP 0;
BA_ "GenSigSwitchedByIgnition" SG_ 267 TSK_zul_Regelabw 0;
BA_ "GenSigSendType" SG_ 267 TSK_zul_Regelabw 0;
BA_ "Fehlerwert" SG_ 267 TSK_Radsollmoment 65535;
BA_ "GenSigSwitchedByIgnition" SG_ 267 TSK_Radsollmoment 0;
BA_ "GenSigStartValue" SG_ 267 TSK_Radsollmoment 65534;
BA_ "GenSigSendType" SG_ 267 TSK_Radsollmoment 0;
BA_ "GenSigSwitchedByIgnition" SG_ 267 TSK_Kategorie_Verzoegerungsfkt 0;
BA_ "GenSigSendType" SG_ 267 TSK_Kategorie_Verzoegerungsfkt 0;
BA_ "GenSigSwitchedByIgnition" SG_ 267 TSK_Notstopp_Anf 0;
BA_ "GenSigSendType" SG_ 267 TSK_Notstopp_Anf 0;
BA_ "GenSigSwitchedByIgnition" SG_ 267 MO_Status_MinDrzEingriff 0;
BA_ "GenSigSendType" SG_ 267 MO_Status_MinDrzEingriff 0;
BA_ "GenSigSwitchedByIgnition" SG_ 267 MO_Status_MaxDrzEingriff 0;
BA_ "GenSigSendType" SG_ 267 MO_Status_MaxDrzEingriff 0;
BA_ "GenSigSwitchedByIgnition" SG_ 267 MO_Status_MinDrzEingriff_sek 0;
BA_ "GenSigSendType" SG_ 267 MO_Status_MinDrzEingriff_sek 0;
BA_ "GenSigSwitchedByIgnition" SG_ 267 MO_Status_MaxDrzEingriff_sek 0;
BA_ "GenSigSendType" SG_ 267 MO_Status_MaxDrzEingriff_sek 0;
BA_ "Fehlerwert" SG_ 267 TSK_SRBM_max_Gradient 127;
BA_ "GenSigSwitchedByIgnition" SG_ 267 TSK_SRBM_max_Gradient 0;
BA_ "GenSigStartValue" SG_ 267 TSK_SRBM_max_Gradient 126;
BA_ "GenSigSendType" SG_ 267 TSK_SRBM_max_Gradient 0;
BA_ "GenSigFuncType" SG_ 267 SOK_Motor_51_Signatur 15;
BA_ "GenSigSendType" SG_ 267 SOK_Motor_51_Signatur 0;
BA_ "GenSigSwitchedByIgnition" SG_ 330 Motor_52_CRC 0;
BA_ "GenSigFuncType" SG_ 330 Motor_52_CRC 2;
BA_ "GenSigSwitchedByIgnition" SG_ 330 Motor_52_BZ 0;
BA_ "GenSigFuncType" SG_ 330 Motor_52_BZ 1;
BA_ "Fehlerwert" SG_ 330 MO_Hochschaltdrehz 4095;
BA_ "GenSigSwitchedByIgnition" SG_ 330 MO_Hochschaltdrehz 0;
BA_ "GenSigSendType" SG_ 330 MO_Hochschaltdrehz 0;
BA_ "GenSigSwitchedByIgnition" SG_ 330 MO_Anzeige_Verbr_Einheit 0;
BA_ "GenSigSendType" SG_ 330 MO_Anzeige_Verbr_Einheit 0;
BA_ "Fehlerwert" SG_ 330 MO_Schaltblitz_Anz 127;
BA_ "GenSigSwitchedByIgnition" SG_ 330 MO_Schaltblitz_Anz 0;
BA_ "GenSigStartValue" SG_ 330 MO_Schaltblitz_Anz 126;
BA_ "GenSigSendType" SG_ 330 MO_Schaltblitz_Anz 0;
BA_ "Fehlerwert" SG_ 330 MO_Anzeige_Drehmoment 2047;
BA_ "GenSigSwitchedByIgnition" SG_ 330 MO_Anzeige_Drehmoment 0;
BA_ "GenSigSendType" SG_ 330 MO_Anzeige_Drehmoment 0;
BA_ "Fehlerwert" SG_ 330 MO_Anzeige_Leistung 2047;
BA_ "GenSigSwitchedByIgnition" SG_ 330 MO_Anzeige_Leistung 0;
BA_ "GenSigSendType" SG_ 330 MO_Anzeige_Leistung 0;
BA_ "Fehlerwert" SG_ 330 MO_rel_Ladedruck 255;
BA_ "GenSigSwitchedByIgnition" SG_ 330 MO_rel_Ladedruck 0;
BA_ "GenSigSendType" SG_ 330 MO_rel_Ladedruck 0;
BA_ "GenSigSwitchedByIgnition" SG_ 330 MO_Istgang 0;
BA_ "GenSigSendType" SG_ 330 MO_Istgang 0;
BA_ "GenSigSwitchedByIgnition" SG_ 330 MO_Sollgang 0;
BA_ "GenSigSendType" SG_ 330 MO_Sollgang 0;
BA_ "Fehlerwert" SG_ 330 MO_Oeldruck 255;
BA_ "GenSigSwitchedByIgnition" SG_ 330 MO_Oeldruck 0;
BA_ "GenSigStartValue" SG_ 330 MO_Oeldruck 254;
BA_ "GenSigSendType" SG_ 330 MO_Oeldruck 0;
BA_ "GenSigSwitchedByIgnition" SG_ 330 MO_Anzeigedrehz 0;
BA_ "GenSigSendType" SG_ 330 MO_Anzeigedrehz 0;
BA_ "GenSigSwitchedByIgnition" SG_ 330 MO_Effizienzmodus 0;
BA_ "GenSigSendType" SG_ 330 MO_Effizienzmodus 0;
BA_ "Fehlerwert" SG_ 330 MO_Fehler_Oeldrucksensor 1;
BA_ "GenSigSwitchedByIgnition" SG_ 330 MO_Fehler_Oeldrucksensor 0;
BA_ "GenSigSendType" SG_ 330 MO_Fehler_Oeldrucksensor 0;
BA_ "GenSigSwitchedByIgnition" SG_ 330 MO_Schaltempf_verfbar 0;
BA_ "GenSigSendType" SG_ 330 MO_Schaltempf_verfbar 0;
BA_ "Fehlerwert" SG_ 330 MO_Ladedruck 511;
BA_ "GenSigSwitchedByIgnition" SG_ 330 MO_Ladedruck 0;
BA_ "GenSigSendType" SG_ 330 MO_Ladedruck 0;
BA_ "GenSigSwitchedByIgnition" SG_ 330 MO_KVS 0;
BA_ "GenSigSendType" SG_ 330 MO_KVS 0;
BA_ "GenSigSwitchedByIgnition" SG_ 330 MO_KVS_Ueberlauf 0;
BA_ "GenSigSendType" SG_ 330 MO_KVS_Ueberlauf 0;
BA_ "GenSigSwitchedByIgnition" SG_ 330 MO_ePowermeter 0;
BA_ "GenSigSendType" SG_ 330 MO_ePowermeter 0;
BA_ "Fehlerwert" SG_ 330 MO_ePerformance 255;
BA_ "GenSigSwitchedByIgnition" SG_ 330 MO_ePerformance 0;
BA_ "GenSigSendType" SG_ 330 MO_ePerformance 0;
BA_ "GenSigSwitchedByIgnition" SG_ 330 MO_Zust_Antrieb 0;
BA_ "GenSigSendType" SG_ 330 MO_Zust_Antrieb 0;
BA_ "GenSigSwitchedByIgnition" SG_ 330 MO_Zust_Betriebsstrategie 0;
BA_ "GenSigSendType" SG_ 330 MO_Zust_Betriebsstrategie 0;
BA_ "Fehlerwert" SG_ 330 Ladezustand_02 255;
BA_ "GenSigSwitchedByIgnition" SG_ 330 Ladezustand_02 0;
BA_ "GenSigStartValue" SG_ 330 Ladezustand_02 254;
BA_ "GenSigSendType" SG_ 330 Ladezustand_02 0;
BA_ "GenSigSwitchedByIgnition" SG_ 330 Ladezustand_gering 0;
BA_ "GenSigSendType" SG_ 330 Ladezustand_gering 0;
BA_ "GenSigSwitchedByIgnition" SG_ 330 MO_Powermeter_Elm_02 0;
BA_ "GenSigStartValue" SG_ 330 MO_Powermeter_Elm_02 4094;
BA_ "GenSigSendType" SG_ 330 MO_Powermeter_Elm_02 0;
BA_ "GenSigSwitchedByIgnition" SG_ 330 MO_Powermeter 0;
BA_ "GenSigStartValue" SG_ 330 MO_Powermeter 4093;
BA_ "GenSigSendType" SG_ 330 MO_Powermeter 0;
BA_ "GenSigSwitchedByIgnition" SG_ 330 MO_OnePedalDriving_Warnung 0;
BA_REL_ "GenSigTimeoutTime" BU_SG_REL_ Kombi SG_ 1153 ZR_LoGeWa_Event_Kombiwarnung 5000;
BA_REL_ "GenSigTimeoutTime" BU_SG_REL_ Kombi SG_ 1153 Nav_FoD_Status 5000;
BA_REL_ "GenSigTimeoutTime" BU_SG_REL_ ICAS1_X_Gateway SG_ 1153 ZR_Lichter_Tag 5000;
BA_REL_ "GenSigTimeoutTime" BU_SG_REL_ ICAS1_X_Gateway SG_ 1153 INF_Nachlaufzeit 5000;
BA_REL_ "GenSigTimeoutTime" BU_SG_REL_ Kombi SG_ 1639 BFS_MMB_storage_beep 1000;
BA_REL_ "GenSigTimeoutTime" BU_SG_REL_ Kombi SG_ 1178 FS_MMB_storage_beep 1000;
BA_REL_ "GenSigTimeoutTime" BU_SG_REL_ SmartLight_01 SG_ 1171 MF_Innenraumbel_Unterdrueck 2000;
BA_REL_ "GenSigTimeoutTime" BU_SG_REL_ Kombi SG_ 1171 MF_Summer 2000;
BA_REL_ "GenSigTimeoutTime" BU_SG_REL_ ICAS3_Gateway SG_ 1164 MF_Radiomute 2000;
BA_REL_ "GenSigTimeoutTime" BU_SG_REL_ Kombi SG_ 817 MFL_Paddle_Verbau 5000;
BA_REL_ "GenSigTimeoutTime" BU_SG_REL_ ICAS3_Gateway SG_ 560 MFL_Beruehrungserkennung 1000;
BA_REL_ "GenSigTimeoutTime" BU_SG_REL_ ICAS3_Gateway SG_ 560 MFL_Touch_Event 1000;
BA_REL_ "GenSigTimeoutTime" BU_SG_REL_ ICAS3_Gateway SG_ 958 MO_HYB_Fahrbereitschaft 1000;
BA_REL_ "GenSigTimeoutTime" BU_SG_REL_ Kombi SG_ 958 MO_HYB_Fahrbereitschaft 1000;
BA_REL_ "GenSigTimeoutTime" BU_SG_REL_ ZR_MIB_TOP_ab_Gen3 SG_ 958 MO_Fahrer_bremst 1000;
BA_REL_ "GenSigTimeoutTime" BU_SG_REL_ ZR_MIB_TOP_ab_Gen3 SG_ 958 MO_QBit_Fahrer_bremst 1000;
BA_REL_ "GenSigTimeoutTime" BU_SG_REL_ ZR_MIB_TOP_ab_Gen3 SG_ 958 MO_Kickdown 1000;
BA_REL_ "GenSigTimeoutTime" BU_SG_REL_ Fahrerdisplay_Kombi SG_ 1648 MO_EPCL 5000;
BA_REL_ "GenSigTimeoutTime" BU_SG_REL_ Kombi SG_ 1648 MO_EPCL 5000;
BA_REL_ "GenSigTimeoutTime" BU_SG_REL_ Fahrerdisplay_Kombi SG_ 1648 MO_Fahrzeugtyp 5000;
BA_REL_ "GenSigTimeoutTime" BU_SG_REL_ Kombi SG_ 1648 MO_Fahrzeugtyp 5000;
BA_REL_ "GenSigTimeoutTime" BU_SG_REL_ Fahrerdisplay_Kombi SG_ 967 MO_OBD2_Lampe 1000;
BA_REL_ "GenSigTimeoutTime" BU_SG_REL_ Kombi SG_ 967 MO_OBD2_Lampe 1000;
BA_REL_ "GenSigTimeoutTime" BU_SG_REL_ Kombi SG_ 967 MO_RedFahrleistung_Lampe 1000;
BA_REL_ "GenSigTimeoutTime" BU_SG_REL_ Kombi SG_ 706 MO_Rekuperationsstufe 5000;
BA_REL_ "GenSigTimeoutTime" BU_SG_REL_ Kombi SG_ 706 FDR_Warnung_ALR 5000;
BA_REL_ "GenSigTimeoutTime" BU_SG_REL_ Kombi SG_ 706 MO_EM_Ueberhitzungswarnung 5000;
BA_REL_ "GenSigTimeoutTime" BU_SG_REL_ Kombi SG_ 706 MO_ElAntrieb_Abschleppwarnung 5000;
BA_REL_ "GenSigTimeoutTime" BU_SG_REL_ ZR_MIB_TOP_ab_Gen3 SG_ 267 MO_Fahrpedalrohwert_01 500;
BA_REL_ "GenSigTimeoutTime" BU_SG_REL_ Kombi SG_ 267 TSK_Hauptschalter_GRA_ACC 500;
BA_REL_ "GenSigTimeoutTime" BU_SG_REL_ Kombi SG_ 330 Motor_52_CRC 500;
BA_REL_ "GenSigTimeoutTime" BU_SG_REL_ Kombi SG_ 330 Motor_52_BZ 500;
BA_REL_ "GenSigTimeoutTime" BU_SG_REL_ Kombi SG_ 330 MO_ePerformance 500;
BA_REL_ "GenSigTimeoutTime" BU_SG_REL_ Kombi SG_ 330 Ladezustand_02 500;
BA_REL_ "GenSigTimeoutTime" BU_SG_REL_ ZR_MIB_TOP_ab_Gen3 SG_ 330 Ladezustand_02 500;
BA_REL_ "GenSigTimeoutTime" BU_SG_REL_ Kombi SG_ 330 Ladezustand_gering 500;
BA_REL_ "GenSigTimeoutTime" BU_SG_REL_ Kombi SG_ 330 MO_Powermeter 500;
BA_REL_ "GenSigTimeoutTime" BU_SG_REL_ Fahrerdisplay_Kombi SG_ 330 MO_OnePedalDriving_Warnung 500;
BA_REL_ "GenSigTimeoutTime" BU_SG_REL_ Kombi SG_ 330 MO_OnePedalDriving_Warnung 500;
VAL_ 1153 ZR_LoGeWa_Event_Kombiwarnung 0 "Init" 1 "Unfall" 2 "Traktionsverlust" 3 "Panne" 4 "Sichtbehinderung" 5 "Aquaplaning" 6 "EEBL" 7 "SEF_stat" 8 "SEF_dyn_allgemein" 9 "SEF_dyn_vorne" 10 "SEF_dyn_hinten" 11 "SEF_dyn_links" 12 "SEF_dyn_rechts" 13 "Stauende" ;
VAL_ 1153 Nav_FoD_Status 0 "Init" 1 "Nav_permanently_available" 2 "FoD_Nav_not_activated" 3 "FoD_Nav_activated" 4 "R4N_Nav_not_activated" ;
VAL_ 1153 MIB_ASW_Diagnose 0 "ASW_Warnton_nicht_verfuegbar" 1 "ASW_Warnton_verfuegbar" ;
VAL_ 1153 ZR_Lichter_Tag 0 "Nacht" 1 "Tag" ;
VAL_ 1153 MIB_Tongenerator_PH_verfuegbar 0 "Tongenerator_nicht_verfuegbar" 1 "Tongenerator_vorne_verfuegbar" 2 "Tongenerator_hinten_verfuegbar" 3 "Tongenerator_gesamt_verfuegbar" 4 "Tongenerator_im_AMP" ;
VAL_ 1153 DSSS_Warning 0 "No_Warning" 1 "Red_traffic_light_guidance" 2 "Stop_sign_warning" 3 "Rear_end_collision_avoidance_warning" 4 "Intersection_collision_avoidance_warning_right" 5 "Intersection_collision_avoidance_warning_left" 6 "turn_right_collision_avoidance" 7 "turn_left_collision_avoidance" 8 "pedestrian_crossing_right" 9 "pedestrian_crossing_left" 10 "bicycle_collision_right" 11 "bicycle_collision_left" ;
VAL_ 1153 ZR_Kindersicherung_RSE 0 "inaktiv" 1 "aktiv" ;
VAL_ 1153 ZR_RSE_aktivieren 0 "inaktiv" 1 "aktiv" ;
VAL_ 1153 MMI_SDS_aktiv 0 "inaktiv" 1 "aktiv" ;
VAL_ 1153 MU_SecondDisplay 0 "Init" 1 "gueltige_Karte" 2 "ungueltiges_Signal" 3 "Nicht_Verbaut" ;
VAL_ 1153 MMI_Telefon_aktiv 0 "Telefongespraech_nicht_aktiv" 1 "Telefongespraech_aktiv" ;
VAL_ 1153 MMI_Gurt_Mic_ref 0 "Downlink_inaktiv" 1 "Downlink_aktiv" ;
VAL_ 1153 ZR_AppConnect_Zustand 0 "AppConnect_nicht_in_Anzeige" 1 "AppConnect_in_Anzeige" ;
VAL_ 1153 HMI_WLC1_Systemzustand_intern 0 "Wireless_Charger_off" 1 "Wireless_Charger_on" 2 "Wireless_Charger_init" ;
VAL_ 1153 HMI_WLC2_Systemzustand_intern 0 "Wireless_Charger_off" 1 "Wireless_Charger_on" 2 "Wireless_Charger_init" ;
VAL_ 1153 ZR_Parken_Sondermodus 0 "Init" 1 "Sondermodus_aktiv" 2 "Sondermodus_nicht_verfuegbar" 3 "WLAN_aus" 4 "WLAN_auscodiert" 15 "keine_WLAN_HW" ;
VAL_ 1153 INF_Nachlaufzeit 510 "INIT" 511 "Fehler" ;
VAL_ 1639 BFS_Fond_Bed_Ack 0 "nicht aktiviert" 1 "aktiviert" ;
VAL_ 1639 BFS_Lehne_nicht_verriegelt 0 "keine Anzeige" 1 "Lehne_nicht_verriegelt" ;
VAL_ 1639 BFS_Klapptisch_offen 0 "inaktiv" 1 "aktiv" ;
VAL_ 1639 BFS_Gurtbringer_Sperre 0 "Gurtzubringer_freigegeben" 1 "Gurtzubringer_gesperrt" ;
VAL_ 1639 BFS_Sitzsym_Fahrt_aktiv 0 "inaktiv" 1 "aktiv" ;
VAL_ 1639 BFS_Sitzfahrt_aktiv 0 "Init" 1 "Sitz in Bewegung" ;
VAL_ 1639 BFS_SLV_aktiv 0 "nicht_aktiv" 1 "Sitzlaengsverstellung aktiv" ;
VAL_ 1639 BFS_SHV_aktiv 0 "nicht_aktiv" 1 "Sitzhoehenverstellung aktiv" ;
VAL_ 1639 BFS_LNV_aktiv 0 "inaktiv" 1 "aktiv" ;
VAL_ 1639 BFS_SNV_aktiv 0 "nicht_aktiv" 1 "Sitzneigungsverstellung aktiv" ;
VAL_ 1639 BFS_KSV_aktiv 0 "nicht_aktiv" 1 "Kopfstuetzenverstellung aktiv" ;
VAL_ 1639 BFS_LKV_aktiv 0 "nicht_aktiv" 1 "aktiv" ;
VAL_ 1639 BFS_STV_aktiv 0 "inaktiv" 1 "Sitztiefeverstellung aktiv" ;
VAL_ 1639 BFS_LHV_aktiv 0 "inaktiv" 1 "aktiv" ;
VAL_ 1639 BFS_LWV_aktiv 0 "nicht_aktiv" 1 "aktiv" ;
VAL_ 1639 BFS_GHV_aktiv 0 "nicht_aktiv" 1 "Gurthoehe Verstellung aktiv" ;
VAL_ 1639 BFS_KSS_Fahrt_aktiv 0 "nicht_aktiv" 1 "Komfortseitensichtfahrt aktiv" ;
VAL_ 1639 BFS_MMB_lokal_Stop 0 "kein_Abbruch" 1 "lokaler_Abbruch" ;
VAL_ 1639 BFS_Ruhestellung_Status 0 "inakiv" 1 "Ruhestellung_aktiv" ;
VAL_ 1639 BFS_Seat_Locked 0 "nicht_gesperrt" 1 "gesperrt" ;
VAL_ 1639 BFS_MMB_storage 0 "keine Zuweisung" 1 "P1/FP1 Pos Zuweisung" 2 "P2/FP2 Pos Zuweisung" 3 "P3/FP3 Pos Zuweisung" 4 "P4/FP4 Pos Zuweisung an den im System aktiven Funkschlüssel/FPI ID über MMI" 5 "FS1" 6 "FS2" 7 "FS3" 8 "FS4" ;
VAL_ 1639 BFS_MMB_tipp 0 "kein_Tippbetrieb" 1 "Tippbetrieb" ;
VAL_ 1639 BFS_MMB_tast 0 "kein_Tastbetrieb" 1 "Tastbetrieb" ;
VAL_ 1639 BFS_MMB_store_LED_on 0 "LED_aus" 1 "LED_ein" ;
VAL_ 1639 BFS_MMB_storage_beep 0 "beep_aus" 1 "beep ein" ;
VAL_ 1639 BFS_MMB_store 0 "nicht speichern" 1 "speichern" ;
VAL_ 1639 BFS_MMB_glob_stop 0 "kein globaler Abbruch" 1 "globaler Abbruch" ;
VAL_ 1639 BFS_FSV_ausgeklappt 0 "FSV_nicht_ausgeklappt" 1 "FSV_ausgeklappt" ;
VAL_ 1178 FS_Fond_Bed_enable 0 "disable" 1 "enable" ;
VAL_ 1178 FS_Lehne_nicht_verriegelt 0 "keine Anzeige" 1 "Lehne_nicht_verriegelt" ;
VAL_ 1178 FS_Spezialposition_anfahren 0 "Fkt_inaktiv" 1 "Fkt_aktiv" ;
VAL_ 1178 FS_Gurtbringer_Sperre 0 "Gurtzubringer_freigegeben" 1 "Gurtzubringer_gesperrt" ;
VAL_ 1178 FS_BFS_Sitzsym_Anfahrt 0 "keine Sitzsymetrie Anfahrt BFS" 1 "Sitzsymetrie Anfahrt BFS" ;
VAL_ 1178 FS_Sitzfahrt_aktiv 0 "Sitz_nicht_in_Bewegung" 1 "Sitz_in_Bewegung" ;
VAL_ 1178 FS_SLV_aktiv 0 "nicht_aktiv" 1 "Sitzlaengsverstellung aktiv" ;
VAL_ 1178 FS_SHV_aktiv 0 "nicht_aktiv" 1 "Sitzhoehenverstellung aktiv" ;
VAL_ 1178 FS_LNV_aktiv 0 "nicht_aktiv" 1 "Lehnenneigungverstellung aktiv" ;
VAL_ 1178 FS_SNV_aktiv 0 "nicht_aktiv" 1 "Sitzneigungsverstellung_aktiv" ;
VAL_ 1178 FS_KSV_aktiv 0 "nicht_aktiv" 1 "Kopfstuetzenverstellung aktiv" ;
VAL_ 1178 FS_LKV_aktiv 0 "nicht_aktiv" 1 "Lehnenkopfverstellung aktiv" ;
VAL_ 1178 FS_STV_aktiv 0 "nicht_aktiv" 1 "Sitztiefeverstellung aktiv" ;
VAL_ 1178 FS_LHV_aktiv 0 "nicht_aktiv" 1 "Lordose Höhe Verstellung aktiv" ;
VAL_ 1178 FS_LWV_aktiv 0 "nicht_aktiv" 1 "Lordose W Verstellung aktiv" ;
VAL_ 1178 FS_GHV_aktiv 0 "nicht_aktiv" 1 "Gurthoehenverstellung aktiv" ;
VAL_ 1178 FS_BFS_KSS_Anfahrt 0 "keine Anfahrt KSS BFS" 1 "Anfahrt KSS BFS" ;
VAL_ 1178 FS_MMB_lokal_Stop 0 "kein_Abbruch" 1 "lokaler_Abbruch" ;
VAL_ 1178 FS_MMB_storage 0 "keine_Zuweisung" 1 "P1_FP1_Pos_Zuweisung" 2 "P2_FP2_Pos_Zuweisung" 3 "P3_FP3_Pos_Zuweisung" 4 "P4_FP4_Pos_Zuweisung" 5 "FS1_bzw_Benutzerkonto_1" 6 "FS2_bzw_Benutzerkonto_2" 7 "FS3_bzw_Benutzerkonto_3" 8 "FS4_bzw_Benutzerkonto_4" 9 "FS5_bzw_Benutzerkonto_5" 10 "FS6_bzw_Benutzerkonto_6" 11 "FS7_bzw_Benutzerkonto_7" ;
VAL_ 1178 FS_MMB_tipp 0 "kein_Tippbetrieb" 1 "Tippbetrieb__automatisches_Funks" ;
VAL_ 1178 FS_MMB_tast 0 "kein_Tastbetrieb" 1 "Tastbetrieb__Fingerprintautomati" ;
VAL_ 1178 FS_MMB_store_LED_on 0 "LED_aus" 1 "LED_ein" ;
VAL_ 1178 FS_MMB_storage_beep 0 "beep aus" 1 "beep ein" ;
VAL_ 1178 FS_MMB_store 0 "nicht_speichern__kein_keyless_ve" 1 "abspeichern__keyless_verbaut" ;
VAL_ 1178 FS_MMB_glob_stop 0 "kein_globaler_Abbrucht" 1 "globaler_Abbruch" ;
VAL_ 1178 FS_EE_Fond_FS_enable 0 "EE Fond links deaktiv" 1 "EE Fond links aktiv (default) vom MMI" ;
VAL_ 1178 FS_EE_Fond_BFS_enable 0 "EE Fond rechts deaktiv" 1 "EE Fond rechts aktiv (default) vom MMI" ;
VAL_ 1178 FS_EE_BFS_enable 0 "keine_EE_Freigabe" 1 "EE_Freigabe" ;
VAL_ 1171 MF_ZV_Lock 0 "Locktaster_nicht_betaetigt" 1 "Locktaster_betaetigt" ;
VAL_ 1171 MF_Motorweiterlauf 0 "inaktiv" 1 "aktiv" ;
VAL_ 1171 MF_Abzugssperre 0 "inaktiv" 1 "aktiv" ;
VAL_ 1171 MF_Anlassersperre 0 "inaktiv" 1 "aktiv" ;
VAL_ 1171 MF_Variante 0 "keine_Sonderfunktion" 1 "Sondersignalfahrzeug" 2 "Taxi" 3 "Fahrhilfe" 4 "Fahrschule_Extra" 5 "SSF" 6 "DBMC" 7 "Arbeitsmaschine" ;
VAL_ 1171 MF_Schluessel_scan 0 "inaktiv" 1 "aktiv" ;
VAL_ 1171 MF_Laderelais 0 "Relais_offen" 1 "Relais_geschlossen" ;
VAL_ 1171 MF_StartStopp_Info 0 "Motorlauf_nicht_notwendig_(Stoppfreigabe)" 1 "Motoranlauf_nicht_zwingend_notwendig_(Stoppverbot,keine_Startanforderung)" 2 "Motoranlauf_zwingend_notwendig_(Startanforderung)" 3 "Systemfehler" ;
VAL_ 1171 MF_Fernbed_ein 0 "inaktiv" 1 "aktiv" ;
VAL_ 1171 MF_Standlicht 0 "inaktiv" 1 "aktiv" ;
VAL_ 1171 MF_Fahrlicht 0 "inaktiv" 1 "aktiv" ;
VAL_ 1171 MF_interm_Fernlicht 0 "inaktiv" 1 "aktiv" ;
VAL_ 1171 MF_Warnblinker 0 "inaktiv" 1 "aktiv" ;
VAL_ 1171 MF_Fussraumbel 0 "inaktiv" 1 "aktiv" ;
VAL_ 1171 MF_Innenraumbel 0 "inaktiv" 1 "aktiv" ;
VAL_ 1171 MF_Innenraumbel_Unterdrueck 0 "inaktiv" 1 "aktiv" ;
VAL_ 1171 MF_Notstart 0 "kein_Notstart" 1 "Notstart" ;
VAL_ 1171 MF_Blk_li 0 "inaktiv" 1 "aktiv" ;
VAL_ 1171 MF_Blk_re 0 "inaktiv" 1 "aktiv" ;
VAL_ 1171 MF_Lichthupe 0 "inaktiv" 1 "aktiv" ;
VAL_ 1171 MF_Fernlicht 0 "inaktiv" 1 "aktiv" ;
VAL_ 1171 MF_HFS_verriegeln 0 "nicht_verriegeln" 1 "verriegeln" ;
VAL_ 1171 MF_HFS_entriegeln 0 "nicht_entriegeln" 1 "entriegeln" ;
VAL_ 1171 MF_HBFS_verriegeln 0 "nicht_verriegeln" 1 "verriegeln" ;
VAL_ 1171 MF_HBFS_entriegeln 0 "nicht_entriegeln" 1 "entriegeln" ;
VAL_ 1171 MF_Tippwischen 0 "inaktiv" 1 "aktiv" ;
VAL_ 1171 MF_Frontintervall 0 "inaktiv" 1 "aktiv" ;
VAL_ 1171 MF_Wischerstufe_1 0 "inaktiv" 1 "aktiv" ;
VAL_ 1171 MF_Wischerstufe_2 0 "inaktiv" 1 "aktiv" ;
VAL_ 1171 MF_Frontwaschen 0 "inaktiv" 1 "aktiv" ;
VAL_ 1171 MF_nachtr_Stopp_Anf 0 "nicht_angefordert" 1 "angefordert" ;
VAL_ 1171 MF_Heckintervall 0 "inaktiv" 1 "aktiv" ;
VAL_ 1171 MF_Heckwaschen 0 "inaktiv" 1 "aktiv" ;
VAL_ 1171 MF_Summer 0 "inaktiv" 1 "aktiv" ;
VAL_ 1171 MF_Alarm_Blinkertakt 0 "inaktiv" 1 "aktiv" ;
VAL_ 1171 MF_Alarm_Blinker 0 "inaktiv" 1 "aktiv" ;
VAL_ 1171 MF_TFL_Abschaltung 0 "inaktiv" 1 "aktiv" ;
VAL_ 1171 MF_interm_Takt 0 "inaktiv" 1 "aktiv" ;
VAL_ 1171 MF_Tuerentriegelung_hinten 0 "inaktiv" 1 "aktiv" ;
VAL_ 1171 MF_interm_Fahrlicht 0 "inaktiv" 1 "aktiv" ;
VAL_ 1171 MF_Signalhorn 0 "inaktiv" 1 "aktiv" ;
VAL_ 1171 MF_FH_FT_hoch 0 "inaktiv" 1 "aktiv" ;
VAL_ 1171 MF_FH_FT_tief 0 "inaktiv" 1 "aktiv" ;
VAL_ 1171 MF_FH_BT_hoch 0 "inaktiv" 1 "aktiv" ;
VAL_ 1171 MF_FH_BT_tief 0 "inaktiv" 1 "aktiv" ;
VAL_ 1171 MF_FT_verriegeln 0 "nicht_verriegeln" 1 "verriegeln" ;
VAL_ 1171 MF_FT_entriegeln 0 "nicht_entriegeln" 1 "entriegeln" ;
VAL_ 1171 MF_BT_verriegeln 0 "nicht_verriegeln" 1 "verriegeln" ;
VAL_ 1171 MF_BT_entriegeln 0 "nicht_entriegeln" 1 "entriegeln" ;
VAL_ 1164 MFG_Klappe_Status 0 "Init" 1 "Front" 2 "Heck" 3 "Front_u_Heck" 4 "misch_Front_u_Heck" ;
VAL_ 1164 MF_Radiomute 0 "Kein_Mute" 1 "Mute" ;
VAL_ 1164 MF_Relais_2_Batterie 0 "nicht_betaetigt" 1 "betaetigt" ;
VAL_ 1164 MF_Batteriediagnose 0 "keine_Anzeige" 1 "Anzeige_Batterieservice" 2 "Anzeige_aberkannte_Batterie" 3 "Anzeige_schwache_Batterie" 4 "Anzeige_Batterie_OK" 5 "Anzeige_Batterie_Laden" 6 "Anzeige_Batterie_Pruefen" 7 "Fehler" ;
VAL_ 1164 MFG_AppConnect_Anf 0 "AppConnect_keine_Anforderung" 1 "AppConnect_Anforderung" 2 "AppConnect_Darstellungsrueckgabe" ;
VAL_ 1164 MF_Lampenausfall 0 "iO" 1 "defekt" ;
VAL_ 1164 MF_Blinker_L_Sta 0 "inaktiv" 1 "aktiv" ;
VAL_ 1164 MF_Blinker_R_Sta 0 "inaktiv" 1 "aktiv" ;
VAL_ 1164 MF_interm_Nebelscheinwerfer 0 "inaktiv" 1 "aktiv" ;
VAL_ 1164 MF_Generatordiagnose 0 "keine_Warnung" 1 "Warnung_Stufe_1" 2 "Warnung_Stufe_2" 3 "Nicht_verbaut" ;
VAL_ 1164 MF_Heck_entriegeln 0 "nicht_entriegeln" 1 "entriegeln" ;
VAL_ 1164 MF_Heck_verriegeln 0 "nicht_verriegeln" 1 "verriegeln" ;
VAL_ 1164 MF_2BatSOCzugering 0 "inaktiv" 1 "aktiv" ;
VAL_ 1164 MF_Fahrerhinweis 0 "keine_Anzeige" 1 "Warnung_Verrollsicherheit" 2 "Warnung_Fahrzeug_im_Freien" 3 "Warnung_Verlassen_Verriegeln" 4 "reserved" 5 "reserved" 6 "reserved" 7 "reserved" ;
VAL_ 1164 MF_ZV_Unlock 0 "nicht_entriegeln" 1 "entriegeln" ;
VAL_ 1164 MF_Tuerverriegelung_hinten 0 "inaktiv" 1 "aktiv" ;
VAL_ 1164 MF_2BattAb 0 "inaktiv" 1 "aktiv" ;
VAL_ 1164 MF_2BattHlkAnf 0 "inaktiv" 1 "aktiv" ;
VAL_ 1164 MF_2BattLadWarn 0 "inaktiv" 1 "aktiv" ;
VAL_ 1164 MF_2BattLlaAnf 0 "inaktiv" 1 "aktiv" ;
VAL_ 1164 MF_2BattSpannungsAnf 0 "keine_Anforderung" 1 "Anforderung_Stufe1" 2 "Anforderung_Stufe2" 3 "Anforderung_Stufe3" ;
VAL_ 1164 MF_NotStartAktiv 0 "inaktiv" 1 "aktiv" ;
VAL_ 1164 MF_ExterneLadungWarn 0 "inaktiv" 1 "aktiv" ;
VAL_ 1164 MF_LSH_Zielzeit 14 "Init" 15 "Fehler" ;
VAL_ 1164 MF_LSH_Abschaltstufe 0 "Init" 1 "Stufe1" 2 "Stufe2" 3 "Stufe3" 4 "Transportmodus" 7 "Ruhestrommessmodus" ;
VAL_ 1164 MF_LSH_Einschaltverbot 0 "Init_volleVerfuegbarkeit" 1 "Standheizung_bzw_lueftung_nicht_aktivierbar" ;
VAL_ 817 MFL_Lokalaktiv 0 "war_nicht_lokal_aktiv" 1 "war_lokal_aktiv" ;
VAL_ 817 MFL_M_Taste 0 "nicht_betaetigt" 1 "betaetigt" ;
VAL_ 817 MFL_Paddle_Verbau 0 "verbaut" 1 "nicht_verbaut" ;
VAL_ 817 MFL_Tastencode_1 0 "Key_Released__No_Key" 1 "Context_Menu" 2 "Menu_Up__Next_Screen" 3 "Menu_Down__Previous_Screen" 4 "Up" 5 "Down" 6 "Up__Down_ThumbWheel" 7 "OK__ThumbWheel_Button" 8 "Cancel__Escape" 9 "Main_Menu" 10 "Side_Menu_left" 11 "Side_Menu_right" 12 "FAS_Menu" 13 "Left__Right_ThumbWheel" 14 "FAS_Menu_ThumbWheel" 16 "Volume_Up" 17 "Volume_Down" 18 "Volume_Up__Down_ThumbWheel" 19 "Volume_ThumbWheel_Button" 20 "Audio_Source" 21 "Arrow_A_Up__Right" 22 "Arrow_A_Down__Left" 23 "Arrow_B_Up__Right" 24 "Arrow_B_Down__Left" 25 "PTT__PushToTalk" 26 "PTT_Cancel" 27 "Route_Info" 28 "Hook" 29 "Hang_Up" 30 "Off_Hook" 31 "Light_On__Off" 32 "Mute" 33 "Joker1" 34 "Joker2" 35 "View" 36 "Arrow_A_Up__Down_ThumbWheel" 37 "Lenkradheizung" 38 "Rekuperation" 39 "Tube_Toggle" 40 "DRS_Drag_Reduction_System" 41 "Stopwatch_Start_Stop" 42 "Stopwatch_Nextlap" 100 "MAP" 101 "MAP_Boost" 102 "Turn_signal_left" 103 "Turn_signal_right" 104 "Turn_signal_off" 105 "Flashlight" 106 "Highbeam" 107 "Washer_button" 108 "Wiper_button_left" 109 "Wiper_button_right" 110 "Wiper_button_cancel" 111 "Exhaust_Sound" 112 "Drive_Select_button" 113 "Sport_button" 114 "ESP_Drift_Selection_ThumbWheel" 115 "PTT_special_vehicle" 116 "TravelAssist" 117 "Launch_Control" 118 "Drift_Mode_Button_Increase" 119 "Drift_Mode_Button_Decrease" 120 "Drift_Mode_Button_Select" 121 "Drive_Mode_Button_Increase" 122 "Drive_Mode_Button_Decrease" 123 "Drive_Mode_Button_Select" 124 "E_Boost_Button_Increase" 125 "E_Boost_Button_Decrease" 126 "E_Boost_Button_Select" 127 "PerformanceHybridButton_Increase" 128 "PerformanceHybridButton_Decrease" 129 "EV_Mode_Button" 130 "HUD_Button" 131 "PASM_Wheel" 132 "PASM_Button" 133 "PTV_Wheel" 134 "PTV_Button" 135 "TC_ESC_Wheel" 136 "TC_ESC_Button" 240 "Startup_Reset" 241 "Initialization" ;
VAL_ 817 MFL_Tastencode_2 0 "Key_Released__No_Key" 1 "Context_Menu" 2 "Menu_Up__Next_Screen" 3 "Menu_Down__Previous_Screen" 4 "Up" 5 "Down" 6 "Up__Down_ThumbWheel" 7 "OK__ThumbWheel_Button" 8 "Cancel__Escape" 9 "Main_Menu" 10 "Side_Menu_left" 11 "Side_Menu_right" 12 "FAS_Menu" 13 "Left__Right_ThumbWheel" 14 "FAS_Menu_ThumbWheel" 16 "Volume_Up" 17 "Volume_Down" 18 "Volume_Up__Down_ThumbWheel" 19 "Volume_ThumbWheel_Button" 20 "Audio_Source" 21 "Arrow_A_Up__Right" 22 "Arrow_A_Down__Left" 23 "Arrow_B_Up__Right" 24 "Arrow_B_Down__Left" 25 "PTT__PushToTalk" 26 "PTT_Cancel" 27 "Route_Info" 28 "Hook" 29 "Hang_Up" 30 "Off_Hook" 31 "Light_On__Off" 32 "Mute" 33 "Joker1" 34 "Joker2" 35 "View" 36 "Arrow_A_Up_Right_Down_Left_ThumbWheel" 37 "Lenkradheizung" 38 "Rekuperation" 39 "Tube_Toggle" 40 "DRS_Drag_Reduction_System" 41 "Stopwatch_Start_Stop" 42 "Stopwatch_Nextlap" 100 "MAP" 101 "MAP_Boost" 102 "Turn_signal_left" 103 "Turn_signal_right" 104 "Turn_signal_off" 105 "Flashlight" 106 "Highbeam" 107 "Washer_button" 108 "Wiper_button_left" 109 "Wiper_button_right" 110 "Wiper_button_cancel" 111 "Exhaust_Sound" 112 "Drive_Select_button" 113 "Sport_button" 114 "ESP_Drift_Selection_ThumbWheel" 115 "PTT_special_vehicle" 116 "TravelAssist" 117 "Launch_Control" 118 "Drift_Mode_Button_Increase" 119 "Drift_Mode_Button_Decrease" 120 "Drift_Mode_Button_Select" 121 "Drive_Mode_Button_Increase" 122 "Drive_Mode_Button_Decrease" 123 "Drive_Mode_Button_Select" 124 "E_Boost_Button_Increase" 125 "E_Boost_Button_Decrease" 126 "E_Boost_Button_Select" 127 "PerformanceHybridButton_Increase" 128 "PerformanceHybridButton_Decrease" 129 "EV_Mode_Button" 130 "HUD_Button" 131 "PASM_Wheel" 132 "PASM_Button" 133 "PTV_Wheel" 134 "PTV_Button" 135 "TC_ESC_Wheel" 136 "TC_ESC_Button" 240 "Startup_Reset" 241 "Initialization" ;
VAL_ 817 MFL_Eventcode_1 0 "W_no_event____T_no_event" 1 "W_1_Tick_up__T_pressed_normal" 2 "W_2_Ticks_up__T_touched" 3 "W_3_Ticks_up__T_double_click_nor" 4 "W_4_Ticks_up__T_long_press_nor_1" 5 "W_5_Ticks_up__T_long_press_nor_2" 6 "W_6_Ticks_up__T_long_press_nor_3" 7 "W_7_Ticks_up" 9 "W_7_Ticks_dn__T_pressed_strong" 10 "W_6_Ticks_dn" 11 "W_5_Ticks_dn__T_double_click_str" 12 "W_4_Ticks_dn__T_long_press_str_1" 13 "W_3_Ticks_dn__T_long_press_str_2" 14 "W_2_Ticks_dn__T_long_press_str_3" 15 "W_1_Tick_dn" ;
VAL_ 817 MFL_Eventcode_2 0 "W_no_event____T_no_event" 1 "W_1_Tick_up__T_pressed_normal" 2 "W_2_Ticks_up__T_touched" 3 "W_3_Ticks_up__T_double_click_nor" 4 "W_4_Ticks_up__T_long_press_nor_1" 5 "W_5_Ticks_up__T_long_press_nor_2" 6 "W_6_Ticks_up__T_long_press_nor_3" 7 "W_7_Ticks_up" 9 "W_7_Ticks_dn__T_pressed_strong" 10 "W_6_Ticks_dn" 11 "W_5_Ticks_dn__T_double_click_str" 12 "W_4_Ticks_dn__T_long_press_str_1" 13 "W_3_Ticks_dn__T_long_press_str_2" 14 "W_2_Ticks_dn__T_long_press_str_3" 15 "W_1_Tick_dn" ;
VAL_ 817 MFL_Marke 0 "VW" 1 "Audi" 2 "Seat" 3 "Skoda" 4 "VW_Nutzf" 5 "Bugatti" 6 "Lamborghini" 7 "Bentley" 8 "Rolls Royce" 9 "Quattro" 10 "kein_Hersteller_1" 11 "kein_Hersteller_2" 12 "kein_Hersteller_3" 13 "kein_Hersteller_4" 14 "Ford" 15 "Porsche" ;
VAL_ 817 MFL_Tip_Down 0 "nicht_betaetigt" 1 "betaetigt" ;
VAL_ 817 MFL_Tip_Up 0 "nicht_betaetigt" 1 "betaetigt" ;
VAL_ 817 MFL_SatModul_links_Err 0 "kein_Fehler" 1 "Fehler" ;
VAL_ 817 MFL_SatModul_rechts_Err 0 "kein_Fehler" 1 "Fehler" ;
VAL_ 817 MFL_Fehler_Codierung 0 "kein_Fehler" 1 "Fehler" ;
VAL_ 817 MFL_LR_HZG_Status 0 "inaktiv" 1 "aktiv" ;
VAL_ 817 MFL_LR_HZG_Err 0 "normal" 1 "Fehler" ;
VAL_ 817 MFL_Signalhorn 0 "nicht_betaetigt" 1 "betaetigt" ;
VAL_ 817 MFL_Signalhorn_Err 0 "normal" 1 "Fehler" ;
VAL_ 817 MFL_Tip_links_Err 0 "normal" 1 "Fehler" ;
VAL_ 817 MFL_Tip_rechts_Err 0 "normal" 1 "Fehler" ;
VAL_ 817 MFL_Taste_links_Err 0 "normal" 1 "Fehler" ;
VAL_ 817 MFL_Taste_rechts_Err 0 "normal" 1 "Fehler" ;
VAL_ 817 MFL_ECU_Err 0 "normal" 1 "Fehler" ;
VAL_ 817 MFL_Response_Err 0 "normal" 1 "Fehler" ;
VAL_ 560 MFL_Beruehrungserkennung 0 "nicht_beruehrt" 1 "links" 2 "rechts" 3 "beidseitig" ;
VAL_ 560 MFL_Touch_Event 0 "nicht_betaetigt" 1 "Tippen" 2 "Wischen_Slide" 3 "Geste" 4 "Doppeltippen" 5 "Longpress_1" 6 "Longpress_2" 7 "Longpress_3" 8 "Press" 9 "Strongpress" 10 "reserviert" 11 "reserviert" 12 "reserviert" 13 "reserviert" 14 "Taktgeber_Inkrement" 15 "Fehler" ;
VAL_ 2463978751 MFL_Vibrationsimpuls_rechts 0 "Kein_Impuls" 1 "Impuls_1" 2 "Impuls_2" 3 "Impuls_3" 4 "Impuls_4" 5 "Impuls_5" 6 "Impuls_6" 7 "Impuls_7" 8 "Impuls_8" 9 "Impuls_9" 10 "Impuls_10" 11 "Impuls_11" 12 "Impuls_12" 13 "Impuls_13" 14 "Impuls_14" 15 "Impuls_15" ;
VAL_ 2463978751 MFL_Vibrationsimpuls_links 0 "Kein_Impuls" 1 "Impuls_1" 2 "Impuls_2" 3 "Impuls_3" 4 "Impuls_4" 5 "Impuls_5" 6 "Impuls_6" 7 "Impuls_7" 8 "Impuls_8" 9 "Impuls_9" 10 "Impuls_10" 11 "Impuls_11" 12 "Impuls_12" 13 "Impuls_13" 14 "Impuls_14" 15 "Impuls_15" ;
VAL_ 2463978751 MFL_Tasten_Volume_benoetigt 0 "nicht_benoetigt" 1 "benoetigt" ;
VAL_ 2463978751 MFL_Tasten_UpDownOK_benoetigt 0 "nicht_benoetigt" 1 "benoetigt" ;
VAL_ 2463978751 MFL_Taste_SDS_benoetigt 0 "nicht_benoetigt" 1 "benoetigt" ;
VAL_ 1471 MFL_Tastencode_1 0 "Key_Released__No_Key" 1 "Context_Menu" 2 "Menu_Up__Next_Screen" 3 "Menu_Down__Previous_Screen" 4 "Up" 5 "Down" 6 "Up__Down_ThumbWheel" 7 "OK__ThumbWheel_Button" 8 "Cancel__Escape" 9 "Main_Menu" 10 "Side_Menu_left" 11 "Side_Menu_right" 12 "FAS_Menu" 13 "Left__Right_ThumbWheel" 14 "FAS_Menu_ThumbWheel" 16 "Volume_Up" 17 "Volume_Down" 18 "Volume_Up__Down_ThumbWheel" 19 "Volume_ThumbWheel_Button" 20 "Audio_Source" 21 "Arrow_A_Up__Right" 22 "Arrow_A_Down__Left" 23 "Arrow_B_Up__Right" 24 "Arrow_B_Down__Left" 25 "PTT__PushToTalk" 26 "PTT_Cancel" 27 "Route_Info" 28 "Hook" 29 "Hang_Up" 30 "Off_Hook" 31 "Light_On__Off" 32 "Mute" 33 "Joker1" 34 "Joker2" 35 "View" 36 "Arrow_A_Up__Down_ThumbWheel" 37 "Lenkradheizung" 38 "Rekuperation" 39 "Tube_Toggle" 40 "DRS_Drag_Reduction_System" 41 "Stopwatch_Start_Stop" 42 "Stopwatch_Nextlap" 100 "MAP" 101 "MAP_Boost" 102 "Turn_signal_left" 103 "Turn_signal_right" 104 "Turn_signal_off" 105 "Flashlight" 106 "Highbeam" 107 "Washer_button" 108 "Wiper_button_left" 109 "Wiper_button_right" 110 "Wiper_button_cancel" 111 "Exhaust_Sound" 112 "Drive_Select_button" 113 "Sport_button" 114 "ESP_Drift_Selection_ThumbWheel" 115 "PTT_special_vehicle" 116 "TravelAssist" 117 "Launch_Control" 118 "Drift_Mode_Button_Increase" 119 "Drift_Mode_Button_Decrease" 120 "Drift_Mode_Button_Select" 121 "Drive_Mode_Button_Increase" 122 "Drive_Mode_Button_Decrease" 123 "Drive_Mode_Button_Select" 124 "E_Boost_Button_Increase" 125 "E_Boost_Button_Decrease" 126 "E_Boost_Button_Select" 127 "PerformanceHybridButton_Increase" 128 "PerformanceHybridButton_Decrease" 129 "EV_Mode_Button" 130 "HUD_Button" 131 "PASM_Wheel" 132 "PASM_Button" 133 "PTV_Wheel" 134 "PTV_Button" 135 "TC_ESC_Wheel" 136 "TC_ESC_Button" 240 "Startup_Reset" 241 "Initialization" ;
VAL_ 1471 MFL_Tastencode_2 0 "Key_Released__No_Key" 1 "Context_Menu" 2 "Menu_Up__Next_Screen" 3 "Menu_Down__Previous_Screen" 4 "Up" 5 "Down" 6 "Up__Down_ThumbWheel" 7 "OK__ThumbWheel_Button" 8 "Cancel__Escape" 9 "Main_Menu" 10 "Side_Menu_left" 11 "Side_Menu_right" 12 "FAS_Menu" 13 "Left__Right_ThumbWheel" 14 "FAS_Menu_ThumbWheel" 16 "Volume_Up" 17 "Volume_Down" 18 "Volume_Up__Down_ThumbWheel" 19 "Volume_ThumbWheel_Button" 20 "Audio_Source" 21 "Arrow_A_Up__Right" 22 "Arrow_A_Down__Left" 23 "Arrow_B_Up__Right" 24 "Arrow_B_Down__Left" 25 "PTT__PushToTalk" 26 "PTT_Cancel" 27 "Route_Info" 28 "Hook" 29 "Hang_Up" 30 "Off_Hook" 31 "Light_On__Off" 32 "Mute" 33 "Joker1" 34 "Joker2" 35 "View" 36 "Arrow_A_Up_Right_Down_Left_ThumbWheel" 37 "Lenkradheizung" 38 "Rekuperation" 39 "Tube_Toggle" 40 "DRS_Drag_Reduction_System" 41 "Stopwatch_Start_Stop" 42 "Stopwatch_Nextlap" 100 "MAP" 101 "MAP_Boost" 102 "Turn_signal_left" 103 "Turn_signal_right" 104 "Turn_signal_off" 105 "Flashlight" 106 "Highbeam" 107 "Washer_button" 108 "Wiper_button_left" 109 "Wiper_button_right" 110 "Wiper_button_cancel" 111 "Exhaust_Sound" 112 "Drive_Select_button" 113 "Sport_button" 114 "ESP_Drift_Selection_ThumbWheel" 115 "PTT_special_vehicle" 116 "TravelAssist" 117 "Launch_Control" 118 "Drift_Mode_Button_Increase" 119 "Drift_Mode_Button_Decrease" 120 "Drift_Mode_Button_Select" 121 "Drive_Mode_Button_Increase" 122 "Drive_Mode_Button_Decrease" 123 "Drive_Mode_Button_Select" 124 "E_Boost_Button_Increase" 125 "E_Boost_Button_Decrease" 126 "E_Boost_Button_Select" 127 "PerformanceHybridButton_Increase" 128 "PerformanceHybridButton_Decrease" 129 "EV_Mode_Button" 130 "HUD_Button" 131 "PASM_Wheel" 132 "PASM_Button" 133 "PTV_Wheel" 134 "PTV_Button" 135 "TC_ESC_Wheel" 136 "TC_ESC_Button" 240 "Startup_Reset" 241 "Initialization" ;
VAL_ 1471 MFL_Eventcode_1 0 "W_no_event____T_no_event" 1 "W_1_Tick_up__T_pressed_normal" 2 "W_2_Ticks_up__T_touched" 3 "W_3_Ticks_up__T_double_click_nor" 4 "W_4_Ticks_up__T_long_press_nor_1" 5 "W_5_Ticks_up__T_long_press_nor_2" 6 "W_6_Ticks_up__T_long_press_nor_3" 7 "W_7_Ticks_up" 9 "W_7_Ticks_dn__T_pressed_strong" 10 "W_6_Ticks_dn" 11 "W_5_Ticks_dn__T_double_click_str" 12 "W_4_Ticks_dn__T_long_press_str_1" 13 "W_3_Ticks_dn__T_long_press_str_2" 14 "W_2_Ticks_dn__T_long_press_str_3" 15 "W_1_Tick_dn" ;
VAL_ 1471 MFL_Eventcode_2 0 "W_no_event____T_no_event" 1 "W_1_Tick_up__T_pressed_normal" 2 "W_2_Ticks_up__T_touched" 3 "W_3_Ticks_up__T_double_click_nor" 4 "W_4_Ticks_up__T_long_press_nor_1" 5 "W_5_Ticks_up__T_long_press_nor_2" 6 "W_6_Ticks_up__T_long_press_nor_3" 7 "W_7_Ticks_up" 9 "W_7_Ticks_dn__T_pressed_strong" 10 "W_6_Ticks_dn" 11 "W_5_Ticks_dn__T_double_click_str" 12 "W_4_Ticks_dn__T_long_press_str_1" 13 "W_3_Ticks_dn__T_long_press_str_2" 14 "W_2_Ticks_dn__T_long_press_str_3" 15 "W_1_Tick_dn" ;
VAL_ 1471 MFL_Marke 0 "VW" 1 "Audi" 2 "Seat" 3 "Skoda" 4 "VW_Nutzf" 5 "Bugatti" 6 "Lamborghini" 7 "Bentley" 8 "Rolls Royce" 9 "Quattro" 10 "kein_Hersteller_1" 11 "kein_Hersteller_2" 12 "kein_Hersteller_3" 13 "kein_Hersteller_4" 14 "Ford" 15 "Porsche" ;
VAL_ 958 MO_StartStopp_Status 0 "System_in_diesem_KL15_Zyklus_nicht_verfuegbar" 1 "System_aktiv_keine_Freigabe_durch_StartStop_Koordinator" 2 "System_aktiv_alle_Freigaben_liegen_vor" 3 "System_aktiv_mindestens_eine_Freigabe_fehlt" ;
VAL_ 958 MO_StartStopp_Wiederstart 0 "Wiederstart_inaktiv" 1 "Wiederstart_aktiv" ;
VAL_ 958 MO_StartStopp_Motorstopp 0 "Motor_Stop_inaktiv" 1 "Motor_Stop_aktiv" ;
VAL_ 958 MO_Freig_Reku 0 "Rekuperations-Modus aus" 1 "Empfehlung Spannungsanhebung" 2 "Empfehlung Spannungsabsenkung" 3 "Rekuperationsmodus aktiv, Spannungsvariation nicht notwendig" ;
VAL_ 958 MO_Kl_75 0 "Aus" 1 "Ein" ;
VAL_ 958 MO_Kl_50 0 "aus" 1 "KL50_ein_Startausfuehrung_Fahrer" ;
VAL_ 958 MO_Gangposition 0 "Gang_N" 1 "Gang_1" 2 "Gang_2" 3 "Gang_3" 4 "Gang_4" 5 "Gang_5" 6 "Gang_6" 7 "Gang_7" 8 "Gang_8" 9 "Automat_P" 10 "Automat_Vorwaerts_S" 11 "Automat_Vorwaerts_D/E" 12 "Zwischenstellung" 13 "Gang_R" 14 "Istgang_nicht_definiert" 15 "Fehler" ;
VAL_ 958 MO_StartStopp_Fahrerwunsch 0 "Init" 1 "Stoppverbot_durch_Fahrer" 2 "Stoppfreigabe_durch_Fahrer" 3 "Stoppanforderung_durch_Fahrer" ;
VAL_ 958 MO_HYB_Fahrbereitschaft 0 "keine_Fahrbereitschaft" 1 "Fahrbereitschaft" ;
VAL_ 958 MO_Ext_E_Fahrt_aktiv 0 "Rueckmeldung_E_Taster_aus" 1 "Rueckmeldung_E_Taster_ein" ;
VAL_ 958 MO_Fahrer_bremst 0 "kein_Bremsen" 1 "Bremse_betaetigt" ;
VAL_ 958 MO_QBit_Fahrer_bremst 0 "gueltiger_Wert" 1 "Ersatz_Init_oder_Fehlerwert" ;
VAL_ 958 MO_BLS 0 "kein_Bremsen" 1 "Bremse_betaetigt" ;
VAL_ 958 MO_Konsistenz_Bremsped 0 "Bremspedalinformation_plausibel" 1 "Bremspedalinformation_unplausibel" ;
VAL_ 958 MO_Timeout_ESP 0 "Empfang_iO" 1 "Timeout" ;
VAL_ 958 MO_Klima_Eingr 0 "kein Eingriff" 1 "Klimakompressor ausschalten" 2 "Klimakompressor Leistungsreduzierung" 3 "Klimakompressor aufgrund der Heissleuchtenvorwarnung ausschalten" ;
VAL_ 958 MO_Aussp_Anlass 0 "Anlasser_darf_angesteuert_werden" 1 "Anlasser_ausspuren__Ansteuerung_nicht_moeglich" ;
VAL_ 958 MO_Freig_Anlass 0 "Start_nicht_zulaessig" 1 "Startfreigabe" ;
VAL_ 958 MO_Kuppl_schalter 0 "Schalter_sagt_ausgekuppelt" 1 "Schalter_sagt_eingekuppelt" ;
VAL_ 958 MO_Interlock 0 "Interlockschalter_nicht_betaetigt" 1 "Interlockschalter_betaetigt" ;
VAL_ 958 MO_Motor_laeuft 0 "Motor_laeuft_nicht" 1 "Motor_laeuft_autark_und_stabil_und_darf_mechanisch_belastet_werden" ;
VAL_ 958 MO_Kickdown 0 "kein_Kickdown" 1 "Kickdown" ;
VAL_ 958 MO_QBit_KL_75 0 "gueltiger_Wert" 1 "Ersatz_Init_oder_Fehlerwert" ;
VAL_ 958 MO_EKlKomLeiRed 0 "keine_Leistungsbegr" 1 "Leistungsbegr_75" 2 "Leistungsbegr_50" 3 "Leistungsbegr_25" ;
VAL_ 958 MO_Handshake_STH 0 "keine EKP-Ansteuerung durch STH-Anforderung" 1 "EKP-Ansteuerung durch STH-Anforderung" ;
VAL_ 958 MO_BKV_Unterdruckwarnung 0 "Unterdruckhaushalt_iO" 1 "Unterdruckhaushalt_niO" ;
VAL_ 958 MO_Freigabe_Segeln 0 "Segelbetrieb_nicht_freigegeben" 1 "Segelbetrieb_freigegeben" ;
VAL_ 958 MO_PTC_Status 0 "nicht_unterstuetzt" 1 "Stufe_0" 2 "Stufe_1" 3 "Stufe_2" 4 "Stufe_3" 7 "PTC_am_BCM" ;
VAL_ 958 MO_QBit_Gangposition 0 "gueltiger_Wert" 1 "Ersatz_Init_oder_Fehlerwert" ;
VAL_ 958 MO_Signalquelle_Gangposition 0 "Sensorsignal" 1 "Modellsignal" ;
VAL_ 958 MO_Remotestart_Betrieb 0 "MSG_nicht_bereit_fuer_RS_Betrieb" 1 "MSG_bereit_fuer_oder_im_RS_Betrieb" ;
VAL_ 958 MO_Remotestart_moeglich 0 "Remotestart_nicht_moeglich" 1 "Remotestart_moeglich" ;
VAL_ 958 MO_FMAus_aktiv 0 "inaktiv" 1 "Segeln_mit_Motor_aus_aktiv" ;
VAL_ 958 MO_FMAus_Startvariante 0 "kein_Motorstart" 1 "Motorstart_elektrischer_Starter" 2 "GetriebeAnschleppstart" 3 "GetriebeNotAnschleppstart" ;
VAL_ 958 MO_BMS_NV_Anf_stuetzen 0 "nicht_notwendig" 1 "notwendig" ;
VAL_ 958 MO_Zylinderabschaltung 0 "Vollmotorbetrieb_VMB" 1 "Uebergang_HMB_in_VMB" 2 "Uebergang_VMB_in_HMB" 3 "Halbmotorbetrieb_HMB" ;
VAL_ 958 MO_HYB_VM_aktiv 0 "VM_nicht_aktiv" 1 "VM_aktiv" ;
VAL_ 958 MO_StartVorauss_erfuellt 0 "Signal_nicht_bedient" 1 "StartVorauss_nicht_ueberpruefbar" 2 "StartVorauss_nicht_erfuellt" 3 "StartVorauss_erfuellt" ;
VAL_ 1648 MO_ANC_Kennfeld_Anf 0 "Kennfeld_1" 1 "Uebergang_Kennfeld_2_nach_1" 2 "Uebergang_Kennfeld_1_nach_2" 3 "Kennfeld_2" ;
VAL_ 1648 MO_Bremslicht_Reku 0 "Aus" 1 "Ein" ;
VAL_ 1648 MO_StartStopp_PopUp 0 "Statuswechsel_ohne_Taster (Init)" 1 "StSt_per_Taster_deaktiviert" 2 "StSt_per_Taster_aktiviert" 3 "nicht verwendet" ;
VAL_ 1648 MO1_Sperr_Info_WFS 0 "nicht_gesperrt" 1 "gesperrt" ;
VAL_ 1648 MO1_Freigabe_Info_WFS 0 "ungueltig" 1 "gueltig" ;
VAL_ 1648 MO_EPCL 0 "EPCL_aus_kein_Text" 1 "EPCL_gelb_Stoerung" 2 "EPCL_gelb_Leistungsbeschraenkung" 3 "EPCL_rot_Fzg_sicher_abstellen" ;
VAL_ 1648 MO_Zylabsch_Texte_02 0 "ein_ZAS_generell_keine_ZAS_Anzeigen" 1 "ZAS_im_VMB" 2 "ZAS_im_ASB_1_Zyl_aktiv" 3 "ZAS_im_ASB_2_Zyl_aktiv" 4 "ZAS_im_ASB_3_Zyl_aktiv" 5 "ZAS_im_ASB_4_Zyl_aktiv" 6 "ZAS_im_ASB_5_Zyl_aktiv" 7 "ZAS_im_ASB_6_Zyl_aktiv" 8 "ZAS_im_ASB_8_Zyl_aktiv" 9 "ZAS_im_ASB_12_Zyl_aktiv" 13 "Uebergangsbetrieb" 14 "keine_ZAS_Anzeige_ggf_Stopp_Schub_Betrieb" 15 "ZAS_Stoerungs_Anzeige" ;
VAL_ 1648 MO_Fahrzeugtyp 0 "Verbrenner_Fahrzeug" 1 "Hybrid" 2 "E_Fahrzeug" 3 "E_Fahrzeug_mit_Range_Extender" 4 "Brennstoffzellenfahrzeug" 5 "tbd" 6 "tbd" 7 "tbd" ;
VAL_ 1648 MO_Abstellzeit 254 "Init" 255 "reserviert" ;
VAL_ 1648 MO_Abstellzeit_Status 0 "Abstellzeit_nicht_berechnet" 1 "Abstellzeit_berechnet" 2 "Abstellzeit_Minimalwert" 3 "Abstellzeit_ungueltig" ;
VAL_ 1648 MO1_Freigabe_Verfallsinfo_WFS 0 "verfaellt_nicht" 1 "verfaellt" ;
VAL_ 1648 MO_Hybrid_StartStopp_LED 0 "LED_aus_und_Blinken_aus" 1 "LED_ein_und_Blinken_aus" 2 "LED_ein_und_Blinken_ein_50_percent" 3 "reserviert" ;
VAL_ 1648 MO_Fehler_Zylabsch 0 "kein_Fehler" 1 "Notlauf_Vollmotorbetrieb" 2 "Notlauf_mindestens_einem_abgesch_Zylinder" ;
VAL_ 1648 MO_Anzahl_Abgesch_Zyl 0 "Vollmotorbetrieb" 1 "1_Zylinder_abgeschaltet" 2 "2_Zylinder_abgeschaltet" 3 "3_Zylinder_abgeschaltet" 4 "4_Zylinder_abgeschaltet" 5 "5_Zylinder_abgeschaltet" 6 "6_Zylinder_abgeschaltet" 7 "8_Zylinder_abgeschaltet" ;
VAL_ 1648 MO_Zylabsch_Texte 0 "keine_Texte" 1 "Zylinderabschaltung_deaktivieren" 2 "Zylinderabschaltung_aktivieren" 3 "Zylinderabschaltung_unruhig" ;
VAL_ 1648 MO_Ethanol_BS_Texte 0 "kein_Text" 1 "E85_Warm_Up" 2 "FlexFuel_Warnung_Stufe_3" 3 "Warmfahrempfehlung_MQB__FlexFuel_Warnung_Stufe_1" 4 "FlexFuel_Warnung_Stufe_2" 5 "FlexFuel_Warnung_Stufe_4" 6 "E25_Warm_Up" ;
VAL_ 1648 MO_Drehzahl_Warnung 0 "keinen_Warnhinweis_anzeigen" 1 "Warnhinweis_anzeigen" ;
VAL_ 1648 MO_obere_Drehzahlgrenze 0 "Init" ;
VAL_ 967 MO_Kuehlerluefter_MUX 0 "Kuehlerluefter_1" 1 "Kuehlerluefter_2" ;
VAL_ 967 MO_Kuehlerluefter_1 126 "Init" 127 "Fehler" ;
VAL_ 967 MO_Kuehlerluefter_2 126 "Init" 127 "Fehler" ;
VAL_ 967 MO_EFLEX_Lampe 0 "Lampe_aus" 1 "Lampe_ein" 2 "Lampe_blinkend" 3 "Lampe_blinkend_mit_Akustik" ;
VAL_ 967 MO_KJS_nicht_bereit 0 "kein_Fehler" 1 "Fehler" ;
VAL_ 967 MO_ITM_Warnung_Pumpe 0 "keine_Warnung" 1 "ITM_Warnung" ;
VAL_ 967 WIV_Anzeige_aktiv 0 "Anzeige aus" 1 "WIV Anzeige aktiv" ;
VAL_ 967 WIV_Oelmin_Warn 0 "in_Ordnung" 1 "Warnung" ;
VAL_ 967 WIV_Sensorfehler 0 "in_Ordnung" 1 "Sensor_defekt" ;
VAL_ 967 WIV_Schieflage 0 "Fahrzeug_gerade" 1 "Fahrzeug_in_Schieflage" ;
VAL_ 967 MO_Zustand_HWP 0 "HWP_nicht_schaltbar" 1 "HWP_foerdert_nicht" 2 "HWP_foerdert" 3 "reserviert" ;
VAL_ 967 OLEV_Systemstoerung 0 "Ölsystem i.O." 1 "Systemstörung Ölsystem" ;
VAL_ 967 MO_Oelwarnung_max 0 "keine_Warnung" 1 "Warnfall_aktiv" ;
VAL_ 967 WIV_Oelsystem_aktiv 0 "Anzeige_aus" 1 "Anzeige_aktiv" ;
VAL_ 967 WIV_nicht_betriebswarm 0 "Motor_warm" 1 "Motor_nicht_betriebswarm" ;
VAL_ 967 WIV_Ueberfuell_Warn 0 "in_Ordnung" 1 "Ueberfuellwarnung" ;
VAL_ 967 WIV_laufender_Motor 0 "Messung_moeglich" 1 "Messung_nicht_moeglich" ;
VAL_ 967 MO_E_Warnungen 0 "keine_Anzeige" 1 "Fehler_Elektrosystem_Anhalten" 2 "Fehler_Elektrosystem_Werkstatt" 3 "Elektrosystem_ueberhitzt_Stopp" 4 "Fehler_Hybridsystem_Anhalten" 5 "Fehler_Hybridsystem_Werkstatt" 6 "Fehler_Wasserstoffsystem_Anhalte" 7 "Fehler_Wasserstoffsystem_Werksta" 8 "reserviert_keine_Anzeige" 9 "reserviert_keine_Anzeige" 10 "reserviert_keine_Anzeige" 11 "reserviert_keine_Anzeige" 12 "reserviert_keine_Anzeige" 13 "reserviert_keine_Anzeige" 14 "reserviert_keine_Anzeige" 15 "reserviert_keine_Anzeige" ;
VAL_ 967 MO_Text_Motorstart 0 "keine_Anzeige" 1 "Motor_im_Stoppbetrieb" 2 "StartStopp_sicherheitsbedingt_deaktiviert" 3 "System_fordert_Wiederstart" 4 "Aufforderung_Motorstart" 5 "Motorlauf_noetig" 6 "Motorlaufwarnung" 9 "Unerwuenschter_Motorstillstand" 10 "Motorstart_nicht_moeglich" 11 "Fehler_Kupplungsschalter" 12 "Motor_startet" 13 "Kupplung_betaetigen" 14 "Waehlhebel_in_PN_Position" 15 "Bremse_treten" ;
VAL_ 967 MO_E_Texte 0 "keine_Anzeige" 1 "Batterie_fast_leer" 2 "Ladestecker_nicht_fahrbereit" 3 "VM_Betrieb_erforderlich" 4 "Batterie_laedt_Nicht_ausschalten" 5 "Bitte_Bremse_treten" 6 "manueller_Neustart_erforderlich" 7 "Stopp_Fahrzeug_nicht_abschleppen" 8 "kein_Neustart_Haube_nicht_oeffnen" 9 "Motorstart_im_naechsten_Zyklus" 10 "VM_erforderlich_EVMode_abwaehlen" 11 "laengerer_VMBetrieb_Bordbuch" 12 "Tank_leer_VM_nicht_verfuegbar" 13 "Bitte_warten_Motor_startet" 14 "kein_Start_Batterietemperatur" 15 "Ende_elektrische_Reichweite_erreicht" ;
VAL_ 967 WIV_Oeldyn_avl 0 "Oeldyn_nicht_vorhanden" 1 "Oeldyn_vorhanden" ;
VAL_ 967 OLEV_Oelstand_nicht_vorhanden 0 "Ölstand vorhanden" 1 "Ölstand nicht vorhanden" ;
VAL_ 967 MO_Systemlampe 0 "Lampe aus" 1 "Lampe ein" ;
VAL_ 967 MO_OBD2_Lampe 0 "Lampe aus" 1 "Lampe ein" ;
VAL_ 967 MO_Heissleuchte 0 "Lampe aus" 1 "Lampe ein" ;
VAL_ 967 MO_Partikel_Lampe 0 "Lampe aus" 1 "Lampe ein" ;
VAL_ 967 MO_RedFahrleistung_Lampe 0 "Lampe_aus" 1 "Lampe_ein" ;
VAL_ 967 WIV_Oelstand_nicht_vorhanden 0 "Ölstand vorhanden" 1 "Ölstand nicht vorhanden" ;
VAL_ 967 WIV_nachfuellanzeige_ein 0 "keine_Nachfuellanzeige" 1 "Nachfuellanzeige" ;
VAL_ 967 WIV_Ueberfuell_deaktiv 0 "Ueberfuellwarnung_am_Kombi_aktiv" 1 "Ueberfuellwarnung_am_Kombi_deaktiv" ;
VAL_ 967 WIV_Unterfuell_Warn 0 "in_Ordnung" 1 "Unterfuellwarnung" ;
VAL_ 967 MO_Tankdeckel_Lampe 0 "Lampe aus" 1 "Lampe ein" ;
VAL_ 967 MO_Text_Tankdeckelwarn 0 "kein_Text" 1 "Anzeige_Text_Tankdeckelwarnung_im_Kombi" ;
VAL_ 967 MO_Vorglueh_Lampe 0 "Lampe_aus" 1 "Lampe_ein" ;
VAL_ 967 WIV_Oeldr_Warn_Motor 0 "keine_Warnung" 1 "niedrige_Oeldruckstufe_nicht_erreicht" ;
VAL_ 967 MO_E_Mode 0 "keine_Anzeige" 1 "E_Mode_passiv" 2 "E_Mode_aktiv" 3 "E_Mode_inaktiv_nicht_verfuegbar" 4 "E_Mode_aktiv_nicht_verfuegbar" 5 "reserviert_keine_Anzeige" 6 "reserviert_keine_Anzeige" 7 "reserviert_keine_Anzeige" ;
VAL_ 706 MO_Powermeter_Dauer_Grenze 4094 "Init" 4095 "Fehler" ;
VAL_ 706 MO_Anzeige_StSt_Text 0 "keine_Anzeige" 1 "Systemfehler" 2 "Motor_manuell_starten" 3 "Rueckmeldung_durch_Fahrstufe_einlegen" 4 "Zuendungsabschaltwarnung_Timerstart" 5 "Zum_Motorstart_Bremse_treten" 6 "StSt_Aktivierung_nicht_moeglich_auf_Grund_Fahrprogramm" ;
VAL_ 706 MO_Anzeige_StSt_Symbol 0 "keine_Anzeige" 1 "StSt_aktiv" 2 "Motorlauf_noetig" 3 "Fahrer_temporaer_abwesend" 4 "Fahrer_vielleicht_anwesend" ;
VAL_ 706 MO_ADR_Status 0 "nicht_aktiv" 1 "ADR_angefordert" 2 "ADR_aktiv" 3 "ADR_Fehler" ;
VAL_ 706 MO_AGA_Sound_Texte 0 "keine_Anzeige" 1 "Sound_off" 2 "Sound_on" ;
VAL_ 706 MO_Anzeige_FMAus_Text 0 "keine_Anzeige" 1 "FMAus_Systemfehler" ;
VAL_ 706 PEA_Texte 0 "Keine_Anzeige" 1 "PEA_Fahreruebernahme_noetig" 2 "PEA_Reku_nicht_verfuegbar" ;
VAL_ 706 TSK_Ueberstimmt_vMax_FahrerInfo 0 "nicht_ueberstimmbar" 1 "ueberstimmbar" 2 "ueberstimmt" ;
VAL_ 706 MO_Rekuperationsstufe 0 "keine_Anzeige" 1 "Rekuperationsstufe_1" 2 "Rekuperationsstufe_2" 3 "Rekuperationsstufe_3" 4 "Rekuperationsstufe_4" 5 "Rekuperationsstufe_5" 6 "Rekuperationsstufe_auto" 7 "Init" ;
VAL_ 706 TSK_Einheit_vMax_FahrerInfo 0 "km_h" 1 "mph" ;
VAL_ 706 TSK_Status_vMax_FahrerInfo 0 "keine_Anzeige" 1 "Anzeige_im_Fahrzeugstatus" 2 "PopUp_ohne_Gong__Eintrag_FhzStat" 3 "PopUp_mit_Gong__Eintrag_FhzStat" ;
VAL_ 706 MO_Anz_Kuehlerluefter 0 "Kein_KuehlerluefterNachlauf" 1 "Text_Luefternachlauf_aktiv" 2 "Text_Luefternachlauf_DPF_aktiv" 3 "Platzhalter_weitere_Signale" 4 "Platzhalter_weitere_Signale" 5 "Platzhalter_weitere_Signale" 6 "Platzhalter_weitere_Signale" 7 "Platzhalter_weitere_Signale" ;
VAL_ 706 FDR_Warnung_ALR 0 "keine_Anzeige" 1 "Text_Stoerung_Allradverteilung" 2 "Text_Ausfall_Allradverteilung" 3 "reserved" ;
VAL_ 706 MO_EM_Ueberhitzungswarnung 0 "keine_Anzeige" 1 "EM_heiss_langsam_Fahren" 2 "EM_heiss_Geschw_begrenzt" 3 "EM_heiss_Anhalten" ;
VAL_ 706 MO_ElAntrieb_Abschleppwarnung 0 "keine_Anzeige" 1 "Abschleppen_nur_vorne_angehoben" 2 "Abschleppen_nur_hinten_angehoben" 3 "Fahrzeug_nicht_abschleppen" ;
VAL_ 706 TSK_vMax_FahrerInfo 0 "Init___kein_Wert" ;
VAL_ 267 MO_Fahrpedalrohwert_01 255 "Fehler" ;
VAL_ 267 MO_QBit_Fahrpedalwerte_01 0 "gueltiger_Wert" 1 "Ersatz_Init_oder_Fehlerwert" ;
VAL_ 267 MO_Fahrpedalgradient 255 "Fehler" ;
VAL_ 267 MO_Sig_Fahrpedalgradient 0 "Fahrpedalgradient positiv" 1 "Fahrpedalgradient negativ" ;
VAL_ 267 MO_rel_Saugrohrdruck 0 "Init_Ueberdruck" 63 "Fehler" ;
VAL_ 267 MO_rel_Saugrohrdruck_gem_err 0 "errechnet" 1 "gemessen" ;
VAL_ 267 MO_Moment_im_Leerlauf 0 "kein_Leergas" 1 "Leergas" ;
VAL_ 267 MO_Schubabschaltung 0 "keine_Schubabschaltung" 1 "Schubabschaltung_aktiv" ;
VAL_ 267 MO_StartStopp_StoppVorbereitung 0 "Motorstopp_nicht_in_Vorbereitung" 1 "Motorstopp_in_Vorbereitung" ;
VAL_ 267 MO_Entkopplung_Sollschlupf 125 "Notoeffnen_Anfahrelement" 126 "Init" ;
VAL_ 267 MO_temporaere_Fahrerabwesenheit 0 "nicht_erkannt" 1 "erkannt" ;
VAL_ 267 TSK_a_Soll_gradientenbegrenzt 127 "Init_oder_nicht_aktiv" ;
VAL_ 267 TSK_Status 0 "Hauptschalter_aus" 1 "Init" 2 "passiv" 3 "aktiv" 4 "Uebertreten" 5 "brake_only_Mode" 6 "reversibel_aus" 7 "irreversibel_aus" ;
VAL_ 267 TSK_v_Begrenzung_aktiv 0 "inaktiv" 1 "aktiv" ;
VAL_ 267 TSK_Standby_Anf_ESP 0 "keine_Standby_Anforderung" 1 "Standby_Anforderung" ;
VAL_ 267 TSK_Freig_Verzoeg_Anf 0 "Verzoegerungsanforderung_nicht_freigegeben" 1 "Verzoegerungsanforderung_freigegeben" ;
VAL_ 267 TSK_Limiter_ausgewaehlt 0 "kein_Limiter_ausgewaehlt" 1 "Limiter_ausgewaehlt" ;
VAL_ 267 TSK_Hauptschalter_GRA_ACC 0 "Init" 1 "Aus" 2 "Ein" 3 "Fehler" ;
VAL_ 267 TSK_SRBM_Anf_ASIL 0 "keine_SRBM_Anforderung" 1 "SRBM_Anforderung_in_ASIL_QM" 2 "SRBM_Anforderung_in_ASIL_A" 3 "SRBM_Anforderung_in_ASIL_B" 4 "SRBM_Anforderung_in_ASIL_C" ;
VAL_ 267 TSK_ax_Getriebe_02 511 "Neutralwert" ;
VAL_ 267 TSK_Zwangszusch_ESP 0 "keine_ESP_ASR_Beeinflussung" 1 "ESP_ASR_Beeinflussung" ;
VAL_ 267 TSK_Radsollmoment 65534 "Init" 65535 "Fehler" ;
VAL_ 267 TSK_Kategorie_Verzoegerungsfkt 0 "Schnittstelle_nicht_vorhanden" 1 "Kategorie_Fahrerassistenz" 2 "Kategorie_Schubverzoegerung" 3 "reserviert" ;
VAL_ 267 TSK_Notstopp_Anf 0 "Ueberwachung_aus" 1 "Ueberwachung_ein" 2 "Notstopp_ausloesen" ;
VAL_ 267 MO_Status_MinDrzEingriff 0 "kein_Eingriff" 1 "Schalteingriff" 2 "ESP_Eingriff" 3 "Achsdifferenzdrehzahl" 4 "Bauteilschutz" 5 "Rennstart_Fahrbarkeit" ;
VAL_ 267 MO_Status_MaxDrzEingriff 0 "kein_Eingriff" 1 "Schalteingriff" 2 "ESP_Eingriff" 3 "Achsdifferenzdrehzahl" 4 "Bauteilschutz" 5 "Rennstart_Fahrbarkeit" ;
VAL_ 267 MO_Status_MinDrzEingriff_sek 0 "kein_Eingriff" 1 "Schalteingriff" 2 "ESP_Eingriff" 3 "Achsdifferenzdrehzahl" 4 "Bauteilschutz" 5 "Rennstart_Fahrbarkeit" ;
VAL_ 267 MO_Status_MaxDrzEingriff_sek 0 "kein_Eingriff" 1 "Schalteingriff" 2 "ESP_Eingriff" 3 "Achsdifferenzdrehzahl" 4 "Bauteilschutz" 5 "Rennstart_Fahrbarkeit" ;
VAL_ 267 TSK_SRBM_max_Gradient 126 "Init" 127 "Fehler" ;
VAL_ 330 MO_Hochschaltdrehz 0 "keine_manuelle_Hochschaltung" 4095 "Fehler" ;
VAL_ 330 MO_Anzeige_Verbr_Einheit 0 "l_h" 1 "kg_h" ;
VAL_ 330 MO_Schaltblitz_Anz 101 "blinkende_Anzeige" 126 "Init_Funktion_nicht_aktiv" 127 "Fehler" ;
VAL_ 330 MO_Anzeige_Drehmoment 2046 "nicht_verbaut" 2047 "Fehler" ;
VAL_ 330 MO_Anzeige_Leistung 2046 "nicht_verbaut" 2047 "Fehler" ;
VAL_ 330 MO_rel_Ladedruck 255 "Fehler" ;
VAL_ 330 MO_Istgang 0 "kein_Gang_eingelegt" 1 "Gang_1" 2 "Gang_2" 3 "Gang_3" 4 "Gang_4" 5 "Gang_5" 6 "Gang_6" 7 "Gang_7" 8 "Gang_8" 9 "Gang_9" ;
VAL_ 330 MO_Sollgang 0 "keine_Empfehlung" 1 "Gang_1" 2 "Gang_2" 3 "Gang_3" 4 "Gang_4" 5 "Gang_5" 6 "Gang_6" 7 "Gang_7" 8 "Gang_8" 9 "Gang_9" 15 "Neutralgang" ;
VAL_ 330 MO_Oeldruck 254 "Init" 255 "Fehler" ;
VAL_ 330 MO_Anzeigedrehz 4095 "reserviert" ;
VAL_ 330 MO_Effizienzmodus 0 "nicht_im_Effizienz_Modus" 1 "Effizienz_Modus" ;
VAL_ 330 MO_Fehler_Oeldrucksensor 0 "kein_Fehler" 1 "Fehler" ;
VAL_ 330 MO_Schaltempf_verfbar 0 "nicht_verfuegbar" 1 "verfuegbar" ;
VAL_ 330 MO_Ladedruck 511 "Fehler" ;
VAL_ 330 MO_KVS_Ueberlauf 0 "kein Ueberlauf" 1 "Kraftstoffverbrauchsignale mindestens 1x übergelaufen" ;
VAL_ 330 MO_ePowermeter 0 "Init_keine_Anzeige" 254 "Funktion_deaktiv_Anzeige_ausgegraut" 255 "Fehler_keine_Anzeige" ;
VAL_ 330 MO_ePerformance 0 "Init" 254 "Funktion_deaktiv_Anz_ausgegraut" 255 "Fehler" ;
VAL_ 330 MO_Zust_Antrieb 0 "VM bzw. Brennstoffz. aktiv" 1 "EM aktiv" 2 "VM bzw. Brennstoffz. u. EM aktiv" 3 "Segeln oder Reku aktiv" ;
VAL_ 330 MO_Zust_Betriebsstrategie 0 "Kein Hybrid" 1 "Depleting" 2 "Soft-Depleting " 3 "Sustaining" 4 "Increasing" 5 "Fremdgesteuert" ;
VAL_ 330 Ladezustand_02 254 "Init" 255 "Fehler" ;
VAL_ 330 Ladezustand_gering 0 "keine_Anzeige" 1 "Ladezustand_gering" 2 "Batterie_fast_leer" 3 "Batterie_leer" ;
VAL_ 330 MO_Powermeter_Elm_02 0 "nicht_verbaut" 4094 "Init" ;
VAL_ 330 MO_Powermeter 4093 "Off" ;
VAL_ 330 MO_OnePedalDriving_Warnung 0 "keine_Warnung" 1 "Warnstufe_1" ;
